VERSION "HNPBNNNYNNNNNNNNNNNNNNNNNNNNNNNNYNYYYYYYYY>4>%%%/4>'%**4YYY///"

NS_ :

BS_:

BU_: TPM TCM SCCM RF_HUB PTS ORC IC HaLF ETM ESM ESC EPS ECM Diagnost DTCM DASM CBC AFLS ADCM

BO_ 999 BU_NET_CFG_PT: 8 RF_HUB
 SG_ BU_NET_CFG_STAT_PT : 0|2@1+ (1,0) [0|0] ""  CBC
 SG_ BU_NetCfg_ACC : 2|1@1+ (1,0) [0|0] ""  CBC
 SG_ BU_NetCfg_ADCM : 3|1@1+ (1,0) [0|0] ""  CBC
 SG_ BU_NetCfg_AHLM : 4|1@1+ (1,0) [0|0] ""  CBC
 SG_ BU_NetCfg_VSIM_C : 5|1@1+ (1,0) [0|0] ""  CBC
 SG_ BU_NetCfg_ASCM : 6|1@1+ (1,0) [0|0] ""  CBC
 SG_ BU_NetCfg_CBC_PT : 7|1@1+ (1,0) [0|0] ""  CBC
 SG_ BU_NetCfg_DTCM : 8|1@1+ (1,0) [0|0] ""  CBC
 SG_ BU_NetCfg_ECM : 9|1@1+ (1,0) [0|0] ""  CBC
 SG_ BU_NetCfg_EPS : 10|1@1+ (1,0) [0|0] ""  CBC
 SG_ BU_NetCfg_ESM : 11|1@1+ (1,0) [0|0] ""  CBC
 SG_ BU_NetCfg_ESC : 12|1@1+ (1,0) [0|0] ""  CBC
 SG_ BU_NetCfg_EPB : 13|1@1+ (1,0) [0|0] ""  CBC
 SG_ BU_NetCfg_RF_HUB : 14|1@1+ (1,0) [0|0] ""  CBC
 SG_ BU_NetCfg_IC : 15|1@1+ (1,0) [0|0] ""  CBC
 SG_ BU_NetCfg_DASM : 16|1@1+ (1,0) [0|0] ""  CBC
 SG_ BU_NetCfg_FDCM : 17|1@1+ (1,0) [0|0] ""  CBC
 SG_ BU_NetCfg_EPPM : 18|1@1+ (1,0) [0|0] ""  CBC
 SG_ BU_NetCfg_ORC : 19|1@1+ (1,0) [0|0] ""  CBC
 SG_ BU_NetCfg_PTS : 20|1@1+ (1,0) [0|0] ""  CBC
 SG_ BU_NetCfg_RBT_DR : 21|1@1+ (1,0) [0|0] ""  CBC
 SG_ BU_NetCfg_RBT_PASS : 22|1@1+ (1,0) [0|0] ""  CBC
 SG_ BU_NetCfg_SCCM : 23|1@1+ (1,0) [0|0] ""  CBC
 SG_ BU_NetCfg_ELSD : 24|1@1+ (1,0) [0|0] ""  CBC
 SG_ BU_NetCfg_TCM : 25|1@1+ (1,0) [0|0] ""  CBC
 SG_ BU_NetCfg_TPM : 26|1@1+ (1,0) [0|0] ""  CBC
 SG_ BU_NetCfg_PASS_PT : 27|1@1+ (1,0) [0|0] ""  CBC
 SG_ BU_NetCfg_AFLS : 28|1@1+ (1,0) [0|0] ""  CBC
 SG_ BU_NetCfg_ITBM : 29|1@1+ (1,0) [0|0] ""  CBC
 SG_ BU_NetCfg_OCM : 30|1@1+ (1,0) [0|0] ""  CBC
 SG_ BU_NetCfg_HaLF : 31|1@1+ (1,0) [0|0] ""  CBC
 SG_ BU_NetCfg_ANC : 39|1@1+ (1,0) [0|0] ""  CBC

BO_ 1000 VehCfg1: 8 CBC
 SG_ VC_VehCfg1_Stat : 0|2@1+ (1,0) [0|0] ""  HaLF,ORC,ADCM,DTCM,ESM,TCM,ECM,DASM,ESC,SCCM,EPS,AFLS,TPM,PTS,IC,RF_HUB
 SG_ VC_MODEL_YEAR : 2|6@1+ (1,2000) [2000|2062] "model-year"  HaLF,ORC,ADCM,DTCM,ESM,TCM,ECM,DASM,ESC,SCCM,EPS,AFLS,TPM,PTS,IC,RF_HUB
 SG_ VC_VEH_LINE : 8|8@1+ (1,0) [0|0] ""  HaLF,ORC,ADCM,DTCM,ESM,TCM,ECM,DASM,ESC,SCCM,EPS,AFLS,TPM,PTS,IC,RF_HUB
 SG_ VC_COUNTRY : 16|5@1+ (1,0) [0|0] ""  HaLF,ORC,ADCM,DTCM,ESM,TCM,ECM,DASM,ESC,SCCM,EPS,AFLS,TPM,PTS,IC,RF_HUB
 SG_ VC_LHD_RHD : 21|2@1+ (1,0) [0|0] ""  HaLF,ORC,DTCM,ESM,DASM,ESC,AFLS,IC,RF_HUB
 SG_ VC_RemStPrsnt : 23|1@1+ (1,0) [0|0] ""  TCM,TPM,IC,RF_HUB
 SG_ VC_XWD : 24|2@1+ (1,0) [0|0] ""  HaLF,ORC,DTCM,ESM,TCM,ECM,DASM,ESC,EPS,IC,RF_HUB
 SG_ VC_EmodePrsnt : 26|1@1+ (1,0) [0|0] ""  TCM,RF_HUB
 SG_ VC_AUTO_HB : 27|1@1+ (1,0) [0|0] ""  IC,RF_HUB
 SG_ VC_BODY_STYLE : 28|4@1+ (1,0) [0|0] ""  HaLF,ORC,ADCM,DTCM,ESM,TCM,ECM,DASM,ESC,SCCM,EPS,AFLS,TPM,PTS,IC,RF_HUB
 SG_ VC_MAX_VEH_SPD : 32|8@1+ (2,0) [0|506] "kph"  ECM,DASM,RF_HUB
 SG_ VC_ShftrTyp : 40|4@1+ (1,0) [0|0] ""  ESM,TCM,ECM,IC,RF_HUB
 SG_ VC_PTS_DispTyp : 44|3@1+ (1,0) [0|0] ""  PTS,RF_HUB
 SG_ VC_PP_Prsnt : 47|1@1+ (1,0) [0|0] ""  IC,RF_HUB
 SG_ VC_SpecialPKG : 48|8@1+ (1,0) [1|254] ""  ORC,IC,RF_HUB
 SG_ VC_HdRstPrsnt : 56|1@1+ (1,0) [0|0] ""  RF_HUB
 SG_ VC_SCR_Prsnt : 57|1@1+ (1,0) [0|0] ""  ECM,IC,RF_HUB
 SG_ VC_PTS_Config : 58|2@1+ (1,0) [0|0] ""  PTS,IC,RF_HUB
 SG_ VC_RVCM_Prsnt : 60|1@1+ (1,0) [0|0] ""  RF_HUB
 SG_ VC_CHMCM_Prsnt : 61|1@1+ (1,0) [0|0] ""  RF_HUB
 SG_ VC_HDC_Prsnt : 62|1@1+ (1,0) [0|0] ""  ESC,IC,RF_HUB
 SG_ VC_SSC_Prsnt : 63|1@1+ (1,0) [0|0] ""  ESC,IC,RF_HUB

BO_ 1001 VehCfg2: 8 CBC
 SG_ VC_VehCfg2_Stat : 0|2@1+ (1,0) [0|0] ""  ORC,ADCM,TCM,ECM,DASM,ESC,SCCM,EPS,TPM,IC,RF_HUB
 SG_ VC_PwrIvtrTyp : 2|2@1+ (1,0) [0|0] ""  RF_HUB
 SG_ VC_ThatchamPrsnt : 4|1@1+ (1,0) [0|0] ""  IC,RF_HUB
 SG_ VC_RunFlatTirePrsnt : 5|1@1+ (1,0) [0|0] ""  TPM,IC,RF_HUB
 SG_ VC_MaseratiMd : 6|2@1+ (1,0) [0|0] ""  TCM,RF_HUB
 SG_ VC_PADS_Prsnt : 8|1@1+ (1,0) [0|0] ""  ORC,RF_HUB
 SG_ VC_RainSnsPrsnt : 9|1@1+ (1,0) [0|0] ""  IC,RF_HUB
 SG_ VC_SKIM_PRSNT : 10|1@1+ (1,0) [0|0] ""  RF_HUB
 SG_ VC_AC_Prsnt : 11|1@1+ (1,0) [0|0] ""  RF_HUB
 SG_ VC_CRUISE_PRSNT : 12|1@1+ (1,0) [0|0] ""  TCM,DASM,SCCM,IC,RF_HUB
 SG_ VC_FG_PRSNT : 13|1@1+ (1,0) [0|0] ""  IC,RF_HUB
 SG_ VC_FULL_SPARE : 14|1@1+ (1,0) [0|0] ""  TPM,RF_HUB
 SG_ VC_OffRoad : 15|1@1+ (1,0) [0|0] ""  IC,RF_HUB
 SG_ VC_SpecialPKG_IC : 16|8@1+ (1,0) [0|0] ""  IC,RF_HUB
 SG_ VC_ECO_Indicator : 24|1@1+ (1,0) [0|0] ""  IC,RF_HUB
 SG_ VC_DRVMD_Prsnt : 25|1@1+ (1,0) [0|0] ""  ADCM,ECM,ESC,EPS,RF_HUB
 SG_ VC_MemoryDRVMD_Prsnt : 26|1@1+ (1,0) [0|0] ""  ADCM,ECM,ESC,EPS,RF_HUB
 SG_ VC_ESCDrvMd_Prsnt : 27|1@1+ (1,0) [0|0] ""  ESC,IC,RF_HUB
 SG_ VC_EngPowerDrvMd_Prsnt : 28|1@1+ (1,0) [0|0] ""  ECM,IC,RF_HUB
 SG_ VC_SecPrkPrsnt : 29|1@1+ (1,0) [0|0] ""  IC,RF_HUB
 SG_ VC_ShftInd_Prsnt : 30|2@1+ (1,0) [0|0] ""  ECM,IC,RF_HUB
 SG_ VC_MaxLdPressRrTr : 32|8@1+ (1,0) [0|126] "psi"  TPM,IC,RF_HUB
 SG_ VC_MaxLdPressFtTr : 40|8@1+ (1,0) [0|126] "psi"  TPM,IC,RF_HUB
 SG_ VC_LgtLdPressRrTr : 48|8@1+ (1,0) [0|126] "psi"  TPM,IC,RF_HUB
 SG_ VC_LgtLdPressFtTr : 56|8@1+ (1,0) [0|126] "psi"  TPM,IC,RF_HUB

BO_ 1002 VehCfg3: 8 CBC
 SG_ VC_VehCfg3_Stat : 0|2@1+ (1,0) [0|0] ""  HaLF,ORC,DTCM,TCM,DASM,ESC,SCCM,EPS,TPM,PTS,IC,RF_HUB
 SG_ VC_POLICE : 2|1@1+ (1,0) [0|0] ""  ORC,IC,RF_HUB
 SG_ VC_PWR_LFT_GT : 3|1@1+ (1,0) [0|0] ""  RF_HUB
 SG_ VC_PWR_RT_SLDR : 4|1@1+ (1,0) [0|0] ""  RF_HUB
 SG_ VC_PWR_LT_SLDR : 5|1@1+ (1,0) [0|0] ""  RF_HUB
 SG_ VC_RKE_PRSNT : 6|1@1+ (1,0) [0|0] ""  IC,RF_HUB
 SG_ VC_SunShade_Present : 7|1@1+ (1,0) [0|0] ""  RF_HUB
 SG_ VC_TcaseTyp : 8|4@1+ (1,0) [0|0] ""  DTCM,ESC,RF_HUB
 SG_ VC_WHL_BASE : 12|2@1+ (1,0) [0|0] ""  ORC,RF_HUB
 SG_ VC_FOBIKsafeENBL : 14|1@1+ (1,0) [0|0] ""  RF_HUB
 SG_ VC_ELV_Prsnt : 15|1@1+ (1,0) [0|0] ""  RF_HUB
 SG_ VC_FUEL_CAP : 16|8@1+ (1,36) [36|290] "liters"  IC,RF_HUB
 SG_ VC_WIN_EXPR_FEAT : 24|2@1+ (1,0) [0|0] ""  RF_HUB
 SG_ VC_ADJ_PDL_PRSNT : 26|1@1+ (1,0) [0|0] ""  RF_HUB
 SG_ VC_AUTO_HL : 27|1@1+ (1,0) [0|0] ""  IC,RF_HUB
 SG_ VC_DrAlrPrsnt : 28|1@1+ (1,0) [0|0] ""  IC,RF_HUB
 SG_ VC_DualFuelSens : 29|1@1+ (1,0) [0|0] ""  IC,RF_HUB
 SG_ VC_SRT_PRSNT : 30|1@1+ (1,0) [0|0] ""  ORC,TCM,TPM,PTS,IC,RF_HUB
 SG_ VC_DSBL_CLK_DISP : 31|1@1+ (1,0) [0|0] ""  IC,RF_HUB
 SG_ VC_ChassisType : 32|7@1+ (1,0) [0|126] ""  ORC,DTCM,ESC,EPS,PTS,RF_HUB
 SG_ VC_TEMP_DISP : 39|1@1+ (1,0) [0|0] ""  IC,RF_HUB
 SG_ VC_HVAC_Config : 40|4@1+ (1,0) [0|0] ""  RF_HUB
 SG_ VC_VEH_BRAND : 44|4@1+ (1,0) [0|0] ""  TPM,PTS,IC,RF_HUB
 SG_ VC_CMP_DISP : 48|1@1+ (1,0) [0|0] ""  IC,RF_HUB
 SG_ VC_IntEC_MIRR : 49|1@1+ (1,0) [0|0] ""  RF_HUB
 SG_ VC_ESCL_PRSNT : 50|1@1+ (1,0) [0|0] ""  RF_HUB
 SG_ VC_HID_HL : 51|1@1+ (1,0) [0|0] ""  RF_HUB
 SG_ VC_SecLkPrsnt : 52|1@1+ (1,0) [0|0] ""  RF_HUB
 SG_ VC_Liftgate_Trunk : 53|2@1+ (1,0) [0|0] ""  IC,RF_HUB
 SG_ VC_CMS : 55|1@1+ (1,0) [0|0] ""  DASM,RF_HUB
 SG_ VC_FCW : 56|1@1+ (1,0) [0|0] ""  HaLF,DASM,RF_HUB
 SG_ VC_Base_TPM : 57|1@1+ (1,0) [0|0] ""  TPM,IC,RF_HUB
 SG_ VC_Prem_TPM : 58|1@1+ (1,0) [0|0] ""  TPM,IC,RF_HUB
 SG_ VC_PDDL_PRSNT : 59|1@1+ (1,0) [0|0] ""  TCM,SCCM,IC,RF_HUB
 SG_ VC_SPORT_PRSNT : 60|1@1+ (1,0) [0|0] ""  TCM,IC,RF_HUB
 SG_ VC_AutoParkPrsnt : 61|1@1+ (1,0) [0|0] ""  IC,RF_HUB
 SG_ VC_PE_Prsnt : 62|1@1+ (1,0) [0|0] ""  IC,RF_HUB
 SG_ VC_KG_Prsnt : 63|1@1+ (1,0) [0|0] ""  TCM,IC,RF_HUB

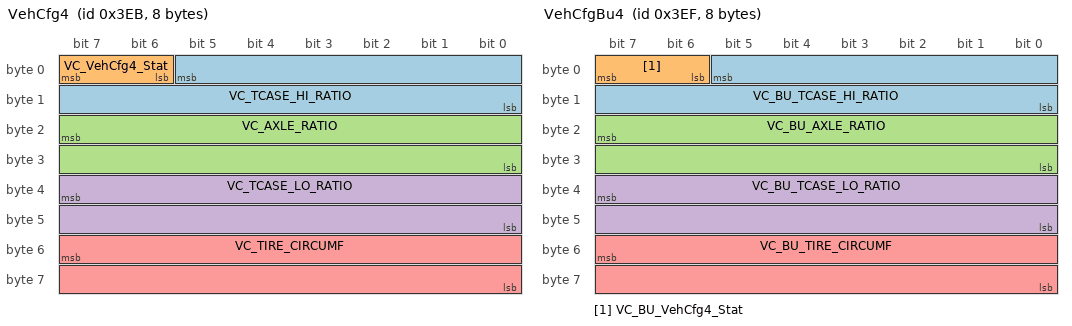
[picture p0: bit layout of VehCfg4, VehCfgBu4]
BO_ 1003 VehCfg4: 8 CBC
 SG_ VC_TCASE_HI_RATIO : 5|14@0+ (0.001,0) [0|16.382] ""  TCM,ECM,ESC,RF_HUB
 SG_ VC_VehCfg4_Stat : 6|2@1+ (1,0) [0|0] ""  ORC,DTCM,TCM,ECM,DASM,ESC,EPS,RF_HUB
 SG_ VC_AXLE_RATIO : 23|16@0+ (0.001,0) [0|65.534] ""  DTCM,TCM,ECM,DASM,ESC,RF_HUB
 SG_ VC_TCASE_LO_RATIO : 39|16@0+ (0.001,0) [0|65.534] ""  TCM,ECM,ESC,RF_HUB
 SG_ VC_TIRE_CIRCUMF : 55|16@0+ (1,0) [0|65534] "mm"  ORC,DTCM,ECM,DASM,ESC,EPS,RF_HUB

BO_ 1004 VehCfgBu1: 8 RF_HUB
 SG_ VC_BU_VehCfg1_Stat : 0|2@1+ (1,0) [0|0] ""  CBC
 SG_ VC_BU_MODEL_YEAR : 2|6@1+ (1,2000) [2000|2062] "model-year"  CBC
 SG_ VC_BU_VEH_LINE : 8|8@1+ (1,0) [0|0] ""  CBC
 SG_ VC_BU_COUNTRY : 16|5@1+ (1,0) [0|0] ""  CBC
 SG_ VC_BU_LHD_RHD : 21|2@1+ (1,0) [0|0] ""  CBC
 SG_ VC_BU_RemStPrsnt : 23|1@1+ (1,0) [0|0] ""  CBC
 SG_ VC_BU_XWD : 24|2@1+ (1,0) [0|0] ""  CBC
 SG_ VC_BU_EmodePrsnt : 26|1@1+ (1,0) [0|0] ""  CBC
 SG_ VC_BU_AUTO_HB : 27|1@1+ (1,0) [0|0] ""  CBC
 SG_ VC_BU_BODY_STYLE : 28|4@1+ (1,0) [0|0] ""  CBC
 SG_ VC_BU_MAX_VEH_SPD : 32|8@1+ (2,0) [0|506] "kph"  CBC
 SG_ VC_BU_ShftrTyp : 40|4@1+ (1,0) [0|0] ""  CBC
 SG_ VC_BU_PTS_DispTyp : 44|3@1+ (1,0) [0|0] ""  CBC
 SG_ VC_BU_PP_Prsnt : 47|1@1+ (1,0) [0|0] ""  CBC
 SG_ VC_BU_SpecialPKG : 48|8@1+ (1,0) [1|254] ""  CBC
 SG_ VC_BU_HdRstPrsnt : 56|1@1+ (1,0) [0|0] ""  CBC
 SG_ VC_BU_SCR_Prsnt : 57|1@1+ (1,0) [0|0] ""  CBC
 SG_ VC_BU_PTS_Config : 58|2@1+ (1,0) [0|0] ""  CBC
 SG_ VC_BU_RVCM_Prsnt : 60|1@1+ (1,0) [0|0] ""  CBC
 SG_ VC_BU_CHMCM_Prsnt : 61|1@1+ (1,0) [0|0] ""  CBC
 SG_ VC_BU_HDC_Prsnt : 62|1@1+ (1,0) [0|0] ""  CBC
 SG_ VC_BU_SSC_Prsnt : 63|1@1+ (1,0) [0|0] ""  CBC

BO_ 1005 VehCfgBu2: 8 RF_HUB
 SG_ VC_BU_VehCfg2_Stat : 0|2@1+ (1,0) [0|0] ""  CBC
 SG_ VC_BU_PwrIvtrTyp : 2|2@1+ (1,0) [0|0] ""  CBC
 SG_ VC_BU_ThatchamPrsnt : 4|1@1+ (1,0) [0|0] ""  CBC
 SG_ VC_BU_RunFlatTirePrsnt : 5|1@1+ (1,0) [0|0] ""  CBC
 SG_ VC_BU_MaseratiMd : 6|2@1+ (1,0) [0|0] ""  CBC
 SG_ VC_BU_PADS_Prsnt : 8|1@1+ (1,0) [0|0] ""  CBC
 SG_ VC_BU_RainSnsPrsnt : 9|1@1+ (1,0) [0|0] ""  CBC
 SG_ VC_BU_SKIM_PRSNT : 10|1@1+ (1,0) [0|0] ""  CBC
 SG_ VC_BU_AC_Prsnt : 11|1@1+ (1,0) [0|0] ""  CBC
 SG_ VC_BU_CRUISE_PRSNT : 12|1@1+ (1,0) [0|0] ""  CBC
 SG_ VC_BU_FG_PRSNT : 13|1@1+ (1,0) [0|0] ""  CBC
 SG_ VC_BU_FULL_SPARE : 14|1@1+ (1,0) [0|0] ""  CBC
 SG_ VC_BU_OffRoad : 15|1@1+ (1,0) [0|0] ""  CBC
 SG_ VC_BU_SpecialPKG_IC : 16|8@1+ (1,0) [0|0] ""  CBC
 SG_ VC_BU_ECO_Indicator : 24|1@1+ (1,0) [0|0] ""  CBC
 SG_ VC_BU_DRVMD_Prsnt : 25|1@1+ (1,0) [0|0] ""  CBC
 SG_ VC_BU_MemoryDRVMD_Prsnt : 26|1@1+ (1,0) [0|0] ""  CBC
 SG_ VC_BU_ESCDrvMd_Prsnt : 27|1@1+ (1,0) [0|0] ""  CBC
 SG_ VC_BU_EngPowerDrvMd_Prsnt : 28|1@1+ (1,0) [0|0] ""  CBC
 SG_ VC_BU_SecPrkPrsnt : 29|1@1+ (1,0) [0|0] ""  CBC
 SG_ VC_BU_ShftInd_Prsnt : 30|2@1+ (1,0) [0|0] ""  CBC
 SG_ VC_BU_MaxLdPressRrTr : 32|8@1+ (1,0) [0|126] "psi"  CBC
 SG_ VC_BU_MaxLdPressFtTr : 40|8@1+ (1,0) [0|126] "psi"  CBC
 SG_ VC_BU_LgtLdPressRrTr : 48|8@1+ (1,0) [0|126] "psi"  CBC
 SG_ VC_BU_LgtLdPressFtTr : 56|8@1+ (1,0) [0|126] "psi"  CBC

BO_ 1006 VehCfgBu3: 8 RF_HUB
 SG_ VC_BU_VehCfg3_Stat : 0|2@1+ (1,0) [0|0] ""  CBC
 SG_ VC_BU_POLICE : 2|1@1+ (1,0) [0|0] ""  CBC
 SG_ VC_BU_PWR_LFT_GT : 3|1@1+ (1,0) [0|0] ""  CBC
 SG_ VC_BU_PWR_RT_SLDR : 4|1@1+ (1,0) [0|0] ""  CBC
 SG_ VC_BU_PWR_LT_SLDR : 5|1@1+ (1,0) [0|0] ""  CBC
 SG_ VC_BU_RKE_PRSNT : 6|1@1+ (1,0) [0|0] ""  CBC
 SG_ VC_BU_SunShade_Present : 7|1@1+ (1,0) [0|0] ""  CBC
 SG_ VC_BU_TcaseTyp : 8|4@1+ (1,0) [0|0] ""  CBC
 SG_ VC_BU_WHL_BASE : 12|2@1+ (1,0) [0|0] ""  CBC
 SG_ VC_BU_FOBIKsafeENBL : 14|1@1+ (1,0) [0|0] ""  CBC
 SG_ VC_BU_ELV_PRSNT : 15|1@1+ (1,0) [0|0] ""  CBC
 SG_ VC_BU_FUEL_CAP : 16|8@1+ (1,36) [36|290] "liters"  CBC
 SG_ VC_BU_WIN_EXPR_FEAT : 24|2@1+ (1,0) [0|0] ""  CBC
 SG_ VC_BU_ADJ_PDL_PRSNT : 26|1@1+ (1,0) [0|0] ""  CBC
 SG_ VC_BU_AUTO_HL : 27|1@1+ (1,0) [0|0] ""  CBC
 SG_ VC_BU_DrAlrPrsnt : 28|1@1+ (1,0) [0|0] ""  CBC
 SG_ VC_BU_DualFuelSens : 29|1@1+ (1,0) [0|0] ""  CBC
 SG_ VC_BU_SRT_PRSNT : 30|1@1+ (1,0) [0|0] ""  CBC
 SG_ VC_BU_DSBL_CLK_DISP : 31|1@1+ (1,0) [0|0] ""  CBC
 SG_ VC_BU_ChassisType : 32|7@1+ (1,0) [0|126] ""  CBC
 SG_ VC_BU_TEMP_DISP : 39|1@1+ (1,0) [0|0] ""  CBC
 SG_ VC_BU_HVAC_Config : 40|4@1+ (1,0) [0|0] ""  CBC
 SG_ VC_BU_VEH_BRAND : 44|4@1+ (1,0) [0|0] ""  CBC
 SG_ VC_BU_CMP_DISP : 48|1@1+ (1,0) [0|0] ""  CBC
 SG_ VC_BU_IntEC_MIRR : 49|1@1+ (1,0) [0|0] ""  CBC
 SG_ VC_BU_ESCL_Prsnt : 50|1@1+ (1,0) [0|0] ""  CBC
 SG_ VC_BU_HID_HL : 51|1@1+ (1,0) [0|0] ""  CBC
 SG_ VC_BU_SecLkPrsnt : 52|1@1+ (1,0) [0|0] ""  CBC
 SG_ VC_BU_Liftgate_Trunk : 53|2@1+ (1,0) [0|0] ""  CBC
 SG_ VC_BU_CMS : 55|1@1+ (1,0) [0|0] ""  CBC
 SG_ VC_BU_FCW : 56|1@1+ (1,0) [0|0] ""  CBC
 SG_ VC_BU_Base_TPM : 57|1@1+ (1,0) [0|0] ""  CBC
 SG_ VC_BU_Prem_TPM : 58|1@1+ (1,0) [0|0] ""  CBC
 SG_ VC_BU_PDDL_PRSNT : 59|1@1+ (1,0) [0|0] ""  CBC
 SG_ VC_BU_SPORT_PRSNT : 60|1@1+ (1,0) [0|0] ""  CBC
 SG_ VC_BU_AutoParkPrsnt : 61|1@1+ (1,0) [0|0] ""  CBC
 SG_ VC_BU_PE_Prsnt : 62|1@1+ (1,0) [0|0] ""  CBC
 SG_ VC_BU_KG_Prsnt : 63|1@1+ (1,0) [0|0] ""  CBC

BO_ 1007 VehCfgBu4: 8 RF_HUB
 SG_ VC_BU_TCASE_HI_RATIO : 5|14@0+ (0.001,0) [0|16.382] ""  CBC
 SG_ VC_BU_VehCfg4_Stat : 6|2@1+ (1,0) [0|0] ""  CBC
 SG_ VC_BU_AXLE_RATIO : 23|16@0+ (0.001,0) [0|65.534] ""  CBC
 SG_ VC_BU_TCASE_LO_RATIO : 39|16@0+ (0.001,0) [0|65.534] ""  CBC
 SG_ VC_BU_TIRE_CIRCUMF : 55|16@0+ (1,0) [0|65534] "mm"  CBC

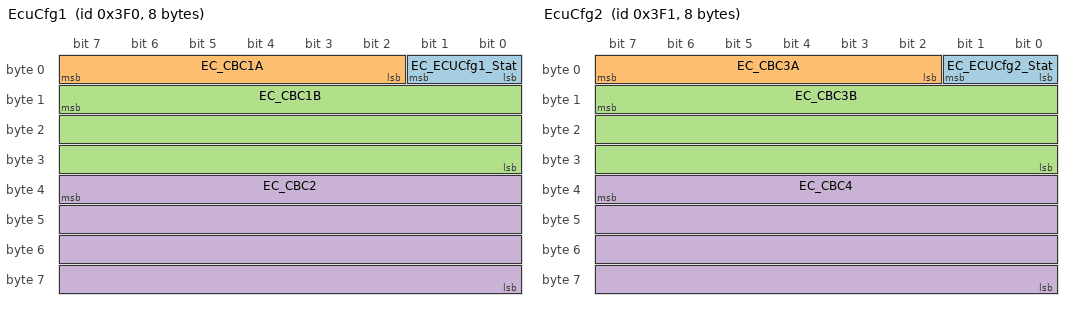
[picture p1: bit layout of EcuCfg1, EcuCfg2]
BO_ 1008 EcuCfg1: 8 CBC
 SG_ EC_ECUCfg1_Stat : 0|2@1+ (1,0) [0|0] ""  RF_HUB
 SG_ EC_CBC1A : 2|6@1+ (1,0) [0|0] ""  RF_HUB
 SG_ EC_CBC1B : 15|24@0+ (1,0) [0|0] ""  RF_HUB
 SG_ EC_CBC2 : 39|32@0+ (1,0) [0|0] ""  RF_HUB

BO_ 1009 EcuCfg2: 8 CBC
 SG_ EC_ECUCfg2_Stat : 0|2@1+ (1,0) [0|0] ""  RF_HUB
 SG_ EC_CBC3A : 2|6@1+ (1,0) [0|0] ""  RF_HUB
 SG_ EC_CBC3B : 15|24@0+ (1,0) [0|0] ""  RF_HUB
 SG_ EC_CBC4 : 39|32@0+ (1,0) [0|0] ""  RF_HUB

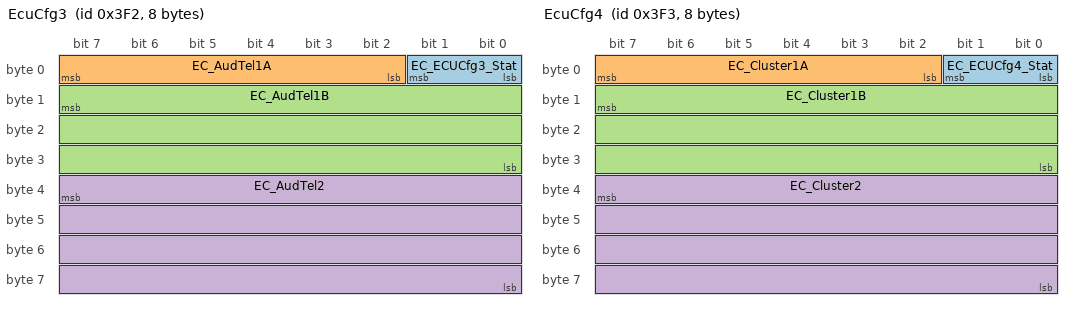
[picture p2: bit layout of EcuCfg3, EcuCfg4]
BO_ 1010 EcuCfg3: 8 CBC
 SG_ EC_ECUCfg3_Stat : 0|2@1+ (1,0) [0|0] ""  RF_HUB
 SG_ EC_AudTel1A : 2|6@1+ (1,0) [0|0] ""  RF_HUB
 SG_ EC_AudTel1B : 15|24@0+ (1,0) [0|0] ""  RF_HUB
 SG_ EC_AudTel2 : 39|32@0+ (1,0) [0|0] ""  RF_HUB

BO_ 1011 EcuCfg4: 8 CBC
 SG_ EC_ECUCfg4_Stat : 0|2@1+ (1,0) [0|0] ""  IC,RF_HUB
 SG_ EC_Cluster1A : 2|6@1+ (1,0) [0|0] ""  IC,RF_HUB
 SG_ EC_Cluster1B : 15|24@0+ (1,0) [0|0] ""  IC,RF_HUB
 SG_ EC_Cluster2 : 39|32@0+ (1,0) [0|0] ""  IC,RF_HUB

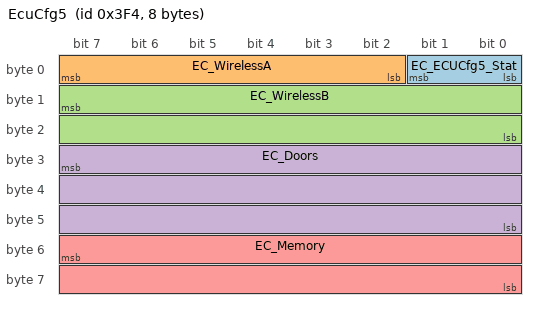
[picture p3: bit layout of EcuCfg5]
BO_ 1012 EcuCfg5: 8 CBC
 SG_ EC_ECUCfg5_Stat : 0|2@1+ (1,0) [0|0] ""  RF_HUB
 SG_ EC_WirelessA : 2|6@1+ (1,0) [0|0] ""  RF_HUB
 SG_ EC_WirelessB : 15|16@0+ (1,0) [0|0] ""  RF_HUB
 SG_ EC_Doors : 31|24@0+ (1,0) [0|0] ""  RF_HUB
 SG_ EC_Memory : 55|16@0+ (1,0) [0|0] ""  RF_HUB

CM_ SG_ 999 BU_NET_CFG_STAT_PT "Backup for network configuration status";
CM_ SG_ 999 BU_NetCfg_ACC "Backup for Active Cruise Control (1=present)";
CM_ SG_ 999 BU_NetCfg_ADCM "Backup for Active Damping Control Module (1=present)";
CM_ SG_ 999 BU_NetCfg_AHLM "Backup for Automatic Headlamp Leveling Module (1=present)";
CM_ SG_ 999 BU_NetCfg_VSIM_C "Backup for Vehicle System Interface Module (1=present)";
CM_ SG_ 999 BU_NetCfg_ASCM "Backup for Air Suspension Control Module (1=present)";
CM_ SG_ 999 BU_NetCfg_CBC_PT "Backup for Common Body Controller PT Bus (1=present)";
CM_ SG_ 999 BU_NetCfg_DTCM "Backup for Drivetrain Control Module (1=present)";
CM_ SG_ 999 BU_NetCfg_ECM "Backup for Engine Control Module (1=present)";
CM_ SG_ 999 BU_NetCfg_EPS "Backup for Electric Power Steering (1=present)";
CM_ SG_ 999 BU_NetCfg_ESM "Backup for Electronic Shift Module (1=present)";
CM_ SG_ 999 BU_NetCfg_ESC "Backup for Electronic Stability Module / Anti-Lock Brake (1=present)";
CM_ SG_ 999 BU_NetCfg_EPB "Backup for Electric Park Brake Module (1=present)";
CM_ SG_ 999 BU_NetCfg_RF_HUB "Backup for RF HUB Node (1=present)";
CM_ SG_ 999 BU_NetCfg_IC "Backup for Instrument Cluster (1=present)";
CM_ SG_ 999 BU_NetCfg_DASM "Backup for Driver Assistance System Module (1=present)";
CM_ SG_ 999 BU_NetCfg_FDCM "Backup for Final Drive Control Module (1=present)";
CM_ SG_ 999 BU_NetCfg_EPPM "Backup for  Elect. Pedestrian protection module (1=present)";
CM_ SG_ 999 BU_NetCfg_ORC "Backup for Occupant Restraint Controller (1=present)";
CM_ SG_ 999 BU_NetCfg_PTS "Backup for Parktronics System (1=present)";
CM_ SG_ 999 BU_NetCfg_RBT_DR "Backup for Belt Pre-Tensioner Driver (1=present)";
CM_ SG_ 999 BU_NetCfg_RBT_PASS "Backup for Belt Pre-Tensioner Passenger (1=present)";
CM_ SG_ 999 BU_NetCfg_SCCM "Backup for Steering Column Control Module (1=present)";
CM_ SG_ 999 BU_NetCfg_ELSD "Backup for Electric Limited Slip Differential (1=present)";
CM_ SG_ 999 BU_NetCfg_TCM "Backup for Automatic Transmission Controller (1=present)";
CM_ SG_ 999 BU_NetCfg_TPM "Backup for Tire Pressure Monitor (1=present)";
CM_ SG_ 999 BU_NetCfg_PASS_PT "Backup for Personal Assistant Safety System Module PT Bus (1=present)";
CM_ SG_ 999 BU_NetCfg_AFLS "Backup for Advanced Front Lighting System (1=present)";
CM_ SG_ 999 BU_NetCfg_ITBM "Backup for Integrated Trailer Brake Module (1=present)";
CM_ SG_ 999 BU_NetCfg_OCM "Backup for Occupant Classification Module (1=present)";
CM_ SG_ 999 BU_NetCfg_HaLF "Backup for Haptic Lane Feedback module (1=present)";
CM_ SG_ 999 BU_NetCfg_ANC "Backup for Active Noise Cancellation (1=present)";
CM_ SG_ 1000 VC_VehCfg1_Stat "Configuration messages status 1";
CM_ SG_ 1000 VC_MODEL_YEAR "Model year";
CM_ SG_ 1000 VC_VEH_LINE "Vehicle line";
CM_ SG_ 1000 VC_COUNTRY "Country Code";
CM_ SG_ 1000 VC_LHD_RHD "Left/right hand drive";
CM_ SG_ 1000 VC_RemStPrsnt "Remote start present; present = [1]";
CM_ SG_ 1000 VC_XWD "Drive configuration";
CM_ SG_ 1000 VC_EmodePrsnt "E-Mode feature present; True = [1]";
CM_ SG_ 1000 VC_AUTO_HB "Auto Highbeam feature present; present = [1]";
CM_ SG_ 1000 VC_BODY_STYLE "Body style";
CM_ SG_ 1000 VC_MAX_VEH_SPD "Maximum vehicle speed";
CM_ SG_ 1000 VC_ShftrTyp "Shifter type";
CM_ SG_ 1000 VC_PTS_DispTyp "PTS display type and location";
CM_ SG_ 1000 VC_PP_Prsnt "Performance Pages Present (1=present)";
CM_ SG_ 1000 VC_SpecialPKG "Special sales code package";
CM_ SG_ 1000 VC_HdRstPrsnt "Headrest present; present = [1]";
CM_ SG_ 1000 VC_SCR_Prsnt "Urea/SCR system present; present = [1]";
CM_ SG_ 1000 VC_PTS_Config "Parktronics system configuration";
CM_ SG_ 1000 VC_RVCM_Prsnt "Rear view camera (1=present)";
CM_ SG_ 1000 VC_CHMCM_Prsnt "CHMSL camera (1=present)";
CM_ SG_ 1000 VC_HDC_Prsnt "Hill descent feature is present; present = [1]";
CM_ SG_ 1000 VC_SSC_Prsnt "Select speed control feature is present; present = [1]";
CM_ SG_ 1001 VC_VehCfg2_Stat "Configuration messages status 2";
CM_ SG_ 1001 VC_PwrIvtrTyp "Power inverter type";
CM_ SG_ 1001 VC_ThatchamPrsnt "Thatcham present; present = [1]";
CM_ SG_ 1001 VC_RunFlatTirePrsnt "Run flat tires present; present = [1]";
CM_ SG_ 1001 VC_MaseratiMd "Maserati vehicle mode";
CM_ SG_ 1001 VC_PADS_Prsnt "Pass. airbag disable switch present; present = [1]";
CM_ SG_ 1001 VC_RainSnsPrsnt "Rain sensor present; present = [1]";
CM_ SG_ 1001 VC_SKIM_PRSNT "SKIM system present; present = [1]";
CM_ SG_ 1001 VC_AC_Prsnt "Vehicle is equipped with air conditioning; present = [1]";
CM_ SG_ 1001 VC_CRUISE_PRSNT "Cruise feature is present; present = [1]";
CM_ SG_ 1001 VC_FG_PRSNT "Flipper glass present; present = [1]";
CM_ SG_ 1001 VC_FULL_SPARE "Full size spare; present = [1]";
CM_ SG_ 1001 VC_OffRoad "Off road capable; present = [1]";
CM_ SG_ 1001 VC_SpecialPKG_IC "Special sales code package";
CM_ SG_ 1001 VC_ECO_Indicator "ECO Indicator present on vehicle; True = [1]";
CM_ SG_ 1001 VC_DRVMD_Prsnt "Drive mode feature configuration (1 = Present)";
CM_ SG_ 1001 VC_MemoryDRVMD_Prsnt "Memory drive mode sub-feature configuration (1 = Present)";
CM_ SG_ 1001 VC_ESCDrvMd_Prsnt "ESC drive mode sub-feature configuration (1 = Present)";
CM_ SG_ 1001 VC_EngPowerDrvMd_Prsnt "ECM drive mode sub-feature configuration (1 = Present)";
CM_ SG_ 1001 VC_SecPrkPrsnt "Secure park feature present; present = [1]";
CM_ SG_ 1001 VC_ShftInd_Prsnt "Configuration for performance & gear shift indication";
CM_ SG_ 1001 VC_MaxLdPressRrTr "Max Load Inflation Pressure Rear Tire";
CM_ SG_ 1001 VC_MaxLdPressFtTr "Max Load Inflation Pressure Front Tire";
CM_ SG_ 1001 VC_LgtLdPressRrTr "Light Load Inflation Pressure Rear Tire";
CM_ SG_ 1001 VC_LgtLdPressFtTr "Light Load Inflation Pressure Front Tire";
CM_ SG_ 1002 VC_VehCfg3_Stat "Configuration messages status 3";
CM_ SG_ 1002 VC_POLICE "Police lighting feature; present = [1]";
CM_ SG_ 1002 VC_PWR_LFT_GT "Power lift gate present; present = [1]";
CM_ SG_ 1002 VC_PWR_RT_SLDR "Power right sliding door present; present = [1]";
CM_ SG_ 1002 VC_PWR_LT_SLDR "Power left sliding door present; present = [1]";
CM_ SG_ 1002 VC_RKE_PRSNT "RKE system present; present = [1]";
CM_ SG_ 1002 VC_SunShade_Present "Vehicle equipped w/SunShade (1=present)";
CM_ SG_ 1002 VC_TcaseTyp "Tcase type";
CM_ SG_ 1002 VC_WHL_BASE "Wheel base";
CM_ SG_ 1002 VC_FOBIKsafeENBL "Feature FOBIK safe is enabled; present = [1]";
CM_ SG_ 1002 VC_ELV_Prsnt "ELV system present; enabled=[1], disabled=[0]";
CM_ SG_ 1002 VC_FUEL_CAP "Fuel capacity";
CM_ SG_ 1002 VC_WIN_EXPR_FEAT "Window express feature configuration";
CM_ SG_ 1002 VC_ADJ_PDL_PRSNT "Adjustable pedal system present (non-memory); present = [1]";
CM_ SG_ 1002 VC_AUTO_HL "Auto headlamp feature present; present = [1]";
CM_ SG_ 1002 VC_DrAlrPrsnt "Door alert feature present; present = [1]";
CM_ SG_ 1002 VC_DualFuelSens "Vehicle equipped with two fuel sending units; present = [1]";
CM_ SG_ 1002 VC_SRT_PRSNT "Vehicle is an SRT; present = [1]";
CM_ SG_ 1002 VC_DSBL_CLK_DISP "Disable display of radio clock; 1 = clock display disabled";
CM_ SG_ 1002 VC_ChassisType "Chassis type (including suspension, brakes, and tires)";
CM_ SG_ 1002 VC_TEMP_DISP "Display outside temperature present; present = [1]";
CM_ SG_ 1002 VC_HVAC_Config "HVAC Configuration";
CM_ SG_ 1002 VC_VEH_BRAND "Vehicle brand type";
CM_ SG_ 1002 VC_CMP_DISP "Display compass heading present; present = [1]";
CM_ SG_ 1002 VC_IntEC_MIRR "Vehicle is equipped with an interior EC mirror; present = [1]";
CM_ SG_ 1002 VC_ESCL_PRSNT "ESCL system present; enabled=[1], disabled=[0]";
CM_ SG_ 1002 VC_HID_HL "High intensity discharge head lamps; present = [1]";
CM_ SG_ 1002 VC_SecLkPrsnt "Secondary Lock Present; [1] = True";
CM_ SG_ 1002 VC_Liftgate_Trunk "Liftgate or trunk";
CM_ SG_ 1002 VC_CMS "Collision Mitigation System present; present = [1]";
CM_ SG_ 1002 VC_FCW "Forward Collision Warning present; present = [1]";
CM_ SG_ 1002 VC_Base_TPM "Base TPM system present; present = [1]";
CM_ SG_ 1002 VC_Prem_TPM "Premium TPM system present; present = [1]";
CM_ SG_ 1002 VC_PDDL_PRSNT "Paddle shift feature is present; present = [1]";
CM_ SG_ 1002 VC_SPORT_PRSNT "Sport mode is present; present = [1]";
CM_ SG_ 1002 VC_AutoParkPrsnt "Automatic transmission parking feature is present; present = [1]";
CM_ SG_ 1002 VC_PE_Prsnt "Feature passive entry is present; present = [1]";
CM_ SG_ 1002 VC_KG_Prsnt "Feature keyless go is present; present = [1]";
CM_ SG_ 1003 VC_TCASE_HI_RATIO "Transfer case high ratio";
CM_ SG_ 1003 VC_VehCfg4_Stat "Configuration messages status 4";
CM_ SG_ 1003 VC_AXLE_RATIO "Axle ratio";
CM_ SG_ 1003 VC_TCASE_LO_RATIO "Transfer case low range reduction ratio";
CM_ SG_ 1003 VC_TIRE_CIRCUMF "Dynamic tire circumference (all or rear)";
CM_ SG_ 1004 VC_BU_VehCfg1_Stat "Backup for Configuration messages status 1";
CM_ SG_ 1004 VC_BU_MODEL_YEAR "Backup for Model year";
CM_ SG_ 1004 VC_BU_VEH_LINE "Backup for Vehicle line";
CM_ SG_ 1004 VC_BU_COUNTRY "Backup for Country Code";
CM_ SG_ 1004 VC_BU_LHD_RHD "Backup for Left/right hand drive";
CM_ SG_ 1004 VC_BU_RemStPrsnt "Backup for Remote start present; present = [1]";
CM_ SG_ 1004 VC_BU_XWD "Backup for Drive configuration";
CM_ SG_ 1004 VC_BU_EmodePrsnt "Backup for E-Mode feature present; True = [1]";
CM_ SG_ 1004 VC_BU_AUTO_HB "Backup for Auto Highbeam feature present; present = [1]";
CM_ SG_ 1004 VC_BU_BODY_STYLE "Backup for Body style";
CM_ SG_ 1004 VC_BU_MAX_VEH_SPD "Backup for Maximum vehicle speed";
CM_ SG_ 1004 VC_BU_ShftrTyp "Shifter type";
CM_ SG_ 1004 VC_BU_PTS_DispTyp "PTS display type and location";
CM_ SG_ 1004 VC_BU_PP_Prsnt "Backup for Performance Pages Present (1=present)";
CM_ SG_ 1004 VC_BU_SpecialPKG "Special sales code package";
CM_ SG_ 1004 VC_BU_HdRstPrsnt "Backup for headrest present; present = [1]";
CM_ SG_ 1004 VC_BU_SCR_Prsnt "Backup for Urea/SCR system present; present = [1]";
CM_ SG_ 1004 VC_BU_PTS_Config "Backup for Parktronics system configuration";
CM_ SG_ 1004 VC_BU_RVCM_Prsnt "Backup for rear view camera (1=present)";
CM_ SG_ 1004 VC_BU_CHMCM_Prsnt "Backup for CHMSL camera (1=present)";
CM_ SG_ 1004 VC_BU_HDC_Prsnt "Backup for Hill descent feature is present; present = [1]";
CM_ SG_ 1004 VC_BU_SSC_Prsnt "Backup for Select speed control feature is present; present = [1]";
CM_ SG_ 1005 VC_BU_VehCfg2_Stat "Backup for Configuration messages status 2";
CM_ SG_ 1005 VC_BU_PwrIvtrTyp "Backup for power inverter type";
CM_ SG_ 1005 VC_BU_ThatchamPrsnt "Backup for thatcham present; present = [1]";
CM_ SG_ 1005 VC_BU_RunFlatTirePrsnt "Backup for run flat tires present; present = [1]";
CM_ SG_ 1005 VC_BU_MaseratiMd "Backup for Maserati vehicle mode";
CM_ SG_ 1005 VC_BU_PADS_Prsnt "Backup for Pass. airbag disable switch present; present = [1]";
CM_ SG_ 1005 VC_BU_RainSnsPrsnt "Backup for Rain sensor present; present = [1]";
CM_ SG_ 1005 VC_BU_SKIM_PRSNT "Backup for SKIM system present; present = [1]";
CM_ SG_ 1005 VC_BU_AC_Prsnt "Backup for Vehicle is equipped with air conditioning; present = [1]";
CM_ SG_ 1005 VC_BU_CRUISE_PRSNT "Backup for Cruise feature is present; present = [1]";
CM_ SG_ 1005 VC_BU_FG_PRSNT "Backup for Flipper glass present; present = [1]";
CM_ SG_ 1005 VC_BU_FULL_SPARE "Backup for Full size spare; present = [1]";
CM_ SG_ 1005 VC_BU_OffRoad "Backup for Off road capable; present = [1]";
CM_ SG_ 1005 VC_BU_SpecialPKG_IC "Special sales code package";
CM_ SG_ 1005 VC_BU_ECO_Indicator "Backup for ECO Indicator present on vehicle; True = [1]";
CM_ SG_ 1005 VC_BU_DRVMD_Prsnt "Backup for drive mode feature configuration (1 = Present)";
CM_ SG_ 1005 VC_BU_MemoryDRVMD_Prsnt "Backup for memory drive mode sub-feature configuration (1 = Present)";
CM_ SG_ 1005 VC_BU_ESCDrvMd_Prsnt "Backup for ESC drive mode sub-feature configuration (1 = Present)";
CM_ SG_ 1005 VC_BU_EngPowerDrvMd_Prsnt "Backup for ECM drive mode sub-feature configuration (1 = Present)";
CM_ SG_ 1005 VC_BU_SecPrkPrsnt "Backup for secure park feature present; present = [1]";
CM_ SG_ 1005 VC_BU_ShftInd_Prsnt "Backup for configuration for performance & gear shift indication";
CM_ SG_ 1005 VC_BU_MaxLdPressRrTr "Backup for Max Load Inflation Pressure Rear Tire";
CM_ SG_ 1005 VC_BU_MaxLdPressFtTr "Backup for Max Load Inflation Pressure Front Tire";
CM_ SG_ 1005 VC_BU_LgtLdPressRrTr "Backup for Light Load Inflation Pressure Rear Tire";
CM_ SG_ 1005 VC_BU_LgtLdPressFtTr "Backup for Light Load Inflation Pressure Front Tire";
CM_ SG_ 1006 VC_BU_VehCfg3_Stat "Backup for Configuration messages status 3";
CM_ SG_ 1006 VC_BU_POLICE "Backup for Police lighting feature; present = [1]";
CM_ SG_ 1006 VC_BU_PWR_LFT_GT "Backup for Power lift gate present; present = [1]";
CM_ SG_ 1006 VC_BU_PWR_RT_SLDR "Backup for Power right sliding door present; present = [1]";
CM_ SG_ 1006 VC_BU_PWR_LT_SLDR "Backup for Power left sliding door present; present = [1]";
CM_ SG_ 1006 VC_BU_RKE_PRSNT "Backup for RKE system present; present = [1]";
CM_ SG_ 1006 VC_BU_SunShade_Present "Backup for Vehicle equipped w/SunShade (1=present)";
CM_ SG_ 1006 VC_BU_TcaseTyp "Backup for Tcase type";
CM_ SG_ 1006 VC_BU_WHL_BASE "Backup for Wheel base";
CM_ SG_ 1006 VC_BU_FOBIKsafeENBL "Backup for FOBIK safe feature; present = [1]";
CM_ SG_ 1006 VC_BU_ELV_PRSNT "Backup for ELV system present; enabled=[1], disabled=[0]";
CM_ SG_ 1006 VC_BU_FUEL_CAP "Backup for Fuel capacity";
CM_ SG_ 1006 VC_BU_WIN_EXPR_FEAT "Backup for Window express feature configuration";
CM_ SG_ 1006 VC_BU_ADJ_PDL_PRSNT "Backup for Adjustable pedal system present (non-memory); present = [1]";
CM_ SG_ 1006 VC_BU_AUTO_HL "Backup for Auto headlamp feature present; present = [1]";
CM_ SG_ 1006 VC_BU_DrAlrPrsnt "Backup for Door alert feature present; present = [1]";
CM_ SG_ 1006 VC_BU_DualFuelSens "Backup for Vehicle equipped with two fuel sending units; present = [1]";
CM_ SG_ 1006 VC_BU_SRT_PRSNT "Backup for Vehicle is an SRT; present = [1]";
CM_ SG_ 1006 VC_BU_DSBL_CLK_DISP "Backup of Disable display of radio clock; 1 = clock display disabled";
CM_ SG_ 1006 VC_BU_ChassisType "Backup for chassis type (including suspension, brakes, and tires)";
CM_ SG_ 1006 VC_BU_TEMP_DISP "Backup for display outside temperature present; present = [1]";
CM_ SG_ 1006 VC_BU_HVAC_Config "Backup for HVAC Configuration";
CM_ SG_ 1006 VC_BU_VEH_BRAND "Backup for Vehicle brand type";
CM_ SG_ 1006 VC_BU_CMP_DISP "Backup for display compass heading present; present = [1]";
CM_ SG_ 1006 VC_BU_IntEC_MIRR "Backup for vehicle is equipped with an interior EC mirror; present = [1]";
CM_ SG_ 1006 VC_BU_ESCL_Prsnt "Backup for ESCL system present; enabled=[1], disabled=[0]";
CM_ SG_ 1006 VC_BU_HID_HL "Backup for High intensity discharge head lamps; present = [1]";
CM_ SG_ 1006 VC_BU_SecLkPrsnt "Backup for Secondary Lock Present; [1] = True";
CM_ SG_ 1006 VC_BU_Liftgate_Trunk "Backup for Liftgate or trunk";
CM_ SG_ 1006 VC_BU_CMS "Backup for Collision Mitigation System present; present = [1]";
CM_ SG_ 1006 VC_BU_FCW "Backup for Forward Collision Warning present; present = [1]";
CM_ SG_ 1006 VC_BU_Base_TPM "Backup for Base TPM system present; present = [1]";
CM_ SG_ 1006 VC_BU_Prem_TPM "Backup for Premium TPM system present; present = [1]";
CM_ SG_ 1006 VC_BU_PDDL_PRSNT "backup for Paddle shift feature is present; present = [1]";
CM_ SG_ 1006 VC_BU_SPORT_PRSNT "Backup for Sport mode is present; present = [1]";
CM_ SG_ 1006 VC_BU_AutoParkPrsnt "Backup for automatic transmission parking feature is present; present = [1]";
CM_ SG_ 1006 VC_BU_PE_Prsnt "Backup for passive entry is present; present = [1]";
CM_ SG_ 1006 VC_BU_KG_Prsnt "Backup for keyless go is present; present = [1]";
CM_ SG_ 1007 VC_BU_TCASE_HI_RATIO "Backup for Transfer case high ratio";
CM_ SG_ 1007 VC_BU_VehCfg4_Stat "Backup for Configuration messages status 4";
CM_ SG_ 1007 VC_BU_AXLE_RATIO "Backup for Axle ratio";
CM_ SG_ 1007 VC_BU_TCASE_LO_RATIO "Backup for Transfer case low range reduction ratio";
CM_ SG_ 1007 VC_BU_TIRE_CIRCUMF "Backup for Dynamic tire circumference (all or rear)";
CM_ SG_ 1008 EC_ECUCfg1_Stat "ECU Configuration messages status 1";
CM_ SG_ 1008 EC_CBC1A "CBC ecu configuration 1A";
CM_ SG_ 1008 EC_CBC1B "CBC ecu configuration 1B";
CM_ SG_ 1008 EC_CBC2 "CBC ecu configuration 2";
CM_ SG_ 1009 EC_ECUCfg2_Stat "ECU Configuration messages status 2";
CM_ SG_ 1009 EC_CBC3A "CBC ecu configuration 3A";
CM_ SG_ 1009 EC_CBC3B "CBC ecu configuration 3B";
CM_ SG_ 1009 EC_CBC4 "CBC ecu configuration 4";
CM_ SG_ 1010 EC_ECUCfg3_Stat "ECU Configuration messages status 3";
CM_ SG_ 1010 EC_AudTel1A "Audio and telematics ecu configuration 1A";
CM_ SG_ 1010 EC_AudTel1B "Audio and telematics ecu configuration 1B";
CM_ SG_ 1010 EC_AudTel2 "Audio and telematics ecu configuration 2";
CM_ SG_ 1011 EC_ECUCfg4_Stat "ECU Configuration messages status 4";
CM_ SG_ 1011 EC_Cluster1A "Instrument cluster ecu configuration 1A";
CM_ SG_ 1011 EC_Cluster1B "Instrument cluster ecu configuration 1B";
CM_ SG_ 1011 EC_Cluster2 "Instrument cluster ecu configuration 2";
CM_ SG_ 1012 EC_ECUCfg5_Stat "ECU Configuration messages status 5";
CM_ SG_ 1012 EC_WirelessA "Wireless ecu configurationA";
CM_ SG_ 1012 EC_WirelessB "Wireless ecu configurationB";
CM_ SG_ 1012 EC_Doors "Doors ecu configuration";
CM_ SG_ 1012 EC_Memory "Memory ecu configuration";
BA_DEF_ SG_  "GenSigTimeout_ADCM" INT 0 65535;
BA_DEF_ SG_  "GenSigTimeout_AFLS" INT 0 65535;
BA_DEF_ SG_  "GenSigTimeout_CBC" INT 0 65535;
BA_DEF_ SG_  "GenSigTimeout_DTCM" INT 0 65535;
BA_DEF_ SG_  "GenSigTimeout_ECM" INT 0 65535;
BA_DEF_ SG_  "GenSigTimeout_EPS" INT 0 65535;
BA_DEF_ SG_  "GenSigTimeout_ESC" INT 0 65535;
BA_DEF_ SG_  "GenSigTimeout_ESM" INT 0 65535;
BA_DEF_ SG_  "GenSigTimeout_ETM" INT 0 65535;
BA_DEF_ SG_  "GenSigTimeout_HaLF" INT 0 65535;
BA_DEF_ SG_  "GenSigTimeout_IC" INT 0 65535;
BA_DEF_ SG_  "GenSigTimeout_ORC" INT 0 65535;
BA_DEF_ SG_  "GenSigTimeout_PTS" INT 0 65535;
BA_DEF_ SG_  "GenSigTimeout_RF_HUB" INT 0 65535;
BA_DEF_ SG_  "GenSigTimeout_SCCM" INT 0 65535;
BA_DEF_ SG_  "GenSigTimeout_TPM" INT 0 65535;
BA_DEF_ BO_  "GenMsgStartValue" STRING ;
BA_DEF_ SG_  "GenSigSNA" STRING ;
BA_DEF_ SG_  "FlexKomIsMotorola" ENUM  "nein","ja";
BA_DEF_ SG_  "FlexKomSigLaenge" INT 0 64;
BA_DEF_ SG_  "FlexKomSigStartPos" INT 0 63;
BA_DEF_ SG_  "FlexKomComment" STRING ;
BA_DEF_ SG_  "FlexKomSigName" STRING ;
BA_DEF_ SG_  "FlexKomSID" INT 0 2147483647;
BA_DEF_ SG_  "GenSigStartValue" HEX 0 4294967295;
BA_DEF_ SG_  "FlexKomSigStartValue" STRING ;
BA_DEF_ SG_  "GenSigCycleTimeActive" INT 0 65535;
BA_DEF_ SG_  "GenSigCycleTime" INT 0 65535;
BA_DEF_ SG_  "GenSigSendType" ENUM  "cyclicX","spontanX","cyclicIfActiveX","spontanWithDelay","cyclicAndSpontanX","cyclicAndSpontanWithDelay","spontanWithRepitition","cyclicIfActiveAndSpontanWD","cyclicIfActiveFast","cyclicWithRepeatOnDemand","none";
BA_DEF_ BO_  "GenMsgNrOfRepetitions" INT 0 65535;
BA_DEF_ BO_  "GenMsgDelayTime" INT 0 65535;
BA_DEF_ BO_  "GenMsgStartDelayTime" INT 0 65535;
BA_DEF_ BO_  "GenMsgCycleTimeActive" INT 0 65535;
BA_DEF_ BO_  "GenMsgCycleTime" INT 0 65535;
BA_DEF_ BO_  "GenMsgSendType" ENUM  "cyclicX","spontanX","cyclicIfActiveX","spontanWithDelay","cyclicAndSpontanX","cyclicAndSpontanWithDelay","spontanWithRepitition","cyclicIfActiveAndSpontanWD","cyclicIfActiveFast","cyclicWithRepeatOnDemand","none";
BA_DEF_ BO_  "DiagResponse" ENUM  "nein","ja";
BA_DEF_ BO_  "DiagRequest" ENUM  "nein","ja";
BA_DEF_ BO_  "DiagState" ENUM  "nein","ja";
BA_DEF_ BO_  "App-Botschaft" ENUM  "nein","ja";
BA_DEF_ BO_  "NWM-Botschaft" ENUM  "nein","ja";
BA_DEF_DEF_  "GenSigTimeout_ADCM" 0;
BA_DEF_DEF_  "GenSigTimeout_AFLS" 0;
BA_DEF_DEF_  "GenSigTimeout_CBC" 0;
BA_DEF_DEF_  "GenSigTimeout_DTCM" 0;
BA_DEF_DEF_  "GenSigTimeout_ECM" 0;
BA_DEF_DEF_  "GenSigTimeout_EPS" 0;
BA_DEF_DEF_  "GenSigTimeout_ESC" 0;
BA_DEF_DEF_  "GenSigTimeout_ESM" 0;
BA_DEF_DEF_  "GenSigTimeout_ETM" 0;
BA_DEF_DEF_  "GenSigTimeout_HaLF" 0;
BA_DEF_DEF_  "GenSigTimeout_IC" 0;
BA_DEF_DEF_  "GenSigTimeout_ORC" 0;
BA_DEF_DEF_  "GenSigTimeout_PTS" 0;
BA_DEF_DEF_  "GenSigTimeout_RF_HUB" 0;
BA_DEF_DEF_  "GenSigTimeout_SCCM" 0;
BA_DEF_DEF_  "GenSigTimeout_TPM" 0;
BA_DEF_DEF_  "GenMsgStartValue" "";
BA_DEF_DEF_  "GenSigSNA" "";
BA_DEF_DEF_  "FlexKomIsMotorola" "nein";
BA_DEF_DEF_  "FlexKomSigLaenge" 0;
BA_DEF_DEF_  "FlexKomSigStartPos" 0;
BA_DEF_DEF_  "FlexKomComment" "";
BA_DEF_DEF_  "FlexKomSigName" "";
BA_DEF_DEF_  "FlexKomSID" 0;
BA_DEF_DEF_  "GenSigStartValue" 0;
BA_DEF_DEF_  "FlexKomSigStartValue" "";
BA_DEF_DEF_  "GenSigCycleTimeActive" 0;
BA_DEF_DEF_  "GenSigCycleTime" 0;
BA_DEF_DEF_  "GenSigSendType" "cyclicX";
BA_DEF_DEF_  "GenMsgNrOfRepetitions" 0;
BA_DEF_DEF_  "GenMsgDelayTime" 0;
BA_DEF_DEF_  "GenMsgStartDelayTime" 0;
BA_DEF_DEF_  "GenMsgCycleTimeActive" 0;
BA_DEF_DEF_  "GenMsgCycleTime" 0;
BA_DEF_DEF_  "GenMsgSendType" "cyclicX";
BA_DEF_DEF_  "DiagResponse" "nein";
BA_DEF_DEF_  "DiagRequest" "nein";
BA_DEF_DEF_  "DiagState" "nein";
BA_DEF_DEF_  "App-Botschaft" "nein";
BA_DEF_DEF_  "NWM-Botschaft" "nein";
BA_ "GenMsgSendType" BO_ 999 1;
BA_ "GenMsgDelayTime" BO_ 999 20;
BA_ "GenMsgNrOfRepetitions" BO_ 999 2;
BA_ "GenMsgStartValue" BO_ 999 "0300000000000000h";
BA_ "GenMsgSendType" BO_ 1000 5;
BA_ "GenMsgCycleTime" BO_ 1000 500;
BA_ "GenMsgDelayTime" BO_ 1000 20;
BA_ "GenMsgNrOfRepetitions" BO_ 1000 2;
BA_ "GenMsgStartValue" BO_ 1000 "FFFF7FF0FF0FFF00h";
BA_ "GenMsgStartDelayTime" BO_ 1000 50;
BA_ "GenMsgSendType" BO_ 1001 5;
BA_ "GenMsgCycleTime" BO_ 1001 2000;
BA_ "GenMsgDelayTime" BO_ 1001 20;
BA_ "GenMsgNrOfRepetitions" BO_ 1001 2;
BA_ "GenMsgStartValue" BO_ 1001 "0300FF00FFFFFFFFh";
BA_ "GenMsgStartDelayTime" BO_ 1001 40;
BA_ "GenMsgSendType" BO_ 1002 5;
BA_ "GenMsgCycleTime" BO_ 1002 2000;
BA_ "GenMsgDelayTime" BO_ 1002 20;
BA_ "GenMsgNrOfRepetitions" BO_ 1002 2;
BA_ "GenMsgStartValue" BO_ 1002 "0370FF037FFF0000h";
BA_ "GenMsgStartDelayTime" BO_ 1002 50;
BA_ "GenMsgSendType" BO_ 1003 5;
BA_ "GenMsgCycleTime" BO_ 1003 1000;
BA_ "GenMsgDelayTime" BO_ 1003 20;
BA_ "GenMsgNrOfRepetitions" BO_ 1003 2;
BA_ "GenMsgStartValue" BO_ 1003 "FFFFFFFFFFFFFFFFh";
BA_ "GenMsgStartDelayTime" BO_ 1003 120;
BA_ "GenMsgSendType" BO_ 1004 1;
BA_ "GenMsgDelayTime" BO_ 1004 20;
BA_ "GenMsgNrOfRepetitions" BO_ 1004 2;
BA_ "GenMsgStartValue" BO_ 1004 "FFFF7FF0FF0FFF00h";
BA_ "GenMsgSendType" BO_ 1005 1;
BA_ "GenMsgDelayTime" BO_ 1005 20;
BA_ "GenMsgNrOfRepetitions" BO_ 1005 2;
BA_ "GenMsgStartValue" BO_ 1005 "0300FF00FFFFFFFFh";
BA_ "GenMsgSendType" BO_ 1006 1;
BA_ "GenMsgDelayTime" BO_ 1006 20;
BA_ "GenMsgNrOfRepetitions" BO_ 1006 2;
BA_ "GenMsgStartValue" BO_ 1006 "0370FF037FFF0000h";
BA_ "GenMsgSendType" BO_ 1007 1;
BA_ "GenMsgDelayTime" BO_ 1007 20;
BA_ "GenMsgNrOfRepetitions" BO_ 1007 2;
BA_ "GenMsgStartValue" BO_ 1007 "FFFFFFFFFFFFFFFFh";
BA_ "GenMsgCycleTime" BO_ 1008 2000;
BA_ "GenMsgDelayTime" BO_ 1008 20;
BA_ "GenMsgNrOfRepetitions" BO_ 1008 2;
BA_ "GenMsgStartValue" BO_ 1008 "0300000000000000h";
BA_ "GenMsgStartDelayTime" BO_ 1008 140;
BA_ "GenMsgCycleTime" BO_ 1009 2000;
BA_ "GenMsgDelayTime" BO_ 1009 20;
BA_ "GenMsgNrOfRepetitions" BO_ 1009 2;
BA_ "GenMsgStartValue" BO_ 1009 "0300000000000000h";
BA_ "GenMsgStartDelayTime" BO_ 1009 150;
BA_ "GenMsgSendType" BO_ 1010 5;
BA_ "GenMsgCycleTime" BO_ 1010 2000;
BA_ "GenMsgDelayTime" BO_ 1010 20;
BA_ "GenMsgNrOfRepetitions" BO_ 1010 2;
BA_ "GenMsgStartValue" BO_ 1010 "0300000000000000h";
BA_ "GenMsgStartDelayTime" BO_ 1010 30;
BA_ "GenMsgSendType" BO_ 1011 5;
BA_ "GenMsgCycleTime" BO_ 1011 2000;
BA_ "GenMsgDelayTime" BO_ 1011 20;
BA_ "GenMsgNrOfRepetitions" BO_ 1011 2;
BA_ "GenMsgStartValue" BO_ 1011 "0300000000000000h";
BA_ "GenMsgStartDelayTime" BO_ 1011 40;
BA_ "GenMsgSendType" BO_ 1012 5;
BA_ "GenMsgCycleTime" BO_ 1012 2000;
BA_ "GenMsgDelayTime" BO_ 1012 20;
BA_ "GenMsgNrOfRepetitions" BO_ 1012 2;
BA_ "GenMsgStartValue" BO_ 1012 "0300000000000000h";
BA_ "GenMsgStartDelayTime" BO_ 1012 50;
BA_ "GenSigSendType" SG_ 999 BU_NET_CFG_STAT_PT 1;
BA_ "FlexKomSigStartValue" SG_ 999 BU_NET_CFG_STAT_PT "0300000000000000h";
BA_ "GenSigStartValue" SG_ 999 BU_NET_CFG_STAT_PT 3;
BA_ "FlexKomSID" SG_ 999 BU_NET_CFG_STAT_PT 872;
BA_ "FlexKomSigStartPos" SG_ 999 BU_NET_CFG_STAT_PT 7;
BA_ "FlexKomSigLaenge" SG_ 999 BU_NET_CFG_STAT_PT 64;
BA_ "FlexKomSigName" SG_ 999 BU_NET_CFG_STAT_PT "BU_NET_CFG_DATA_PT";
BA_ "FlexKomComment" SG_ 999 BU_NET_CFG_STAT_PT "Backup for network ECU config data for Powertrain";
BA_ "FlexKomIsMotorola" SG_ 999 BU_NET_CFG_STAT_PT 1;
BA_ "GenSigSNA" SG_ 999 BU_NET_CFG_STAT_PT "3h";
BA_ "GenSigSendType" SG_ 999 BU_NetCfg_ACC 1;
BA_ "FlexKomSigStartValue" SG_ 999 BU_NetCfg_ACC "0300000000000000h";
BA_ "FlexKomSID" SG_ 999 BU_NetCfg_ACC 872;
BA_ "FlexKomSigStartPos" SG_ 999 BU_NetCfg_ACC 7;
BA_ "FlexKomSigLaenge" SG_ 999 BU_NetCfg_ACC 64;
BA_ "FlexKomSigName" SG_ 999 BU_NetCfg_ACC "BU_NET_CFG_DATA_PT";
BA_ "FlexKomComment" SG_ 999 BU_NetCfg_ACC "Backup for network ECU config data for Powertrain";
BA_ "FlexKomIsMotorola" SG_ 999 BU_NetCfg_ACC 1;
BA_ "GenSigSNA" SG_ 999 BU_NetCfg_ACC "0h";
BA_ "GenSigSendType" SG_ 999 BU_NetCfg_ADCM 1;
BA_ "FlexKomSigStartValue" SG_ 999 BU_NetCfg_ADCM "0300000000000000h";
BA_ "FlexKomSID" SG_ 999 BU_NetCfg_ADCM 872;
BA_ "FlexKomSigStartPos" SG_ 999 BU_NetCfg_ADCM 7;
BA_ "FlexKomSigLaenge" SG_ 999 BU_NetCfg_ADCM 64;
BA_ "FlexKomSigName" SG_ 999 BU_NetCfg_ADCM "BU_NET_CFG_DATA_PT";
BA_ "FlexKomComment" SG_ 999 BU_NetCfg_ADCM "Backup for network ECU config data for Powertrain";
BA_ "FlexKomIsMotorola" SG_ 999 BU_NetCfg_ADCM 1;
BA_ "GenSigSNA" SG_ 999 BU_NetCfg_ADCM "0h";
BA_ "GenSigSendType" SG_ 999 BU_NetCfg_AHLM 1;
BA_ "FlexKomSigStartValue" SG_ 999 BU_NetCfg_AHLM "0300000000000000h";
BA_ "FlexKomSID" SG_ 999 BU_NetCfg_AHLM 872;
BA_ "FlexKomSigStartPos" SG_ 999 BU_NetCfg_AHLM 7;
BA_ "FlexKomSigLaenge" SG_ 999 BU_NetCfg_AHLM 64;
BA_ "FlexKomSigName" SG_ 999 BU_NetCfg_AHLM "BU_NET_CFG_DATA_PT";
BA_ "FlexKomComment" SG_ 999 BU_NetCfg_AHLM "Backup for network ECU config data for Powertrain";
BA_ "FlexKomIsMotorola" SG_ 999 BU_NetCfg_AHLM 1;
BA_ "GenSigSNA" SG_ 999 BU_NetCfg_AHLM "0h";
BA_ "GenSigSendType" SG_ 999 BU_NetCfg_VSIM_C 1;
BA_ "FlexKomSigStartValue" SG_ 999 BU_NetCfg_VSIM_C "0300000000000000h";
BA_ "FlexKomSID" SG_ 999 BU_NetCfg_VSIM_C 872;
BA_ "FlexKomSigStartPos" SG_ 999 BU_NetCfg_VSIM_C 7;
BA_ "FlexKomSigLaenge" SG_ 999 BU_NetCfg_VSIM_C 64;
BA_ "FlexKomSigName" SG_ 999 BU_NetCfg_VSIM_C "BU_NET_CFG_DATA_PT";
BA_ "FlexKomComment" SG_ 999 BU_NetCfg_VSIM_C "Backup for network ECU config data for Powertrain";
BA_ "FlexKomIsMotorola" SG_ 999 BU_NetCfg_VSIM_C 1;
BA_ "GenSigSNA" SG_ 999 BU_NetCfg_VSIM_C "0h";
BA_ "GenSigSendType" SG_ 999 BU_NetCfg_ASCM 1;
BA_ "FlexKomSigStartValue" SG_ 999 BU_NetCfg_ASCM "0300000000000000h";
BA_ "FlexKomSID" SG_ 999 BU_NetCfg_ASCM 872;
BA_ "FlexKomSigStartPos" SG_ 999 BU_NetCfg_ASCM 7;
BA_ "FlexKomSigLaenge" SG_ 999 BU_NetCfg_ASCM 64;
BA_ "FlexKomSigName" SG_ 999 BU_NetCfg_ASCM "BU_NET_CFG_DATA_PT";
BA_ "FlexKomComment" SG_ 999 BU_NetCfg_ASCM "Backup for network ECU config data for Powertrain";
BA_ "FlexKomIsMotorola" SG_ 999 BU_NetCfg_ASCM 1;
BA_ "GenSigSNA" SG_ 999 BU_NetCfg_ASCM "0h";
BA_ "GenSigSendType" SG_ 999 BU_NetCfg_CBC_PT 1;
BA_ "FlexKomSigStartValue" SG_ 999 BU_NetCfg_CBC_PT "0300000000000000h";
BA_ "FlexKomSID" SG_ 999 BU_NetCfg_CBC_PT 872;
BA_ "FlexKomSigStartPos" SG_ 999 BU_NetCfg_CBC_PT 7;
BA_ "FlexKomSigLaenge" SG_ 999 BU_NetCfg_CBC_PT 64;
BA_ "FlexKomSigName" SG_ 999 BU_NetCfg_CBC_PT "BU_NET_CFG_DATA_PT";
BA_ "FlexKomComment" SG_ 999 BU_NetCfg_CBC_PT "Backup for network ECU config data for Powertrain";
BA_ "FlexKomIsMotorola" SG_ 999 BU_NetCfg_CBC_PT 1;
BA_ "GenSigSNA" SG_ 999 BU_NetCfg_CBC_PT "0h";
BA_ "GenSigSendType" SG_ 999 BU_NetCfg_DTCM 1;
BA_ "FlexKomSigStartValue" SG_ 999 BU_NetCfg_DTCM "0300000000000000h";
BA_ "FlexKomSID" SG_ 999 BU_NetCfg_DTCM 872;
BA_ "FlexKomSigStartPos" SG_ 999 BU_NetCfg_DTCM 7;
BA_ "FlexKomSigLaenge" SG_ 999 BU_NetCfg_DTCM 64;
BA_ "FlexKomSigName" SG_ 999 BU_NetCfg_DTCM "BU_NET_CFG_DATA_PT";
BA_ "FlexKomComment" SG_ 999 BU_NetCfg_DTCM "Backup for network ECU config data for Powertrain";
BA_ "FlexKomIsMotorola" SG_ 999 BU_NetCfg_DTCM 1;
BA_ "GenSigSNA" SG_ 999 BU_NetCfg_DTCM "0h";
BA_ "GenSigSendType" SG_ 999 BU_NetCfg_ECM 1;
BA_ "FlexKomSigStartValue" SG_ 999 BU_NetCfg_ECM "0300000000000000h";
BA_ "FlexKomSID" SG_ 999 BU_NetCfg_ECM 872;
BA_ "FlexKomSigStartPos" SG_ 999 BU_NetCfg_ECM 7;
BA_ "FlexKomSigLaenge" SG_ 999 BU_NetCfg_ECM 64;
BA_ "FlexKomSigName" SG_ 999 BU_NetCfg_ECM "BU_NET_CFG_DATA_PT";
BA_ "FlexKomComment" SG_ 999 BU_NetCfg_ECM "Backup for network ECU config data for Powertrain";
BA_ "FlexKomIsMotorola" SG_ 999 BU_NetCfg_ECM 1;
BA_ "GenSigSNA" SG_ 999 BU_NetCfg_ECM "0h";
BA_ "GenSigSendType" SG_ 999 BU_NetCfg_EPS 1;
BA_ "FlexKomSigStartValue" SG_ 999 BU_NetCfg_EPS "0300000000000000h";
BA_ "FlexKomSID" SG_ 999 BU_NetCfg_EPS 872;
BA_ "FlexKomSigStartPos" SG_ 999 BU_NetCfg_EPS 7;
BA_ "FlexKomSigLaenge" SG_ 999 BU_NetCfg_EPS 64;
BA_ "FlexKomSigName" SG_ 999 BU_NetCfg_EPS "BU_NET_CFG_DATA_PT";
BA_ "FlexKomComment" SG_ 999 BU_NetCfg_EPS "Backup for network ECU config data for Powertrain";
BA_ "FlexKomIsMotorola" SG_ 999 BU_NetCfg_EPS 1;
BA_ "GenSigSNA" SG_ 999 BU_NetCfg_EPS "0h";
BA_ "GenSigSendType" SG_ 999 BU_NetCfg_ESM 1;
BA_ "FlexKomSigStartValue" SG_ 999 BU_NetCfg_ESM "0300000000000000h";
BA_ "FlexKomSID" SG_ 999 BU_NetCfg_ESM 872;
BA_ "FlexKomSigStartPos" SG_ 999 BU_NetCfg_ESM 7;
BA_ "FlexKomSigLaenge" SG_ 999 BU_NetCfg_ESM 64;
BA_ "FlexKomSigName" SG_ 999 BU_NetCfg_ESM "BU_NET_CFG_DATA_PT";
BA_ "FlexKomComment" SG_ 999 BU_NetCfg_ESM "Backup for network ECU config data for Powertrain";
BA_ "FlexKomIsMotorola" SG_ 999 BU_NetCfg_ESM 1;
BA_ "GenSigSNA" SG_ 999 BU_NetCfg_ESM "0h";
BA_ "GenSigSendType" SG_ 999 BU_NetCfg_ESC 1;
BA_ "FlexKomSigStartValue" SG_ 999 BU_NetCfg_ESC "0300000000000000h";
BA_ "FlexKomSID" SG_ 999 BU_NetCfg_ESC 872;
BA_ "FlexKomSigStartPos" SG_ 999 BU_NetCfg_ESC 7;
BA_ "FlexKomSigLaenge" SG_ 999 BU_NetCfg_ESC 64;
BA_ "FlexKomSigName" SG_ 999 BU_NetCfg_ESC "BU_NET_CFG_DATA_PT";
BA_ "FlexKomComment" SG_ 999 BU_NetCfg_ESC "Backup for network ECU config data for Powertrain";
BA_ "FlexKomIsMotorola" SG_ 999 BU_NetCfg_ESC 1;
BA_ "GenSigSNA" SG_ 999 BU_NetCfg_ESC "0h";
BA_ "GenSigSendType" SG_ 999 BU_NetCfg_EPB 1;
BA_ "FlexKomSigStartValue" SG_ 999 BU_NetCfg_EPB "0300000000000000h";
BA_ "FlexKomSID" SG_ 999 BU_NetCfg_EPB 872;
BA_ "FlexKomSigStartPos" SG_ 999 BU_NetCfg_EPB 7;
BA_ "FlexKomSigLaenge" SG_ 999 BU_NetCfg_EPB 64;
BA_ "FlexKomSigName" SG_ 999 BU_NetCfg_EPB "BU_NET_CFG_DATA_PT";
BA_ "FlexKomComment" SG_ 999 BU_NetCfg_EPB "Backup for network ECU config data for Powertrain";
BA_ "FlexKomIsMotorola" SG_ 999 BU_NetCfg_EPB 1;
BA_ "GenSigSNA" SG_ 999 BU_NetCfg_EPB "0h";
BA_ "GenSigSendType" SG_ 999 BU_NetCfg_RF_HUB 1;
BA_ "FlexKomSigStartValue" SG_ 999 BU_NetCfg_RF_HUB "0300000000000000h";
BA_ "FlexKomSID" SG_ 999 BU_NetCfg_RF_HUB 872;
BA_ "FlexKomSigStartPos" SG_ 999 BU_NetCfg_RF_HUB 7;
BA_ "FlexKomSigLaenge" SG_ 999 BU_NetCfg_RF_HUB 64;
BA_ "FlexKomSigName" SG_ 999 BU_NetCfg_RF_HUB "BU_NET_CFG_DATA_PT";
BA_ "FlexKomComment" SG_ 999 BU_NetCfg_RF_HUB "Backup for network ECU config data for Powertrain";
BA_ "FlexKomIsMotorola" SG_ 999 BU_NetCfg_RF_HUB 1;
BA_ "GenSigSNA" SG_ 999 BU_NetCfg_RF_HUB "0h";
BA_ "GenSigSendType" SG_ 999 BU_NetCfg_IC 1;
BA_ "FlexKomSigStartValue" SG_ 999 BU_NetCfg_IC "0300000000000000h";
BA_ "FlexKomSID" SG_ 999 BU_NetCfg_IC 872;
BA_ "FlexKomSigStartPos" SG_ 999 BU_NetCfg_IC 7;
BA_ "FlexKomSigLaenge" SG_ 999 BU_NetCfg_IC 64;
BA_ "FlexKomSigName" SG_ 999 BU_NetCfg_IC "BU_NET_CFG_DATA_PT";
BA_ "FlexKomComment" SG_ 999 BU_NetCfg_IC "Backup for network ECU config data for Powertrain";
BA_ "FlexKomIsMotorola" SG_ 999 BU_NetCfg_IC 1;
BA_ "GenSigSNA" SG_ 999 BU_NetCfg_IC "0h";
BA_ "GenSigSendType" SG_ 999 BU_NetCfg_DASM 1;
BA_ "FlexKomSigStartValue" SG_ 999 BU_NetCfg_DASM "0300000000000000h";
BA_ "FlexKomSID" SG_ 999 BU_NetCfg_DASM 872;
BA_ "FlexKomSigStartPos" SG_ 999 BU_NetCfg_DASM 7;
BA_ "FlexKomSigLaenge" SG_ 999 BU_NetCfg_DASM 64;
BA_ "FlexKomSigName" SG_ 999 BU_NetCfg_DASM "BU_NET_CFG_DATA_PT";
BA_ "FlexKomComment" SG_ 999 BU_NetCfg_DASM "Backup for network ECU config data for Powertrain";
BA_ "FlexKomIsMotorola" SG_ 999 BU_NetCfg_DASM 1;
BA_ "GenSigSNA" SG_ 999 BU_NetCfg_DASM "0h";
BA_ "GenSigSendType" SG_ 999 BU_NetCfg_FDCM 1;
BA_ "FlexKomSigStartValue" SG_ 999 BU_NetCfg_FDCM "0300000000000000h";
BA_ "FlexKomSID" SG_ 999 BU_NetCfg_FDCM 872;
BA_ "FlexKomSigStartPos" SG_ 999 BU_NetCfg_FDCM 7;
BA_ "FlexKomSigLaenge" SG_ 999 BU_NetCfg_FDCM 64;
BA_ "FlexKomSigName" SG_ 999 BU_NetCfg_FDCM "BU_NET_CFG_DATA_PT";
BA_ "FlexKomComment" SG_ 999 BU_NetCfg_FDCM "Backup for network ECU config data for Powertrain";
BA_ "FlexKomIsMotorola" SG_ 999 BU_NetCfg_FDCM 1;
BA_ "GenSigSNA" SG_ 999 BU_NetCfg_FDCM "0h";
BA_ "GenSigSendType" SG_ 999 BU_NetCfg_EPPM 1;
BA_ "FlexKomSigStartValue" SG_ 999 BU_NetCfg_EPPM "0300000000000000h";
BA_ "FlexKomSID" SG_ 999 BU_NetCfg_EPPM 872;
BA_ "FlexKomSigStartPos" SG_ 999 BU_NetCfg_EPPM 7;
BA_ "FlexKomSigLaenge" SG_ 999 BU_NetCfg_EPPM 64;
BA_ "FlexKomSigName" SG_ 999 BU_NetCfg_EPPM "BU_NET_CFG_DATA_PT";
BA_ "FlexKomComment" SG_ 999 BU_NetCfg_EPPM "Backup for network ECU config data for Powertrain";
BA_ "FlexKomIsMotorola" SG_ 999 BU_NetCfg_EPPM 1;
BA_ "GenSigSNA" SG_ 999 BU_NetCfg_EPPM "0h";
BA_ "GenSigSendType" SG_ 999 BU_NetCfg_ORC 1;
BA_ "FlexKomSigStartValue" SG_ 999 BU_NetCfg_ORC "0300000000000000h";
BA_ "FlexKomSID" SG_ 999 BU_NetCfg_ORC 872;
BA_ "FlexKomSigStartPos" SG_ 999 BU_NetCfg_ORC 7;
BA_ "FlexKomSigLaenge" SG_ 999 BU_NetCfg_ORC 64;
BA_ "FlexKomSigName" SG_ 999 BU_NetCfg_ORC "BU_NET_CFG_DATA_PT";
BA_ "FlexKomComment" SG_ 999 BU_NetCfg_ORC "Backup for network ECU config data for Powertrain";
BA_ "FlexKomIsMotorola" SG_ 999 BU_NetCfg_ORC 1;
BA_ "GenSigSNA" SG_ 999 BU_NetCfg_ORC "0h";
BA_ "GenSigSendType" SG_ 999 BU_NetCfg_PTS 1;
BA_ "FlexKomSigStartValue" SG_ 999 BU_NetCfg_PTS "0300000000000000h";
BA_ "FlexKomSID" SG_ 999 BU_NetCfg_PTS 872;
BA_ "FlexKomSigStartPos" SG_ 999 BU_NetCfg_PTS 7;
BA_ "FlexKomSigLaenge" SG_ 999 BU_NetCfg_PTS 64;
BA_ "FlexKomSigName" SG_ 999 BU_NetCfg_PTS "BU_NET_CFG_DATA_PT";
BA_ "FlexKomComment" SG_ 999 BU_NetCfg_PTS "Backup for network ECU config data for Powertrain";
BA_ "FlexKomIsMotorola" SG_ 999 BU_NetCfg_PTS 1;
BA_ "GenSigSNA" SG_ 999 BU_NetCfg_PTS "0h";
BA_ "GenSigSendType" SG_ 999 BU_NetCfg_RBT_DR 1;
BA_ "FlexKomSigStartValue" SG_ 999 BU_NetCfg_RBT_DR "0300000000000000h";
BA_ "FlexKomSID" SG_ 999 BU_NetCfg_RBT_DR 872;
BA_ "FlexKomSigStartPos" SG_ 999 BU_NetCfg_RBT_DR 7;
BA_ "FlexKomSigLaenge" SG_ 999 BU_NetCfg_RBT_DR 64;
BA_ "FlexKomSigName" SG_ 999 BU_NetCfg_RBT_DR "BU_NET_CFG_DATA_PT";
BA_ "FlexKomComment" SG_ 999 BU_NetCfg_RBT_DR "Backup for network ECU config data for Powertrain";
BA_ "FlexKomIsMotorola" SG_ 999 BU_NetCfg_RBT_DR 1;
BA_ "GenSigSNA" SG_ 999 BU_NetCfg_RBT_DR "0h";
BA_ "GenSigSendType" SG_ 999 BU_NetCfg_RBT_PASS 1;
BA_ "FlexKomSigStartValue" SG_ 999 BU_NetCfg_RBT_PASS "0300000000000000h";
BA_ "FlexKomSID" SG_ 999 BU_NetCfg_RBT_PASS 872;
BA_ "FlexKomSigStartPos" SG_ 999 BU_NetCfg_RBT_PASS 7;
BA_ "FlexKomSigLaenge" SG_ 999 BU_NetCfg_RBT_PASS 64;
BA_ "FlexKomSigName" SG_ 999 BU_NetCfg_RBT_PASS "BU_NET_CFG_DATA_PT";
BA_ "FlexKomComment" SG_ 999 BU_NetCfg_RBT_PASS "Backup for network ECU config data for Powertrain";
BA_ "FlexKomIsMotorola" SG_ 999 BU_NetCfg_RBT_PASS 1;
BA_ "GenSigSNA" SG_ 999 BU_NetCfg_RBT_PASS "0h";
BA_ "GenSigSendType" SG_ 999 BU_NetCfg_SCCM 1;
BA_ "FlexKomSigStartValue" SG_ 999 BU_NetCfg_SCCM "0300000000000000h";
BA_ "FlexKomSID" SG_ 999 BU_NetCfg_SCCM 872;
BA_ "FlexKomSigStartPos" SG_ 999 BU_NetCfg_SCCM 7;
BA_ "FlexKomSigLaenge" SG_ 999 BU_NetCfg_SCCM 64;
BA_ "FlexKomSigName" SG_ 999 BU_NetCfg_SCCM "BU_NET_CFG_DATA_PT";
BA_ "FlexKomComment" SG_ 999 BU_NetCfg_SCCM "Backup for network ECU config data for Powertrain";
BA_ "FlexKomIsMotorola" SG_ 999 BU_NetCfg_SCCM 1;
BA_ "GenSigSNA" SG_ 999 BU_NetCfg_SCCM "0h";
BA_ "GenSigSendType" SG_ 999 BU_NetCfg_ELSD 1;
BA_ "FlexKomSigStartValue" SG_ 999 BU_NetCfg_ELSD "0300000000000000h";
BA_ "FlexKomSID" SG_ 999 BU_NetCfg_ELSD 872;
BA_ "FlexKomSigStartPos" SG_ 999 BU_NetCfg_ELSD 7;
BA_ "FlexKomSigLaenge" SG_ 999 BU_NetCfg_ELSD 64;
BA_ "FlexKomSigName" SG_ 999 BU_NetCfg_ELSD "BU_NET_CFG_DATA_PT";
BA_ "FlexKomComment" SG_ 999 BU_NetCfg_ELSD "Backup for network ECU config data for Powertrain";
BA_ "FlexKomIsMotorola" SG_ 999 BU_NetCfg_ELSD 1;
BA_ "GenSigSNA" SG_ 999 BU_NetCfg_ELSD "0h";
BA_ "GenSigSendType" SG_ 999 BU_NetCfg_TCM 1;
BA_ "FlexKomSigStartValue" SG_ 999 BU_NetCfg_TCM "0300000000000000h";
BA_ "FlexKomSID" SG_ 999 BU_NetCfg_TCM 872;
BA_ "FlexKomSigStartPos" SG_ 999 BU_NetCfg_TCM 7;
BA_ "FlexKomSigLaenge" SG_ 999 BU_NetCfg_TCM 64;
BA_ "FlexKomSigName" SG_ 999 BU_NetCfg_TCM "BU_NET_CFG_DATA_PT";
BA_ "FlexKomComment" SG_ 999 BU_NetCfg_TCM "Backup for network ECU config data for Powertrain";
BA_ "FlexKomIsMotorola" SG_ 999 BU_NetCfg_TCM 1;
BA_ "GenSigSNA" SG_ 999 BU_NetCfg_TCM "0h";
BA_ "GenSigSendType" SG_ 999 BU_NetCfg_TPM 1;
BA_ "FlexKomSigStartValue" SG_ 999 BU_NetCfg_TPM "0300000000000000h";
BA_ "FlexKomSID" SG_ 999 BU_NetCfg_TPM 872;
BA_ "FlexKomSigStartPos" SG_ 999 BU_NetCfg_TPM 7;
BA_ "FlexKomSigLaenge" SG_ 999 BU_NetCfg_TPM 64;
BA_ "FlexKomSigName" SG_ 999 BU_NetCfg_TPM "BU_NET_CFG_DATA_PT";
BA_ "FlexKomComment" SG_ 999 BU_NetCfg_TPM "Backup for network ECU config data for Powertrain";
BA_ "FlexKomIsMotorola" SG_ 999 BU_NetCfg_TPM 1;
BA_ "GenSigSNA" SG_ 999 BU_NetCfg_TPM "0h";
BA_ "GenSigSendType" SG_ 999 BU_NetCfg_PASS_PT 1;
BA_ "FlexKomSigStartValue" SG_ 999 BU_NetCfg_PASS_PT "0300000000000000h";
BA_ "FlexKomSID" SG_ 999 BU_NetCfg_PASS_PT 872;
BA_ "FlexKomSigStartPos" SG_ 999 BU_NetCfg_PASS_PT 7;
BA_ "FlexKomSigLaenge" SG_ 999 BU_NetCfg_PASS_PT 64;
BA_ "FlexKomSigName" SG_ 999 BU_NetCfg_PASS_PT "BU_NET_CFG_DATA_PT";
BA_ "FlexKomComment" SG_ 999 BU_NetCfg_PASS_PT "Backup for network ECU config data for Powertrain";
BA_ "FlexKomIsMotorola" SG_ 999 BU_NetCfg_PASS_PT 1;
BA_ "GenSigSNA" SG_ 999 BU_NetCfg_PASS_PT "0h";
BA_ "GenSigSendType" SG_ 999 BU_NetCfg_AFLS 1;
BA_ "FlexKomSigStartValue" SG_ 999 BU_NetCfg_AFLS "0300000000000000h";
BA_ "FlexKomSID" SG_ 999 BU_NetCfg_AFLS 872;
BA_ "FlexKomSigStartPos" SG_ 999 BU_NetCfg_AFLS 7;
BA_ "FlexKomSigLaenge" SG_ 999 BU_NetCfg_AFLS 64;
BA_ "FlexKomSigName" SG_ 999 BU_NetCfg_AFLS "BU_NET_CFG_DATA_PT";
BA_ "FlexKomComment" SG_ 999 BU_NetCfg_AFLS "Backup for network ECU config data for Powertrain";
BA_ "FlexKomIsMotorola" SG_ 999 BU_NetCfg_AFLS 1;
BA_ "GenSigSNA" SG_ 999 BU_NetCfg_AFLS "0h";
BA_ "GenSigSendType" SG_ 999 BU_NetCfg_ITBM 1;
BA_ "FlexKomSigStartValue" SG_ 999 BU_NetCfg_ITBM "0300000000000000h";
BA_ "FlexKomSID" SG_ 999 BU_NetCfg_ITBM 872;
BA_ "FlexKomSigStartPos" SG_ 999 BU_NetCfg_ITBM 7;
BA_ "FlexKomSigLaenge" SG_ 999 BU_NetCfg_ITBM 64;
BA_ "FlexKomSigName" SG_ 999 BU_NetCfg_ITBM "BU_NET_CFG_DATA_PT";
BA_ "FlexKomComment" SG_ 999 BU_NetCfg_ITBM "Backup for network ECU config data for Powertrain";
BA_ "FlexKomIsMotorola" SG_ 999 BU_NetCfg_ITBM 1;
BA_ "GenSigSNA" SG_ 999 BU_NetCfg_ITBM "0h";
BA_ "GenSigSendType" SG_ 999 BU_NetCfg_OCM 1;
BA_ "FlexKomSigStartValue" SG_ 999 BU_NetCfg_OCM "0300000000000000h";
BA_ "FlexKomSID" SG_ 999 BU_NetCfg_OCM 872;
BA_ "FlexKomSigStartPos" SG_ 999 BU_NetCfg_OCM 7;
BA_ "FlexKomSigLaenge" SG_ 999 BU_NetCfg_OCM 64;
BA_ "FlexKomSigName" SG_ 999 BU_NetCfg_OCM "BU_NET_CFG_DATA_PT";
BA_ "FlexKomComment" SG_ 999 BU_NetCfg_OCM "Backup for network ECU config data for Powertrain";
BA_ "FlexKomIsMotorola" SG_ 999 BU_NetCfg_OCM 1;
BA_ "GenSigSNA" SG_ 999 BU_NetCfg_OCM "0h";
BA_ "GenSigSendType" SG_ 999 BU_NetCfg_HaLF 1;
BA_ "FlexKomSigStartValue" SG_ 999 BU_NetCfg_HaLF "0300000000000000h";
BA_ "FlexKomSID" SG_ 999 BU_NetCfg_HaLF 872;
BA_ "FlexKomSigStartPos" SG_ 999 BU_NetCfg_HaLF 7;
BA_ "FlexKomSigLaenge" SG_ 999 BU_NetCfg_HaLF 64;
BA_ "FlexKomSigName" SG_ 999 BU_NetCfg_HaLF "BU_NET_CFG_DATA_PT";
BA_ "FlexKomComment" SG_ 999 BU_NetCfg_HaLF "Backup for network ECU config data for Powertrain";
BA_ "FlexKomIsMotorola" SG_ 999 BU_NetCfg_HaLF 1;
BA_ "GenSigSNA" SG_ 999 BU_NetCfg_HaLF "0h";
BA_ "GenSigSendType" SG_ 999 BU_NetCfg_ANC 1;
BA_ "FlexKomSigStartValue" SG_ 999 BU_NetCfg_ANC "0300000000000000h";
BA_ "FlexKomSID" SG_ 999 BU_NetCfg_ANC 872;
BA_ "FlexKomSigStartPos" SG_ 999 BU_NetCfg_ANC 7;
BA_ "FlexKomSigLaenge" SG_ 999 BU_NetCfg_ANC 64;
BA_ "FlexKomSigName" SG_ 999 BU_NetCfg_ANC "BU_NET_CFG_DATA_PT";
BA_ "FlexKomComment" SG_ 999 BU_NetCfg_ANC "Backup for network ECU config data for Powertrain";
BA_ "FlexKomIsMotorola" SG_ 999 BU_NetCfg_ANC 1;
BA_ "GenSigSNA" SG_ 999 BU_NetCfg_ANC "0h";
BA_ "GenSigSendType" SG_ 1000 VC_VehCfg1_Stat 5;
BA_ "GenSigCycleTime" SG_ 1000 VC_VehCfg1_Stat 500;
BA_ "FlexKomSigStartValue" SG_ 1000 VC_VehCfg1_Stat "FFFF7FF0FF0FFF00h";
BA_ "GenSigStartValue" SG_ 1000 VC_VehCfg1_Stat 3;
BA_ "GenSigTimeout_IC" SG_ 1000 VC_VehCfg1_Stat 5250;
BA_ "GenSigTimeout_TPM" SG_ 1000 VC_VehCfg1_Stat 5250;
BA_ "GenSigTimeout_EPS" SG_ 1000 VC_VehCfg1_Stat 5250;
BA_ "GenSigTimeout_SCCM" SG_ 1000 VC_VehCfg1_Stat 5250;
BA_ "GenSigTimeout_ESM" SG_ 1000 VC_VehCfg1_Stat 5250;
BA_ "GenSigTimeout_ADCM" SG_ 1000 VC_VehCfg1_Stat 5250;
BA_ "GenSigTimeout_ORC" SG_ 1000 VC_VehCfg1_Stat 1750;
BA_ "FlexKomSID" SG_ 1000 VC_VehCfg1_Stat 886;
BA_ "FlexKomSigStartPos" SG_ 1000 VC_VehCfg1_Stat 7;
BA_ "FlexKomSigLaenge" SG_ 1000 VC_VehCfg1_Stat 64;
BA_ "FlexKomSigName" SG_ 1000 VC_VehCfg1_Stat "VehCfg1_Pkt";
BA_ "FlexKomComment" SG_ 1000 VC_VehCfg1_Stat "Vehicle Configuration 1 Packet";
BA_ "FlexKomIsMotorola" SG_ 1000 VC_VehCfg1_Stat 1;
BA_ "GenSigSNA" SG_ 1000 VC_VehCfg1_Stat "3h";
BA_ "GenSigSendType" SG_ 1000 VC_MODEL_YEAR 5;
BA_ "GenSigCycleTime" SG_ 1000 VC_MODEL_YEAR 500;
BA_ "FlexKomSigStartValue" SG_ 1000 VC_MODEL_YEAR "FFFF7FF0FF0FFF00h";
BA_ "GenSigStartValue" SG_ 1000 VC_MODEL_YEAR 63;
BA_ "GenSigTimeout_IC" SG_ 1000 VC_MODEL_YEAR 5250;
BA_ "GenSigTimeout_TPM" SG_ 1000 VC_MODEL_YEAR 5250;
BA_ "GenSigTimeout_EPS" SG_ 1000 VC_MODEL_YEAR 5250;
BA_ "GenSigTimeout_SCCM" SG_ 1000 VC_MODEL_YEAR 5250;
BA_ "GenSigTimeout_ESM" SG_ 1000 VC_MODEL_YEAR 5250;
BA_ "GenSigTimeout_ORC" SG_ 1000 VC_MODEL_YEAR 1750;
BA_ "FlexKomSID" SG_ 1000 VC_MODEL_YEAR 886;
BA_ "FlexKomSigStartPos" SG_ 1000 VC_MODEL_YEAR 7;
BA_ "FlexKomSigLaenge" SG_ 1000 VC_MODEL_YEAR 64;
BA_ "FlexKomSigName" SG_ 1000 VC_MODEL_YEAR "VehCfg1_Pkt";
BA_ "FlexKomComment" SG_ 1000 VC_MODEL_YEAR "Vehicle Configuration 1 Packet";
BA_ "FlexKomIsMotorola" SG_ 1000 VC_MODEL_YEAR 1;
BA_ "GenSigSNA" SG_ 1000 VC_MODEL_YEAR "3Fh";
BA_ "GenSigSendType" SG_ 1000 VC_VEH_LINE 5;
BA_ "GenSigCycleTime" SG_ 1000 VC_VEH_LINE 500;
BA_ "FlexKomSigStartValue" SG_ 1000 VC_VEH_LINE "FFFF7FF0FF0FFF00h";
BA_ "GenSigStartValue" SG_ 1000 VC_VEH_LINE 255;
BA_ "GenSigTimeout_IC" SG_ 1000 VC_VEH_LINE 5250;
BA_ "GenSigTimeout_TPM" SG_ 1000 VC_VEH_LINE 5250;
BA_ "GenSigTimeout_EPS" SG_ 1000 VC_VEH_LINE 5250;
BA_ "GenSigTimeout_SCCM" SG_ 1000 VC_VEH_LINE 5250;
BA_ "GenSigTimeout_ESM" SG_ 1000 VC_VEH_LINE 5250;
BA_ "GenSigTimeout_ADCM" SG_ 1000 VC_VEH_LINE 5250;
BA_ "GenSigTimeout_ORC" SG_ 1000 VC_VEH_LINE 1750;
BA_ "FlexKomSID" SG_ 1000 VC_VEH_LINE 886;
BA_ "FlexKomSigStartPos" SG_ 1000 VC_VEH_LINE 7;
BA_ "FlexKomSigLaenge" SG_ 1000 VC_VEH_LINE 64;
BA_ "FlexKomSigName" SG_ 1000 VC_VEH_LINE "VehCfg1_Pkt";
BA_ "FlexKomComment" SG_ 1000 VC_VEH_LINE "Vehicle Configuration 1 Packet";
BA_ "FlexKomIsMotorola" SG_ 1000 VC_VEH_LINE 1;
BA_ "GenSigSNA" SG_ 1000 VC_VEH_LINE "FFh";
BA_ "GenSigSendType" SG_ 1000 VC_COUNTRY 5;
BA_ "GenSigCycleTime" SG_ 1000 VC_COUNTRY 500;
BA_ "FlexKomSigStartValue" SG_ 1000 VC_COUNTRY "FFFF7FF0FF0FFF00h";
BA_ "GenSigStartValue" SG_ 1000 VC_COUNTRY 31;
BA_ "GenSigTimeout_IC" SG_ 1000 VC_COUNTRY 5250;
BA_ "GenSigTimeout_TPM" SG_ 1000 VC_COUNTRY 5250;
BA_ "GenSigTimeout_EPS" SG_ 1000 VC_COUNTRY 5250;
BA_ "GenSigTimeout_SCCM" SG_ 1000 VC_COUNTRY 5250;
BA_ "GenSigTimeout_ESM" SG_ 1000 VC_COUNTRY 5250;
BA_ "GenSigTimeout_ORC" SG_ 1000 VC_COUNTRY 1750;
BA_ "FlexKomSID" SG_ 1000 VC_COUNTRY 886;
BA_ "FlexKomSigStartPos" SG_ 1000 VC_COUNTRY 7;
BA_ "FlexKomSigLaenge" SG_ 1000 VC_COUNTRY 64;
BA_ "FlexKomSigName" SG_ 1000 VC_COUNTRY "VehCfg1_Pkt";
BA_ "FlexKomComment" SG_ 1000 VC_COUNTRY "Vehicle Configuration 1 Packet";
BA_ "FlexKomIsMotorola" SG_ 1000 VC_COUNTRY 1;
BA_ "GenSigSNA" SG_ 1000 VC_COUNTRY "1Fh";
BA_ "GenSigSendType" SG_ 1000 VC_LHD_RHD 5;
BA_ "GenSigCycleTime" SG_ 1000 VC_LHD_RHD 500;
BA_ "FlexKomSigStartValue" SG_ 1000 VC_LHD_RHD "FFFF7FF0FF0FFF00h";
BA_ "GenSigStartValue" SG_ 1000 VC_LHD_RHD 3;
BA_ "GenSigTimeout_IC" SG_ 1000 VC_LHD_RHD 5250;
BA_ "GenSigTimeout_ESM" SG_ 1000 VC_LHD_RHD 5250;
BA_ "GenSigTimeout_ORC" SG_ 1000 VC_LHD_RHD 1750;
BA_ "FlexKomSID" SG_ 1000 VC_LHD_RHD 886;
BA_ "FlexKomSigStartPos" SG_ 1000 VC_LHD_RHD 7;
BA_ "FlexKomSigLaenge" SG_ 1000 VC_LHD_RHD 64;
BA_ "FlexKomSigName" SG_ 1000 VC_LHD_RHD "VehCfg1_Pkt";
BA_ "FlexKomComment" SG_ 1000 VC_LHD_RHD "Vehicle Configuration 1 Packet";
BA_ "FlexKomIsMotorola" SG_ 1000 VC_LHD_RHD 1;
BA_ "GenSigSNA" SG_ 1000 VC_LHD_RHD "3h";
BA_ "GenSigSendType" SG_ 1000 VC_RemStPrsnt 5;
BA_ "GenSigCycleTime" SG_ 1000 VC_RemStPrsnt 500;
BA_ "FlexKomSigStartValue" SG_ 1000 VC_RemStPrsnt "FFFF7FF0FF0FFF00h";
BA_ "GenSigTimeout_IC" SG_ 1000 VC_RemStPrsnt 5250;
BA_ "GenSigTimeout_TPM" SG_ 1000 VC_RemStPrsnt 5250;
BA_ "FlexKomSID" SG_ 1000 VC_RemStPrsnt 886;
BA_ "FlexKomSigStartPos" SG_ 1000 VC_RemStPrsnt 7;
BA_ "FlexKomSigLaenge" SG_ 1000 VC_RemStPrsnt 64;
BA_ "FlexKomSigName" SG_ 1000 VC_RemStPrsnt "VehCfg1_Pkt";
BA_ "FlexKomComment" SG_ 1000 VC_RemStPrsnt "Vehicle Configuration 1 Packet";
BA_ "FlexKomIsMotorola" SG_ 1000 VC_RemStPrsnt 1;
BA_ "GenSigSNA" SG_ 1000 VC_RemStPrsnt "0h";
BA_ "GenSigSendType" SG_ 1000 VC_XWD 5;
BA_ "GenSigCycleTime" SG_ 1000 VC_XWD 500;
BA_ "FlexKomSigStartValue" SG_ 1000 VC_XWD "FFFF7FF0FF0FFF00h";
BA_ "GenSigTimeout_IC" SG_ 1000 VC_XWD 5250;
BA_ "GenSigTimeout_ESM" SG_ 1000 VC_XWD 5250;
BA_ "GenSigTimeout_ORC" SG_ 1000 VC_XWD 1750;
BA_ "FlexKomSID" SG_ 1000 VC_XWD 886;
BA_ "FlexKomSigStartPos" SG_ 1000 VC_XWD 7;
BA_ "FlexKomSigLaenge" SG_ 1000 VC_XWD 64;
BA_ "FlexKomSigName" SG_ 1000 VC_XWD "VehCfg1_Pkt";
BA_ "FlexKomComment" SG_ 1000 VC_XWD "Vehicle Configuration 1 Packet";
BA_ "FlexKomIsMotorola" SG_ 1000 VC_XWD 1;
BA_ "GenSigSNA" SG_ 1000 VC_XWD "0h";
BA_ "GenSigSendType" SG_ 1000 VC_EmodePrsnt 5;
BA_ "GenSigCycleTime" SG_ 1000 VC_EmodePrsnt 500;
BA_ "FlexKomSigStartValue" SG_ 1000 VC_EmodePrsnt "FFFF7FF0FF0FFF00h";
BA_ "FlexKomSID" SG_ 1000 VC_EmodePrsnt 886;
BA_ "FlexKomSigStartPos" SG_ 1000 VC_EmodePrsnt 7;
BA_ "FlexKomSigLaenge" SG_ 1000 VC_EmodePrsnt 64;
BA_ "FlexKomSigName" SG_ 1000 VC_EmodePrsnt "VehCfg1_Pkt";
BA_ "FlexKomComment" SG_ 1000 VC_EmodePrsnt "Vehicle Configuration 1 Packet";
BA_ "FlexKomIsMotorola" SG_ 1000 VC_EmodePrsnt 1;
BA_ "GenSigSNA" SG_ 1000 VC_EmodePrsnt "0h";
BA_ "GenSigSendType" SG_ 1000 VC_AUTO_HB 5;
BA_ "GenSigCycleTime" SG_ 1000 VC_AUTO_HB 500;
BA_ "FlexKomSigStartValue" SG_ 1000 VC_AUTO_HB "FFFF7FF0FF0FFF00h";
BA_ "GenSigTimeout_IC" SG_ 1000 VC_AUTO_HB 5250;
BA_ "FlexKomSID" SG_ 1000 VC_AUTO_HB 886;
BA_ "FlexKomSigStartPos" SG_ 1000 VC_AUTO_HB 7;
BA_ "FlexKomSigLaenge" SG_ 1000 VC_AUTO_HB 64;
BA_ "FlexKomSigName" SG_ 1000 VC_AUTO_HB "VehCfg1_Pkt";
BA_ "FlexKomComment" SG_ 1000 VC_AUTO_HB "Vehicle Configuration 1 Packet";
BA_ "FlexKomIsMotorola" SG_ 1000 VC_AUTO_HB 1;
BA_ "GenSigSNA" SG_ 1000 VC_AUTO_HB "0h";
BA_ "GenSigSendType" SG_ 1000 VC_BODY_STYLE 5;
BA_ "GenSigCycleTime" SG_ 1000 VC_BODY_STYLE 500;
BA_ "FlexKomSigStartValue" SG_ 1000 VC_BODY_STYLE "FFFF7FF0FF0FFF00h";
BA_ "GenSigStartValue" SG_ 1000 VC_BODY_STYLE 15;
BA_ "GenSigTimeout_IC" SG_ 1000 VC_BODY_STYLE 5250;
BA_ "GenSigTimeout_TPM" SG_ 1000 VC_BODY_STYLE 5250;
BA_ "GenSigTimeout_EPS" SG_ 1000 VC_BODY_STYLE 5250;
BA_ "GenSigTimeout_SCCM" SG_ 1000 VC_BODY_STYLE 5250;
BA_ "GenSigTimeout_ESM" SG_ 1000 VC_BODY_STYLE 5250;
BA_ "GenSigTimeout_ORC" SG_ 1000 VC_BODY_STYLE 1750;
BA_ "FlexKomSID" SG_ 1000 VC_BODY_STYLE 886;
BA_ "FlexKomSigStartPos" SG_ 1000 VC_BODY_STYLE 7;
BA_ "FlexKomSigLaenge" SG_ 1000 VC_BODY_STYLE 64;
BA_ "FlexKomSigName" SG_ 1000 VC_BODY_STYLE "VehCfg1_Pkt";
BA_ "FlexKomComment" SG_ 1000 VC_BODY_STYLE "Vehicle Configuration 1 Packet";
BA_ "FlexKomIsMotorola" SG_ 1000 VC_BODY_STYLE 1;
BA_ "GenSigSNA" SG_ 1000 VC_BODY_STYLE "Fh";
BA_ "GenSigSendType" SG_ 1000 VC_MAX_VEH_SPD 5;
BA_ "GenSigCycleTime" SG_ 1000 VC_MAX_VEH_SPD 500;
BA_ "FlexKomSigStartValue" SG_ 1000 VC_MAX_VEH_SPD "FFFF7FF0FF0FFF00h";
BA_ "GenSigStartValue" SG_ 1000 VC_MAX_VEH_SPD 255;
BA_ "FlexKomSID" SG_ 1000 VC_MAX_VEH_SPD 886;
BA_ "FlexKomSigStartPos" SG_ 1000 VC_MAX_VEH_SPD 7;
BA_ "FlexKomSigLaenge" SG_ 1000 VC_MAX_VEH_SPD 64;
BA_ "FlexKomSigName" SG_ 1000 VC_MAX_VEH_SPD "VehCfg1_Pkt";
BA_ "FlexKomComment" SG_ 1000 VC_MAX_VEH_SPD "Vehicle Configuration 1 Packet";
BA_ "FlexKomIsMotorola" SG_ 1000 VC_MAX_VEH_SPD 1;
BA_ "GenSigSNA" SG_ 1000 VC_MAX_VEH_SPD "FFh";
BA_ "GenSigSendType" SG_ 1000 VC_ShftrTyp 5;
BA_ "GenSigCycleTime" SG_ 1000 VC_ShftrTyp 500;
BA_ "FlexKomSigStartValue" SG_ 1000 VC_ShftrTyp "FFFF7FF0FF0FFF00h";
BA_ "GenSigStartValue" SG_ 1000 VC_ShftrTyp 15;
BA_ "GenSigTimeout_IC" SG_ 1000 VC_ShftrTyp 5250;
BA_ "GenSigTimeout_ESM" SG_ 1000 VC_ShftrTyp 5250;
BA_ "FlexKomSID" SG_ 1000 VC_ShftrTyp 886;
BA_ "FlexKomSigStartPos" SG_ 1000 VC_ShftrTyp 7;
BA_ "FlexKomSigLaenge" SG_ 1000 VC_ShftrTyp 64;
BA_ "FlexKomSigName" SG_ 1000 VC_ShftrTyp "VehCfg1_Pkt";
BA_ "FlexKomComment" SG_ 1000 VC_ShftrTyp "Vehicle Configuration 1 Packet";
BA_ "FlexKomIsMotorola" SG_ 1000 VC_ShftrTyp 1;
BA_ "GenSigSNA" SG_ 1000 VC_ShftrTyp "Fh";
BA_ "GenSigSendType" SG_ 1000 VC_PTS_DispTyp 5;
BA_ "GenSigCycleTime" SG_ 1000 VC_PTS_DispTyp 500;
BA_ "FlexKomSigStartValue" SG_ 1000 VC_PTS_DispTyp "FFFF7FF0FF0FFF00h";
BA_ "GenSigTimeout_PTS" SG_ 1000 VC_PTS_DispTyp 2750;
BA_ "FlexKomSID" SG_ 1000 VC_PTS_DispTyp 886;
BA_ "FlexKomSigStartPos" SG_ 1000 VC_PTS_DispTyp 7;
BA_ "FlexKomSigLaenge" SG_ 1000 VC_PTS_DispTyp 64;
BA_ "FlexKomSigName" SG_ 1000 VC_PTS_DispTyp "VehCfg1_Pkt";
BA_ "FlexKomComment" SG_ 1000 VC_PTS_DispTyp "Vehicle Configuration 1 Packet";
BA_ "FlexKomIsMotorola" SG_ 1000 VC_PTS_DispTyp 1;
BA_ "GenSigSNA" SG_ 1000 VC_PTS_DispTyp "7h";
BA_ "GenSigSendType" SG_ 1000 VC_PP_Prsnt 5;
BA_ "GenSigCycleTime" SG_ 1000 VC_PP_Prsnt 500;
BA_ "FlexKomSigStartValue" SG_ 1000 VC_PP_Prsnt "FFFF7FF0FF0FFF00h";
BA_ "GenSigTimeout_IC" SG_ 1000 VC_PP_Prsnt 5250;
BA_ "FlexKomSID" SG_ 1000 VC_PP_Prsnt 886;
BA_ "FlexKomSigStartPos" SG_ 1000 VC_PP_Prsnt 7;
BA_ "FlexKomSigLaenge" SG_ 1000 VC_PP_Prsnt 64;
BA_ "FlexKomSigName" SG_ 1000 VC_PP_Prsnt "VehCfg1_Pkt";
BA_ "FlexKomComment" SG_ 1000 VC_PP_Prsnt "Vehicle Configuration 1 Packet";
BA_ "FlexKomIsMotorola" SG_ 1000 VC_PP_Prsnt 1;
BA_ "GenSigSNA" SG_ 1000 VC_PP_Prsnt "0h";
BA_ "GenSigSendType" SG_ 1000 VC_SpecialPKG 5;
BA_ "GenSigCycleTime" SG_ 1000 VC_SpecialPKG 500;
BA_ "FlexKomSigStartValue" SG_ 1000 VC_SpecialPKG "FFFF7FF0FF0FFF00h";
BA_ "GenSigStartValue" SG_ 1000 VC_SpecialPKG 255;
BA_ "GenSigTimeout_IC" SG_ 1000 VC_SpecialPKG 5250;
BA_ "GenSigTimeout_ORC" SG_ 1000 VC_SpecialPKG 1750;
BA_ "FlexKomSID" SG_ 1000 VC_SpecialPKG 886;
BA_ "FlexKomSigStartPos" SG_ 1000 VC_SpecialPKG 7;
BA_ "FlexKomSigLaenge" SG_ 1000 VC_SpecialPKG 64;
BA_ "FlexKomSigName" SG_ 1000 VC_SpecialPKG "VehCfg1_Pkt";
BA_ "FlexKomComment" SG_ 1000 VC_SpecialPKG "Vehicle Configuration 1 Packet";
BA_ "FlexKomIsMotorola" SG_ 1000 VC_SpecialPKG 1;
BA_ "GenSigSNA" SG_ 1000 VC_SpecialPKG "FFh";
BA_ "GenSigSendType" SG_ 1000 VC_HdRstPrsnt 5;
BA_ "GenSigCycleTime" SG_ 1000 VC_HdRstPrsnt 500;
BA_ "FlexKomSigStartValue" SG_ 1000 VC_HdRstPrsnt "FFFF7FF0FF0FFF00h";
BA_ "FlexKomSID" SG_ 1000 VC_HdRstPrsnt 886;
BA_ "FlexKomSigStartPos" SG_ 1000 VC_HdRstPrsnt 7;
BA_ "FlexKomSigLaenge" SG_ 1000 VC_HdRstPrsnt 64;
BA_ "FlexKomSigName" SG_ 1000 VC_HdRstPrsnt "VehCfg1_Pkt";
BA_ "FlexKomComment" SG_ 1000 VC_HdRstPrsnt "Vehicle Configuration 1 Packet";
BA_ "FlexKomIsMotorola" SG_ 1000 VC_HdRstPrsnt 1;
BA_ "GenSigSNA" SG_ 1000 VC_HdRstPrsnt "0h";
BA_ "GenSigSendType" SG_ 1000 VC_SCR_Prsnt 5;
BA_ "GenSigCycleTime" SG_ 1000 VC_SCR_Prsnt 500;
BA_ "FlexKomSigStartValue" SG_ 1000 VC_SCR_Prsnt "FFFF7FF0FF0FFF00h";
BA_ "GenSigTimeout_IC" SG_ 1000 VC_SCR_Prsnt 5250;
BA_ "FlexKomSID" SG_ 1000 VC_SCR_Prsnt 886;
BA_ "FlexKomSigStartPos" SG_ 1000 VC_SCR_Prsnt 7;
BA_ "FlexKomSigLaenge" SG_ 1000 VC_SCR_Prsnt 64;
BA_ "FlexKomSigName" SG_ 1000 VC_SCR_Prsnt "VehCfg1_Pkt";
BA_ "FlexKomComment" SG_ 1000 VC_SCR_Prsnt "Vehicle Configuration 1 Packet";
BA_ "FlexKomIsMotorola" SG_ 1000 VC_SCR_Prsnt 1;
BA_ "GenSigSNA" SG_ 1000 VC_SCR_Prsnt "0h";
BA_ "GenSigSendType" SG_ 1000 VC_PTS_Config 5;
BA_ "GenSigCycleTime" SG_ 1000 VC_PTS_Config 500;
BA_ "FlexKomSigStartValue" SG_ 1000 VC_PTS_Config "FFFF7FF0FF0FFF00h";
BA_ "GenSigTimeout_IC" SG_ 1000 VC_PTS_Config 5250;
BA_ "GenSigTimeout_PTS" SG_ 1000 VC_PTS_Config 2750;
BA_ "FlexKomSID" SG_ 1000 VC_PTS_Config 886;
BA_ "FlexKomSigStartPos" SG_ 1000 VC_PTS_Config 7;
BA_ "FlexKomSigLaenge" SG_ 1000 VC_PTS_Config 64;
BA_ "FlexKomSigName" SG_ 1000 VC_PTS_Config "VehCfg1_Pkt";
BA_ "FlexKomComment" SG_ 1000 VC_PTS_Config "Vehicle Configuration 1 Packet";
BA_ "FlexKomIsMotorola" SG_ 1000 VC_PTS_Config 1;
BA_ "GenSigSNA" SG_ 1000 VC_PTS_Config "0h";
BA_ "GenSigSendType" SG_ 1000 VC_RVCM_Prsnt 5;
BA_ "GenSigCycleTime" SG_ 1000 VC_RVCM_Prsnt 500;
BA_ "FlexKomSigStartValue" SG_ 1000 VC_RVCM_Prsnt "FFFF7FF0FF0FFF00h";
BA_ "FlexKomSID" SG_ 1000 VC_RVCM_Prsnt 886;
BA_ "FlexKomSigStartPos" SG_ 1000 VC_RVCM_Prsnt 7;
BA_ "FlexKomSigLaenge" SG_ 1000 VC_RVCM_Prsnt 64;
BA_ "FlexKomSigName" SG_ 1000 VC_RVCM_Prsnt "VehCfg1_Pkt";
BA_ "FlexKomComment" SG_ 1000 VC_RVCM_Prsnt "Vehicle Configuration 1 Packet";
BA_ "FlexKomIsMotorola" SG_ 1000 VC_RVCM_Prsnt 1;
BA_ "GenSigSNA" SG_ 1000 VC_RVCM_Prsnt "0h";
BA_ "GenSigSendType" SG_ 1000 VC_CHMCM_Prsnt 5;
BA_ "GenSigCycleTime" SG_ 1000 VC_CHMCM_Prsnt 500;
BA_ "FlexKomSigStartValue" SG_ 1000 VC_CHMCM_Prsnt "FFFF7FF0FF0FFF00h";
BA_ "FlexKomSID" SG_ 1000 VC_CHMCM_Prsnt 886;
BA_ "FlexKomSigStartPos" SG_ 1000 VC_CHMCM_Prsnt 7;
BA_ "FlexKomSigLaenge" SG_ 1000 VC_CHMCM_Prsnt 64;
BA_ "FlexKomSigName" SG_ 1000 VC_CHMCM_Prsnt "VehCfg1_Pkt";
BA_ "FlexKomComment" SG_ 1000 VC_CHMCM_Prsnt "Vehicle Configuration 1 Packet";
BA_ "FlexKomIsMotorola" SG_ 1000 VC_CHMCM_Prsnt 1;
BA_ "GenSigSNA" SG_ 1000 VC_CHMCM_Prsnt "0h";
BA_ "GenSigSendType" SG_ 1000 VC_HDC_Prsnt 5;
BA_ "GenSigCycleTime" SG_ 1000 VC_HDC_Prsnt 500;
BA_ "FlexKomSigStartValue" SG_ 1000 VC_HDC_Prsnt "FFFF7FF0FF0FFF00h";
BA_ "GenSigTimeout_IC" SG_ 1000 VC_HDC_Prsnt 5250;
BA_ "FlexKomSID" SG_ 1000 VC_HDC_Prsnt 886;
BA_ "FlexKomSigStartPos" SG_ 1000 VC_HDC_Prsnt 7;
BA_ "FlexKomSigLaenge" SG_ 1000 VC_HDC_Prsnt 64;
BA_ "FlexKomSigName" SG_ 1000 VC_HDC_Prsnt "VehCfg1_Pkt";
BA_ "FlexKomComment" SG_ 1000 VC_HDC_Prsnt "Vehicle Configuration 1 Packet";
BA_ "FlexKomIsMotorola" SG_ 1000 VC_HDC_Prsnt 1;
BA_ "GenSigSNA" SG_ 1000 VC_HDC_Prsnt "0h";
BA_ "GenSigSendType" SG_ 1000 VC_SSC_Prsnt 5;
BA_ "GenSigCycleTime" SG_ 1000 VC_SSC_Prsnt 500;
BA_ "FlexKomSigStartValue" SG_ 1000 VC_SSC_Prsnt "FFFF7FF0FF0FFF00h";
BA_ "GenSigTimeout_IC" SG_ 1000 VC_SSC_Prsnt 5250;
BA_ "FlexKomSID" SG_ 1000 VC_SSC_Prsnt 886;
BA_ "FlexKomSigStartPos" SG_ 1000 VC_SSC_Prsnt 7;
BA_ "FlexKomSigLaenge" SG_ 1000 VC_SSC_Prsnt 64;
BA_ "FlexKomSigName" SG_ 1000 VC_SSC_Prsnt "VehCfg1_Pkt";
BA_ "FlexKomComment" SG_ 1000 VC_SSC_Prsnt "Vehicle Configuration 1 Packet";
BA_ "FlexKomIsMotorola" SG_ 1000 VC_SSC_Prsnt 1;
BA_ "GenSigSNA" SG_ 1000 VC_SSC_Prsnt "0h";
BA_ "GenSigSendType" SG_ 1001 VC_VehCfg2_Stat 5;
BA_ "GenSigCycleTime" SG_ 1001 VC_VehCfg2_Stat 2000;
BA_ "FlexKomSigStartValue" SG_ 1001 VC_VehCfg2_Stat "0300FF00FFFFFFFFh";
BA_ "GenSigStartValue" SG_ 1001 VC_VehCfg2_Stat 3;
BA_ "GenSigTimeout_IC" SG_ 1001 VC_VehCfg2_Stat 21000;
BA_ "GenSigTimeout_EPS" SG_ 1001 VC_VehCfg2_Stat 21000;
BA_ "GenSigTimeout_ECM" SG_ 1001 VC_VehCfg2_Stat 21000;
BA_ "GenSigTimeout_ADCM" SG_ 1001 VC_VehCfg2_Stat 21000;
BA_ "GenSigTimeout_ORC" SG_ 1001 VC_VehCfg2_Stat 7000;
BA_ "FlexKomSID" SG_ 1001 VC_VehCfg2_Stat 887;
BA_ "FlexKomSigStartPos" SG_ 1001 VC_VehCfg2_Stat 7;
BA_ "FlexKomSigLaenge" SG_ 1001 VC_VehCfg2_Stat 64;
BA_ "FlexKomSigName" SG_ 1001 VC_VehCfg2_Stat "VehCfg2_Pkt";
BA_ "FlexKomComment" SG_ 1001 VC_VehCfg2_Stat "Vehicle Configuration 2 Packet";
BA_ "FlexKomIsMotorola" SG_ 1001 VC_VehCfg2_Stat 1;
BA_ "GenSigSNA" SG_ 1001 VC_VehCfg2_Stat "3h";
BA_ "GenSigSendType" SG_ 1001 VC_PwrIvtrTyp 5;
BA_ "GenSigCycleTime" SG_ 1001 VC_PwrIvtrTyp 2000;
BA_ "FlexKomSigStartValue" SG_ 1001 VC_PwrIvtrTyp "0300FF00FFFFFFFFh";
BA_ "FlexKomSID" SG_ 1001 VC_PwrIvtrTyp 887;
BA_ "FlexKomSigStartPos" SG_ 1001 VC_PwrIvtrTyp 7;
BA_ "FlexKomSigLaenge" SG_ 1001 VC_PwrIvtrTyp 64;
BA_ "FlexKomSigName" SG_ 1001 VC_PwrIvtrTyp "VehCfg2_Pkt";
BA_ "FlexKomComment" SG_ 1001 VC_PwrIvtrTyp "Vehicle Configuration 2 Packet";
BA_ "FlexKomIsMotorola" SG_ 1001 VC_PwrIvtrTyp 1;
BA_ "GenSigSNA" SG_ 1001 VC_PwrIvtrTyp "0h";
BA_ "GenSigSendType" SG_ 1001 VC_ThatchamPrsnt 5;
BA_ "GenSigCycleTime" SG_ 1001 VC_ThatchamPrsnt 2000;
BA_ "FlexKomSigStartValue" SG_ 1001 VC_ThatchamPrsnt "0300FF00FFFFFFFFh";
BA_ "GenSigTimeout_IC" SG_ 1001 VC_ThatchamPrsnt 21000;
BA_ "FlexKomSID" SG_ 1001 VC_ThatchamPrsnt 887;
BA_ "FlexKomSigStartPos" SG_ 1001 VC_ThatchamPrsnt 7;
BA_ "FlexKomSigLaenge" SG_ 1001 VC_ThatchamPrsnt 64;
BA_ "FlexKomSigName" SG_ 1001 VC_ThatchamPrsnt "VehCfg2_Pkt";
BA_ "FlexKomComment" SG_ 1001 VC_ThatchamPrsnt "Vehicle Configuration 2 Packet";
BA_ "FlexKomIsMotorola" SG_ 1001 VC_ThatchamPrsnt 1;
BA_ "GenSigSNA" SG_ 1001 VC_ThatchamPrsnt "0h";
BA_ "GenSigSendType" SG_ 1001 VC_RunFlatTirePrsnt 5;
BA_ "GenSigCycleTime" SG_ 1001 VC_RunFlatTirePrsnt 2000;
BA_ "FlexKomSigStartValue" SG_ 1001 VC_RunFlatTirePrsnt "0300FF00FFFFFFFFh";
BA_ "GenSigTimeout_IC" SG_ 1001 VC_RunFlatTirePrsnt 21000;
BA_ "GenSigTimeout_TPM" SG_ 1001 VC_RunFlatTirePrsnt 21000;
BA_ "FlexKomSID" SG_ 1001 VC_RunFlatTirePrsnt 887;
BA_ "FlexKomSigStartPos" SG_ 1001 VC_RunFlatTirePrsnt 7;
BA_ "FlexKomSigLaenge" SG_ 1001 VC_RunFlatTirePrsnt 64;
BA_ "FlexKomSigName" SG_ 1001 VC_RunFlatTirePrsnt "VehCfg2_Pkt";
BA_ "FlexKomComment" SG_ 1001 VC_RunFlatTirePrsnt "Vehicle Configuration 2 Packet";
BA_ "FlexKomIsMotorola" SG_ 1001 VC_RunFlatTirePrsnt 1;
BA_ "GenSigSNA" SG_ 1001 VC_RunFlatTirePrsnt "0h";
BA_ "GenSigSendType" SG_ 1001 VC_MaseratiMd 5;
BA_ "GenSigCycleTime" SG_ 1001 VC_MaseratiMd 2000;
BA_ "FlexKomSigStartValue" SG_ 1001 VC_MaseratiMd "0300FF00FFFFFFFFh";
BA_ "FlexKomSID" SG_ 1001 VC_MaseratiMd 887;
BA_ "FlexKomSigStartPos" SG_ 1001 VC_MaseratiMd 7;
BA_ "FlexKomSigLaenge" SG_ 1001 VC_MaseratiMd 64;
BA_ "FlexKomSigName" SG_ 1001 VC_MaseratiMd "VehCfg2_Pkt";
BA_ "FlexKomComment" SG_ 1001 VC_MaseratiMd "Vehicle Configuration 2 Packet";
BA_ "FlexKomIsMotorola" SG_ 1001 VC_MaseratiMd 1;
BA_ "GenSigSNA" SG_ 1001 VC_MaseratiMd "3h";
BA_ "GenSigSendType" SG_ 1001 VC_PADS_Prsnt 5;
BA_ "GenSigCycleTime" SG_ 1001 VC_PADS_Prsnt 2000;
BA_ "FlexKomSigStartValue" SG_ 1001 VC_PADS_Prsnt "0300FF00FFFFFFFFh";
BA_ "GenSigTimeout_ORC" SG_ 1001 VC_PADS_Prsnt 7000;
BA_ "FlexKomSID" SG_ 1001 VC_PADS_Prsnt 887;
BA_ "FlexKomSigStartPos" SG_ 1001 VC_PADS_Prsnt 7;
BA_ "FlexKomSigLaenge" SG_ 1001 VC_PADS_Prsnt 64;
BA_ "FlexKomSigName" SG_ 1001 VC_PADS_Prsnt "VehCfg2_Pkt";
BA_ "FlexKomComment" SG_ 1001 VC_PADS_Prsnt "Vehicle Configuration 2 Packet";
BA_ "FlexKomIsMotorola" SG_ 1001 VC_PADS_Prsnt 1;
BA_ "GenSigSNA" SG_ 1001 VC_PADS_Prsnt "0h";
BA_ "GenSigSendType" SG_ 1001 VC_RainSnsPrsnt 5;
BA_ "GenSigCycleTime" SG_ 1001 VC_RainSnsPrsnt 2000;
BA_ "FlexKomSigStartValue" SG_ 1001 VC_RainSnsPrsnt "0300FF00FFFFFFFFh";
BA_ "GenSigTimeout_IC" SG_ 1001 VC_RainSnsPrsnt 21000;
BA_ "FlexKomSID" SG_ 1001 VC_RainSnsPrsnt 887;
BA_ "FlexKomSigStartPos" SG_ 1001 VC_RainSnsPrsnt 7;
BA_ "FlexKomSigLaenge" SG_ 1001 VC_RainSnsPrsnt 64;
BA_ "FlexKomSigName" SG_ 1001 VC_RainSnsPrsnt "VehCfg2_Pkt";
BA_ "FlexKomComment" SG_ 1001 VC_RainSnsPrsnt "Vehicle Configuration 2 Packet";
BA_ "FlexKomIsMotorola" SG_ 1001 VC_RainSnsPrsnt 1;
BA_ "GenSigSNA" SG_ 1001 VC_RainSnsPrsnt "0h";
BA_ "GenSigSendType" SG_ 1001 VC_SKIM_PRSNT 5;
BA_ "GenSigCycleTime" SG_ 1001 VC_SKIM_PRSNT 2000;
BA_ "FlexKomSigStartValue" SG_ 1001 VC_SKIM_PRSNT "0300FF00FFFFFFFFh";
BA_ "FlexKomSID" SG_ 1001 VC_SKIM_PRSNT 887;
BA_ "FlexKomSigStartPos" SG_ 1001 VC_SKIM_PRSNT 7;
BA_ "FlexKomSigLaenge" SG_ 1001 VC_SKIM_PRSNT 64;
BA_ "FlexKomSigName" SG_ 1001 VC_SKIM_PRSNT "VehCfg2_Pkt";
BA_ "FlexKomComment" SG_ 1001 VC_SKIM_PRSNT "Vehicle Configuration 2 Packet";
BA_ "FlexKomIsMotorola" SG_ 1001 VC_SKIM_PRSNT 1;
BA_ "GenSigSNA" SG_ 1001 VC_SKIM_PRSNT "0h";
BA_ "GenSigSendType" SG_ 1001 VC_AC_Prsnt 5;
BA_ "GenSigCycleTime" SG_ 1001 VC_AC_Prsnt 2000;
BA_ "FlexKomSigStartValue" SG_ 1001 VC_AC_Prsnt "0300FF00FFFFFFFFh";
BA_ "FlexKomSID" SG_ 1001 VC_AC_Prsnt 887;
BA_ "FlexKomSigStartPos" SG_ 1001 VC_AC_Prsnt 7;
BA_ "FlexKomSigLaenge" SG_ 1001 VC_AC_Prsnt 64;
BA_ "FlexKomSigName" SG_ 1001 VC_AC_Prsnt "VehCfg2_Pkt";
BA_ "FlexKomComment" SG_ 1001 VC_AC_Prsnt "Vehicle Configuration 2 Packet";
BA_ "FlexKomIsMotorola" SG_ 1001 VC_AC_Prsnt 1;
BA_ "GenSigSNA" SG_ 1001 VC_AC_Prsnt "0h";
BA_ "GenSigSendType" SG_ 1001 VC_CRUISE_PRSNT 5;
BA_ "GenSigCycleTime" SG_ 1001 VC_CRUISE_PRSNT 2000;
BA_ "FlexKomSigStartValue" SG_ 1001 VC_CRUISE_PRSNT "0300FF00FFFFFFFFh";
BA_ "GenSigTimeout_IC" SG_ 1001 VC_CRUISE_PRSNT 21000;
BA_ "FlexKomSID" SG_ 1001 VC_CRUISE_PRSNT 887;
BA_ "FlexKomSigStartPos" SG_ 1001 VC_CRUISE_PRSNT 7;
BA_ "FlexKomSigLaenge" SG_ 1001 VC_CRUISE_PRSNT 64;
BA_ "FlexKomSigName" SG_ 1001 VC_CRUISE_PRSNT "VehCfg2_Pkt";
BA_ "FlexKomComment" SG_ 1001 VC_CRUISE_PRSNT "Vehicle Configuration 2 Packet";
BA_ "FlexKomIsMotorola" SG_ 1001 VC_CRUISE_PRSNT 1;
BA_ "GenSigSNA" SG_ 1001 VC_CRUISE_PRSNT "0h";
BA_ "GenSigSendType" SG_ 1001 VC_FG_PRSNT 5;
BA_ "GenSigCycleTime" SG_ 1001 VC_FG_PRSNT 2000;
BA_ "FlexKomSigStartValue" SG_ 1001 VC_FG_PRSNT "0300FF00FFFFFFFFh";
BA_ "GenSigTimeout_IC" SG_ 1001 VC_FG_PRSNT 21000;
BA_ "FlexKomSID" SG_ 1001 VC_FG_PRSNT 887;
BA_ "FlexKomSigStartPos" SG_ 1001 VC_FG_PRSNT 7;
BA_ "FlexKomSigLaenge" SG_ 1001 VC_FG_PRSNT 64;
BA_ "FlexKomSigName" SG_ 1001 VC_FG_PRSNT "VehCfg2_Pkt";
BA_ "FlexKomComment" SG_ 1001 VC_FG_PRSNT "Vehicle Configuration 2 Packet";
BA_ "FlexKomIsMotorola" SG_ 1001 VC_FG_PRSNT 1;
BA_ "GenSigSNA" SG_ 1001 VC_FG_PRSNT "0h";
BA_ "GenSigSendType" SG_ 1001 VC_FULL_SPARE 5;
BA_ "GenSigCycleTime" SG_ 1001 VC_FULL_SPARE 2000;
BA_ "FlexKomSigStartValue" SG_ 1001 VC_FULL_SPARE "0300FF00FFFFFFFFh";
BA_ "GenSigTimeout_TPM" SG_ 1001 VC_FULL_SPARE 21000;
BA_ "FlexKomSID" SG_ 1001 VC_FULL_SPARE 887;
BA_ "FlexKomSigStartPos" SG_ 1001 VC_FULL_SPARE 7;
BA_ "FlexKomSigLaenge" SG_ 1001 VC_FULL_SPARE 64;
BA_ "FlexKomSigName" SG_ 1001 VC_FULL_SPARE "VehCfg2_Pkt";
BA_ "FlexKomComment" SG_ 1001 VC_FULL_SPARE "Vehicle Configuration 2 Packet";
BA_ "FlexKomIsMotorola" SG_ 1001 VC_FULL_SPARE 1;
BA_ "GenSigSNA" SG_ 1001 VC_FULL_SPARE "0h";
BA_ "GenSigSendType" SG_ 1001 VC_OffRoad 5;
BA_ "GenSigCycleTime" SG_ 1001 VC_OffRoad 2000;
BA_ "FlexKomSigStartValue" SG_ 1001 VC_OffRoad "0300FF00FFFFFFFFh";
BA_ "GenSigTimeout_IC" SG_ 1001 VC_OffRoad 21000;
BA_ "FlexKomSID" SG_ 1001 VC_OffRoad 887;
BA_ "FlexKomSigStartPos" SG_ 1001 VC_OffRoad 7;
BA_ "FlexKomSigLaenge" SG_ 1001 VC_OffRoad 64;
BA_ "FlexKomSigName" SG_ 1001 VC_OffRoad "VehCfg2_Pkt";
BA_ "FlexKomComment" SG_ 1001 VC_OffRoad "Vehicle Configuration 2 Packet";
BA_ "FlexKomIsMotorola" SG_ 1001 VC_OffRoad 1;
BA_ "GenSigSNA" SG_ 1001 VC_OffRoad "0h";
BA_ "GenSigSendType" SG_ 1001 VC_SpecialPKG_IC 5;
BA_ "GenSigCycleTime" SG_ 1001 VC_SpecialPKG_IC 2000;
BA_ "FlexKomSigStartValue" SG_ 1001 VC_SpecialPKG_IC "0300FF00FFFFFFFFh";
BA_ "GenSigStartValue" SG_ 1001 VC_SpecialPKG_IC 255;
BA_ "GenSigTimeout_IC" SG_ 1001 VC_SpecialPKG_IC 21000;
BA_ "FlexKomSID" SG_ 1001 VC_SpecialPKG_IC 887;
BA_ "FlexKomSigStartPos" SG_ 1001 VC_SpecialPKG_IC 7;
BA_ "FlexKomSigLaenge" SG_ 1001 VC_SpecialPKG_IC 64;
BA_ "FlexKomSigName" SG_ 1001 VC_SpecialPKG_IC "VehCfg2_Pkt";
BA_ "FlexKomComment" SG_ 1001 VC_SpecialPKG_IC "Vehicle Configuration 2 Packet";
BA_ "FlexKomIsMotorola" SG_ 1001 VC_SpecialPKG_IC 1;
BA_ "GenSigSNA" SG_ 1001 VC_SpecialPKG_IC "FFh";
BA_ "GenSigSendType" SG_ 1001 VC_ECO_Indicator 5;
BA_ "GenSigCycleTime" SG_ 1001 VC_ECO_Indicator 2000;
BA_ "FlexKomSigStartValue" SG_ 1001 VC_ECO_Indicator "0300FF00FFFFFFFFh";
BA_ "GenSigTimeout_IC" SG_ 1001 VC_ECO_Indicator 21000;
BA_ "FlexKomSID" SG_ 1001 VC_ECO_Indicator 887;
BA_ "FlexKomSigStartPos" SG_ 1001 VC_ECO_Indicator 7;
BA_ "FlexKomSigLaenge" SG_ 1001 VC_ECO_Indicator 64;
BA_ "FlexKomSigName" SG_ 1001 VC_ECO_Indicator "VehCfg2_Pkt";
BA_ "FlexKomComment" SG_ 1001 VC_ECO_Indicator "Vehicle Configuration 2 Packet";
BA_ "FlexKomIsMotorola" SG_ 1001 VC_ECO_Indicator 1;
BA_ "GenSigSNA" SG_ 1001 VC_ECO_Indicator "0h";
BA_ "GenSigSendType" SG_ 1001 VC_DRVMD_Prsnt 5;
BA_ "GenSigCycleTime" SG_ 1001 VC_DRVMD_Prsnt 2000;
BA_ "FlexKomSigStartValue" SG_ 1001 VC_DRVMD_Prsnt "0300FF00FFFFFFFFh";
BA_ "GenSigTimeout_EPS" SG_ 1001 VC_DRVMD_Prsnt 21000;
BA_ "GenSigTimeout_ECM" SG_ 1001 VC_DRVMD_Prsnt 21000;
BA_ "GenSigTimeout_ADCM" SG_ 1001 VC_DRVMD_Prsnt 21000;
BA_ "FlexKomSID" SG_ 1001 VC_DRVMD_Prsnt 887;
BA_ "FlexKomSigStartPos" SG_ 1001 VC_DRVMD_Prsnt 7;
BA_ "FlexKomSigLaenge" SG_ 1001 VC_DRVMD_Prsnt 64;
BA_ "FlexKomSigName" SG_ 1001 VC_DRVMD_Prsnt "VehCfg2_Pkt";
BA_ "FlexKomComment" SG_ 1001 VC_DRVMD_Prsnt "Vehicle Configuration 2 Packet";
BA_ "FlexKomIsMotorola" SG_ 1001 VC_DRVMD_Prsnt 1;
BA_ "GenSigSNA" SG_ 1001 VC_DRVMD_Prsnt "0h";
BA_ "GenSigSendType" SG_ 1001 VC_MemoryDRVMD_Prsnt 5;
BA_ "GenSigCycleTime" SG_ 1001 VC_MemoryDRVMD_Prsnt 2000;
BA_ "FlexKomSigStartValue" SG_ 1001 VC_MemoryDRVMD_Prsnt "0300FF00FFFFFFFFh";
BA_ "GenSigTimeout_EPS" SG_ 1001 VC_MemoryDRVMD_Prsnt 21000;
BA_ "GenSigTimeout_ECM" SG_ 1001 VC_MemoryDRVMD_Prsnt 21000;
BA_ "GenSigTimeout_ADCM" SG_ 1001 VC_MemoryDRVMD_Prsnt 21000;
BA_ "FlexKomSID" SG_ 1001 VC_MemoryDRVMD_Prsnt 887;
BA_ "FlexKomSigStartPos" SG_ 1001 VC_MemoryDRVMD_Prsnt 7;
BA_ "FlexKomSigLaenge" SG_ 1001 VC_MemoryDRVMD_Prsnt 64;
BA_ "FlexKomSigName" SG_ 1001 VC_MemoryDRVMD_Prsnt "VehCfg2_Pkt";
BA_ "FlexKomComment" SG_ 1001 VC_MemoryDRVMD_Prsnt "Vehicle Configuration 2 Packet";
BA_ "FlexKomIsMotorola" SG_ 1001 VC_MemoryDRVMD_Prsnt 1;
BA_ "GenSigSNA" SG_ 1001 VC_MemoryDRVMD_Prsnt "0h";
BA_ "GenSigSendType" SG_ 1001 VC_ESCDrvMd_Prsnt 5;
BA_ "GenSigCycleTime" SG_ 1001 VC_ESCDrvMd_Prsnt 2000;
BA_ "FlexKomSigStartValue" SG_ 1001 VC_ESCDrvMd_Prsnt "0300FF00FFFFFFFFh";
BA_ "GenSigTimeout_IC" SG_ 1001 VC_ESCDrvMd_Prsnt 21000;
BA_ "FlexKomSID" SG_ 1001 VC_ESCDrvMd_Prsnt 887;
BA_ "FlexKomSigStartPos" SG_ 1001 VC_ESCDrvMd_Prsnt 7;
BA_ "FlexKomSigLaenge" SG_ 1001 VC_ESCDrvMd_Prsnt 64;
BA_ "FlexKomSigName" SG_ 1001 VC_ESCDrvMd_Prsnt "VehCfg2_Pkt";
BA_ "FlexKomComment" SG_ 1001 VC_ESCDrvMd_Prsnt "Vehicle Configuration 2 Packet";
BA_ "FlexKomIsMotorola" SG_ 1001 VC_ESCDrvMd_Prsnt 1;
BA_ "GenSigSNA" SG_ 1001 VC_ESCDrvMd_Prsnt "0h";
BA_ "GenSigSendType" SG_ 1001 VC_EngPowerDrvMd_Prsnt 5;
BA_ "GenSigCycleTime" SG_ 1001 VC_EngPowerDrvMd_Prsnt 2000;
BA_ "FlexKomSigStartValue" SG_ 1001 VC_EngPowerDrvMd_Prsnt "0300FF00FFFFFFFFh";
BA_ "GenSigTimeout_IC" SG_ 1001 VC_EngPowerDrvMd_Prsnt 21000;
BA_ "FlexKomSID" SG_ 1001 VC_EngPowerDrvMd_Prsnt 887;
BA_ "FlexKomSigStartPos" SG_ 1001 VC_EngPowerDrvMd_Prsnt 7;
BA_ "FlexKomSigLaenge" SG_ 1001 VC_EngPowerDrvMd_Prsnt 64;
BA_ "FlexKomSigName" SG_ 1001 VC_EngPowerDrvMd_Prsnt "VehCfg2_Pkt";
BA_ "FlexKomComment" SG_ 1001 VC_EngPowerDrvMd_Prsnt "Vehicle Configuration 2 Packet";
BA_ "FlexKomIsMotorola" SG_ 1001 VC_EngPowerDrvMd_Prsnt 1;
BA_ "GenSigSNA" SG_ 1001 VC_EngPowerDrvMd_Prsnt "0h";
BA_ "GenSigSendType" SG_ 1001 VC_SecPrkPrsnt 5;
BA_ "GenSigCycleTime" SG_ 1001 VC_SecPrkPrsnt 2000;
BA_ "FlexKomSigStartValue" SG_ 1001 VC_SecPrkPrsnt "0300FF00FFFFFFFFh";
BA_ "GenSigTimeout_IC" SG_ 1001 VC_SecPrkPrsnt 21000;
BA_ "FlexKomSID" SG_ 1001 VC_SecPrkPrsnt 887;
BA_ "FlexKomSigStartPos" SG_ 1001 VC_SecPrkPrsnt 7;
BA_ "FlexKomSigLaenge" SG_ 1001 VC_SecPrkPrsnt 64;
BA_ "FlexKomSigName" SG_ 1001 VC_SecPrkPrsnt "VehCfg2_Pkt";
BA_ "FlexKomComment" SG_ 1001 VC_SecPrkPrsnt "Vehicle Configuration 2 Packet";
BA_ "FlexKomIsMotorola" SG_ 1001 VC_SecPrkPrsnt 1;
BA_ "GenSigSNA" SG_ 1001 VC_SecPrkPrsnt "0h";
BA_ "GenSigSendType" SG_ 1001 VC_ShftInd_Prsnt 5;
BA_ "GenSigCycleTime" SG_ 1001 VC_ShftInd_Prsnt 2000;
BA_ "FlexKomSigStartValue" SG_ 1001 VC_ShftInd_Prsnt "0300FF00FFFFFFFFh";
BA_ "GenSigTimeout_IC" SG_ 1001 VC_ShftInd_Prsnt 21000;
BA_ "FlexKomSID" SG_ 1001 VC_ShftInd_Prsnt 887;
BA_ "FlexKomSigStartPos" SG_ 1001 VC_ShftInd_Prsnt 7;
BA_ "FlexKomSigLaenge" SG_ 1001 VC_ShftInd_Prsnt 64;
BA_ "FlexKomSigName" SG_ 1001 VC_ShftInd_Prsnt "VehCfg2_Pkt";
BA_ "FlexKomComment" SG_ 1001 VC_ShftInd_Prsnt "Vehicle Configuration 2 Packet";
BA_ "FlexKomIsMotorola" SG_ 1001 VC_ShftInd_Prsnt 1;
BA_ "GenSigSNA" SG_ 1001 VC_ShftInd_Prsnt "0h";
BA_ "GenSigSendType" SG_ 1001 VC_MaxLdPressRrTr 5;
BA_ "GenSigCycleTime" SG_ 1001 VC_MaxLdPressRrTr 2000;
BA_ "FlexKomSigStartValue" SG_ 1001 VC_MaxLdPressRrTr "0300FF00FFFFFFFFh";
BA_ "GenSigStartValue" SG_ 1001 VC_MaxLdPressRrTr 255;
BA_ "GenSigTimeout_IC" SG_ 1001 VC_MaxLdPressRrTr 21000;
BA_ "GenSigTimeout_TPM" SG_ 1001 VC_MaxLdPressRrTr 21000;
BA_ "FlexKomSID" SG_ 1001 VC_MaxLdPressRrTr 887;
BA_ "FlexKomSigStartPos" SG_ 1001 VC_MaxLdPressRrTr 7;
BA_ "FlexKomSigLaenge" SG_ 1001 VC_MaxLdPressRrTr 64;
BA_ "FlexKomSigName" SG_ 1001 VC_MaxLdPressRrTr "VehCfg2_Pkt";
BA_ "FlexKomComment" SG_ 1001 VC_MaxLdPressRrTr "Vehicle Configuration 2 Packet";
BA_ "FlexKomIsMotorola" SG_ 1001 VC_MaxLdPressRrTr 1;
BA_ "GenSigSNA" SG_ 1001 VC_MaxLdPressRrTr "FFh";
BA_ "GenSigSendType" SG_ 1001 VC_MaxLdPressFtTr 5;
BA_ "GenSigCycleTime" SG_ 1001 VC_MaxLdPressFtTr 2000;
BA_ "FlexKomSigStartValue" SG_ 1001 VC_MaxLdPressFtTr "0300FF00FFFFFFFFh";
BA_ "GenSigStartValue" SG_ 1001 VC_MaxLdPressFtTr 255;
BA_ "GenSigTimeout_IC" SG_ 1001 VC_MaxLdPressFtTr 21000;
BA_ "GenSigTimeout_TPM" SG_ 1001 VC_MaxLdPressFtTr 21000;
BA_ "FlexKomSID" SG_ 1001 VC_MaxLdPressFtTr 887;
BA_ "FlexKomSigStartPos" SG_ 1001 VC_MaxLdPressFtTr 7;
BA_ "FlexKomSigLaenge" SG_ 1001 VC_MaxLdPressFtTr 64;
BA_ "FlexKomSigName" SG_ 1001 VC_MaxLdPressFtTr "VehCfg2_Pkt";
BA_ "FlexKomComment" SG_ 1001 VC_MaxLdPressFtTr "Vehicle Configuration 2 Packet";
BA_ "FlexKomIsMotorola" SG_ 1001 VC_MaxLdPressFtTr 1;
BA_ "GenSigSNA" SG_ 1001 VC_MaxLdPressFtTr "FFh";
BA_ "GenSigSendType" SG_ 1001 VC_LgtLdPressRrTr 5;
BA_ "GenSigCycleTime" SG_ 1001 VC_LgtLdPressRrTr 2000;
BA_ "FlexKomSigStartValue" SG_ 1001 VC_LgtLdPressRrTr "0300FF00FFFFFFFFh";
BA_ "GenSigStartValue" SG_ 1001 VC_LgtLdPressRrTr 255;
BA_ "GenSigTimeout_IC" SG_ 1001 VC_LgtLdPressRrTr 21000;
BA_ "GenSigTimeout_TPM" SG_ 1001 VC_LgtLdPressRrTr 21000;
BA_ "FlexKomSID" SG_ 1001 VC_LgtLdPressRrTr 887;
BA_ "FlexKomSigStartPos" SG_ 1001 VC_LgtLdPressRrTr 7;
BA_ "FlexKomSigLaenge" SG_ 1001 VC_LgtLdPressRrTr 64;
BA_ "FlexKomSigName" SG_ 1001 VC_LgtLdPressRrTr "VehCfg2_Pkt";
BA_ "FlexKomComment" SG_ 1001 VC_LgtLdPressRrTr "Vehicle Configuration 2 Packet";
BA_ "FlexKomIsMotorola" SG_ 1001 VC_LgtLdPressRrTr 1;
BA_ "GenSigSNA" SG_ 1001 VC_LgtLdPressRrTr "FFh";
BA_ "GenSigSendType" SG_ 1001 VC_LgtLdPressFtTr 5;
BA_ "GenSigCycleTime" SG_ 1001 VC_LgtLdPressFtTr 2000;
BA_ "FlexKomSigStartValue" SG_ 1001 VC_LgtLdPressFtTr "0300FF00FFFFFFFFh";
BA_ "GenSigStartValue" SG_ 1001 VC_LgtLdPressFtTr 255;
BA_ "GenSigTimeout_IC" SG_ 1001 VC_LgtLdPressFtTr 21000;
BA_ "GenSigTimeout_TPM" SG_ 1001 VC_LgtLdPressFtTr 21000;
BA_ "FlexKomSID" SG_ 1001 VC_LgtLdPressFtTr 887;
BA_ "FlexKomSigStartPos" SG_ 1001 VC_LgtLdPressFtTr 7;
BA_ "FlexKomSigLaenge" SG_ 1001 VC_LgtLdPressFtTr 64;
BA_ "FlexKomSigName" SG_ 1001 VC_LgtLdPressFtTr "VehCfg2_Pkt";
BA_ "FlexKomComment" SG_ 1001 VC_LgtLdPressFtTr "Vehicle Configuration 2 Packet";
BA_ "FlexKomIsMotorola" SG_ 1001 VC_LgtLdPressFtTr 1;
BA_ "GenSigSNA" SG_ 1001 VC_LgtLdPressFtTr "FFh";
BA_ "GenSigSendType" SG_ 1002 VC_VehCfg3_Stat 5;
BA_ "GenSigCycleTime" SG_ 1002 VC_VehCfg3_Stat 2000;
BA_ "FlexKomSigStartValue" SG_ 1002 VC_VehCfg3_Stat "0370FF037FFF0000h";
BA_ "GenSigStartValue" SG_ 1002 VC_VehCfg3_Stat 3;
BA_ "GenSigTimeout_IC" SG_ 1002 VC_VehCfg3_Stat 21000;
BA_ "GenSigTimeout_TPM" SG_ 1002 VC_VehCfg3_Stat 21000;
BA_ "GenSigTimeout_EPS" SG_ 1002 VC_VehCfg3_Stat 21000;
BA_ "GenSigTimeout_ORC" SG_ 1002 VC_VehCfg3_Stat 7000;
BA_ "FlexKomSID" SG_ 1002 VC_VehCfg3_Stat 888;
BA_ "FlexKomSigStartPos" SG_ 1002 VC_VehCfg3_Stat 7;
BA_ "FlexKomSigLaenge" SG_ 1002 VC_VehCfg3_Stat 64;
BA_ "FlexKomSigName" SG_ 1002 VC_VehCfg3_Stat "VehCfg3_Pkt";
BA_ "FlexKomComment" SG_ 1002 VC_VehCfg3_Stat "Vehicle Configuration 3 Packet";
BA_ "FlexKomIsMotorola" SG_ 1002 VC_VehCfg3_Stat 1;
BA_ "GenSigSNA" SG_ 1002 VC_VehCfg3_Stat "3h";
BA_ "GenSigSendType" SG_ 1002 VC_POLICE 5;
BA_ "GenSigCycleTime" SG_ 1002 VC_POLICE 2000;
BA_ "FlexKomSigStartValue" SG_ 1002 VC_POLICE "0370FF037FFF0000h";
BA_ "GenSigTimeout_IC" SG_ 1002 VC_POLICE 21000;
BA_ "GenSigTimeout_ORC" SG_ 1002 VC_POLICE 7000;
BA_ "FlexKomSID" SG_ 1002 VC_POLICE 888;
BA_ "FlexKomSigStartPos" SG_ 1002 VC_POLICE 7;
BA_ "FlexKomSigLaenge" SG_ 1002 VC_POLICE 64;
BA_ "FlexKomSigName" SG_ 1002 VC_POLICE "VehCfg3_Pkt";
BA_ "FlexKomComment" SG_ 1002 VC_POLICE "Vehicle Configuration 3 Packet";
BA_ "FlexKomIsMotorola" SG_ 1002 VC_POLICE 1;
BA_ "GenSigSNA" SG_ 1002 VC_POLICE "0h";
BA_ "GenSigSendType" SG_ 1002 VC_PWR_LFT_GT 5;
BA_ "GenSigCycleTime" SG_ 1002 VC_PWR_LFT_GT 2000;
BA_ "FlexKomSigStartValue" SG_ 1002 VC_PWR_LFT_GT "0370FF037FFF0000h";
BA_ "FlexKomSID" SG_ 1002 VC_PWR_LFT_GT 888;
BA_ "FlexKomSigStartPos" SG_ 1002 VC_PWR_LFT_GT 7;
BA_ "FlexKomSigLaenge" SG_ 1002 VC_PWR_LFT_GT 64;
BA_ "FlexKomSigName" SG_ 1002 VC_PWR_LFT_GT "VehCfg3_Pkt";
BA_ "FlexKomComment" SG_ 1002 VC_PWR_LFT_GT "Vehicle Configuration 3 Packet";
BA_ "FlexKomIsMotorola" SG_ 1002 VC_PWR_LFT_GT 1;
BA_ "GenSigSNA" SG_ 1002 VC_PWR_LFT_GT "0h";
BA_ "GenSigSendType" SG_ 1002 VC_PWR_RT_SLDR 5;
BA_ "GenSigCycleTime" SG_ 1002 VC_PWR_RT_SLDR 2000;
BA_ "FlexKomSigStartValue" SG_ 1002 VC_PWR_RT_SLDR "0370FF037FFF0000h";
BA_ "FlexKomSID" SG_ 1002 VC_PWR_RT_SLDR 888;
BA_ "FlexKomSigStartPos" SG_ 1002 VC_PWR_RT_SLDR 7;
BA_ "FlexKomSigLaenge" SG_ 1002 VC_PWR_RT_SLDR 64;
BA_ "FlexKomSigName" SG_ 1002 VC_PWR_RT_SLDR "VehCfg3_Pkt";
BA_ "FlexKomComment" SG_ 1002 VC_PWR_RT_SLDR "Vehicle Configuration 3 Packet";
BA_ "FlexKomIsMotorola" SG_ 1002 VC_PWR_RT_SLDR 1;
BA_ "GenSigSNA" SG_ 1002 VC_PWR_RT_SLDR "0h";
BA_ "GenSigSendType" SG_ 1002 VC_PWR_LT_SLDR 5;
BA_ "GenSigCycleTime" SG_ 1002 VC_PWR_LT_SLDR 2000;
BA_ "FlexKomSigStartValue" SG_ 1002 VC_PWR_LT_SLDR "0370FF037FFF0000h";
BA_ "FlexKomSID" SG_ 1002 VC_PWR_LT_SLDR 888;
BA_ "FlexKomSigStartPos" SG_ 1002 VC_PWR_LT_SLDR 7;
BA_ "FlexKomSigLaenge" SG_ 1002 VC_PWR_LT_SLDR 64;
BA_ "FlexKomSigName" SG_ 1002 VC_PWR_LT_SLDR "VehCfg3_Pkt";
BA_ "FlexKomComment" SG_ 1002 VC_PWR_LT_SLDR "Vehicle Configuration 3 Packet";
BA_ "FlexKomIsMotorola" SG_ 1002 VC_PWR_LT_SLDR 1;
BA_ "GenSigSNA" SG_ 1002 VC_PWR_LT_SLDR "0h";
BA_ "GenSigSendType" SG_ 1002 VC_RKE_PRSNT 5;
BA_ "GenSigCycleTime" SG_ 1002 VC_RKE_PRSNT 2000;
BA_ "FlexKomSigStartValue" SG_ 1002 VC_RKE_PRSNT "0370FF037FFF0000h";
BA_ "GenSigTimeout_IC" SG_ 1002 VC_RKE_PRSNT 21000;
BA_ "FlexKomSID" SG_ 1002 VC_RKE_PRSNT 888;
BA_ "FlexKomSigStartPos" SG_ 1002 VC_RKE_PRSNT 7;
BA_ "FlexKomSigLaenge" SG_ 1002 VC_RKE_PRSNT 64;
BA_ "FlexKomSigName" SG_ 1002 VC_RKE_PRSNT "VehCfg3_Pkt";
BA_ "FlexKomComment" SG_ 1002 VC_RKE_PRSNT "Vehicle Configuration 3 Packet";
BA_ "FlexKomIsMotorola" SG_ 1002 VC_RKE_PRSNT 1;
BA_ "GenSigSNA" SG_ 1002 VC_RKE_PRSNT "0h";
BA_ "GenSigSendType" SG_ 1002 VC_SunShade_Present 5;
BA_ "GenSigCycleTime" SG_ 1002 VC_SunShade_Present 2000;
BA_ "FlexKomSigStartValue" SG_ 1002 VC_SunShade_Present "0370FF037FFF0000h";
BA_ "FlexKomSID" SG_ 1002 VC_SunShade_Present 888;
BA_ "FlexKomSigStartPos" SG_ 1002 VC_SunShade_Present 7;
BA_ "FlexKomSigLaenge" SG_ 1002 VC_SunShade_Present 64;
BA_ "FlexKomSigName" SG_ 1002 VC_SunShade_Present "VehCfg3_Pkt";
BA_ "FlexKomComment" SG_ 1002 VC_SunShade_Present "Vehicle Configuration 3 Packet";
BA_ "FlexKomIsMotorola" SG_ 1002 VC_SunShade_Present 1;
BA_ "GenSigSNA" SG_ 1002 VC_SunShade_Present "0h";
BA_ "GenSigSendType" SG_ 1002 VC_TcaseTyp 5;
BA_ "GenSigCycleTime" SG_ 1002 VC_TcaseTyp 2000;
BA_ "FlexKomSigStartValue" SG_ 1002 VC_TcaseTyp "0370FF037FFF0000h";
BA_ "FlexKomSID" SG_ 1002 VC_TcaseTyp 888;
BA_ "FlexKomSigStartPos" SG_ 1002 VC_TcaseTyp 7;
BA_ "FlexKomSigLaenge" SG_ 1002 VC_TcaseTyp 64;
BA_ "FlexKomSigName" SG_ 1002 VC_TcaseTyp "VehCfg3_Pkt";
BA_ "FlexKomComment" SG_ 1002 VC_TcaseTyp "Vehicle Configuration 3 Packet";
BA_ "FlexKomIsMotorola" SG_ 1002 VC_TcaseTyp 1;
BA_ "GenSigSNA" SG_ 1002 VC_TcaseTyp "0h";
BA_ "GenSigSendType" SG_ 1002 VC_WHL_BASE 5;
BA_ "GenSigCycleTime" SG_ 1002 VC_WHL_BASE 2000;
BA_ "FlexKomSigStartValue" SG_ 1002 VC_WHL_BASE "0370FF037FFF0000h";
BA_ "GenSigStartValue" SG_ 1002 VC_WHL_BASE 3;
BA_ "GenSigTimeout_ORC" SG_ 1002 VC_WHL_BASE 7000;
BA_ "FlexKomSID" SG_ 1002 VC_WHL_BASE 888;
BA_ "FlexKomSigStartPos" SG_ 1002 VC_WHL_BASE 7;
BA_ "FlexKomSigLaenge" SG_ 1002 VC_WHL_BASE 64;
BA_ "FlexKomSigName" SG_ 1002 VC_WHL_BASE "VehCfg3_Pkt";
BA_ "FlexKomComment" SG_ 1002 VC_WHL_BASE "Vehicle Configuration 3 Packet";
BA_ "FlexKomIsMotorola" SG_ 1002 VC_WHL_BASE 1;
BA_ "GenSigSNA" SG_ 1002 VC_WHL_BASE "3h";
BA_ "GenSigSendType" SG_ 1002 VC_FOBIKsafeENBL 5;
BA_ "GenSigCycleTime" SG_ 1002 VC_FOBIKsafeENBL 2000;
BA_ "FlexKomSigStartValue" SG_ 1002 VC_FOBIKsafeENBL "0370FF037FFF0000h";
BA_ "GenSigStartValue" SG_ 1002 VC_FOBIKsafeENBL 1;
BA_ "FlexKomSID" SG_ 1002 VC_FOBIKsafeENBL 888;
BA_ "FlexKomSigStartPos" SG_ 1002 VC_FOBIKsafeENBL 7;
BA_ "FlexKomSigLaenge" SG_ 1002 VC_FOBIKsafeENBL 64;
BA_ "FlexKomSigName" SG_ 1002 VC_FOBIKsafeENBL "VehCfg3_Pkt";
BA_ "FlexKomComment" SG_ 1002 VC_FOBIKsafeENBL "Vehicle Configuration 3 Packet";
BA_ "FlexKomIsMotorola" SG_ 1002 VC_FOBIKsafeENBL 1;
BA_ "GenSigSNA" SG_ 1002 VC_FOBIKsafeENBL "1h";
BA_ "GenSigSendType" SG_ 1002 VC_ELV_Prsnt 5;
BA_ "GenSigCycleTime" SG_ 1002 VC_ELV_Prsnt 2000;
BA_ "FlexKomSigStartValue" SG_ 1002 VC_ELV_Prsnt "0370FF037FFF0000h";
BA_ "FlexKomSID" SG_ 1002 VC_ELV_Prsnt 888;
BA_ "FlexKomSigStartPos" SG_ 1002 VC_ELV_Prsnt 7;
BA_ "FlexKomSigLaenge" SG_ 1002 VC_ELV_Prsnt 64;
BA_ "FlexKomSigName" SG_ 1002 VC_ELV_Prsnt "VehCfg3_Pkt";
BA_ "FlexKomComment" SG_ 1002 VC_ELV_Prsnt "Vehicle Configuration 3 Packet";
BA_ "FlexKomIsMotorola" SG_ 1002 VC_ELV_Prsnt 1;
BA_ "GenSigSNA" SG_ 1002 VC_ELV_Prsnt "0h";
BA_ "GenSigSendType" SG_ 1002 VC_FUEL_CAP 5;
BA_ "GenSigCycleTime" SG_ 1002 VC_FUEL_CAP 2000;
BA_ "FlexKomSigStartValue" SG_ 1002 VC_FUEL_CAP "0370FF037FFF0000h";
BA_ "GenSigStartValue" SG_ 1002 VC_FUEL_CAP 255;
BA_ "GenSigTimeout_IC" SG_ 1002 VC_FUEL_CAP 21000;
BA_ "FlexKomSID" SG_ 1002 VC_FUEL_CAP 888;
BA_ "FlexKomSigStartPos" SG_ 1002 VC_FUEL_CAP 7;
BA_ "FlexKomSigLaenge" SG_ 1002 VC_FUEL_CAP 64;
BA_ "FlexKomSigName" SG_ 1002 VC_FUEL_CAP "VehCfg3_Pkt";
BA_ "FlexKomComment" SG_ 1002 VC_FUEL_CAP "Vehicle Configuration 3 Packet";
BA_ "FlexKomIsMotorola" SG_ 1002 VC_FUEL_CAP 1;
BA_ "GenSigSNA" SG_ 1002 VC_FUEL_CAP "FFh";
BA_ "GenSigSendType" SG_ 1002 VC_WIN_EXPR_FEAT 5;
BA_ "GenSigCycleTime" SG_ 1002 VC_WIN_EXPR_FEAT 2000;
BA_ "FlexKomSigStartValue" SG_ 1002 VC_WIN_EXPR_FEAT "0370FF037FFF0000h";
BA_ "GenSigStartValue" SG_ 1002 VC_WIN_EXPR_FEAT 3;
BA_ "FlexKomSID" SG_ 1002 VC_WIN_EXPR_FEAT 888;
BA_ "FlexKomSigStartPos" SG_ 1002 VC_WIN_EXPR_FEAT 7;
BA_ "FlexKomSigLaenge" SG_ 1002 VC_WIN_EXPR_FEAT 64;
BA_ "FlexKomSigName" SG_ 1002 VC_WIN_EXPR_FEAT "VehCfg3_Pkt";
BA_ "FlexKomComment" SG_ 1002 VC_WIN_EXPR_FEAT "Vehicle Configuration 3 Packet";
BA_ "FlexKomIsMotorola" SG_ 1002 VC_WIN_EXPR_FEAT 1;
BA_ "GenSigSNA" SG_ 1002 VC_WIN_EXPR_FEAT "3h";
BA_ "GenSigSendType" SG_ 1002 VC_ADJ_PDL_PRSNT 5;
BA_ "GenSigCycleTime" SG_ 1002 VC_ADJ_PDL_PRSNT 2000;
BA_ "FlexKomSigStartValue" SG_ 1002 VC_ADJ_PDL_PRSNT "0370FF037FFF0000h";
BA_ "FlexKomSID" SG_ 1002 VC_ADJ_PDL_PRSNT 888;
BA_ "FlexKomSigStartPos" SG_ 1002 VC_ADJ_PDL_PRSNT 7;
BA_ "FlexKomSigLaenge" SG_ 1002 VC_ADJ_PDL_PRSNT 64;
BA_ "FlexKomSigName" SG_ 1002 VC_ADJ_PDL_PRSNT "VehCfg3_Pkt";
BA_ "FlexKomComment" SG_ 1002 VC_ADJ_PDL_PRSNT "Vehicle Configuration 3 Packet";
BA_ "FlexKomIsMotorola" SG_ 1002 VC_ADJ_PDL_PRSNT 1;
BA_ "GenSigSNA" SG_ 1002 VC_ADJ_PDL_PRSNT "0h";
BA_ "GenSigSendType" SG_ 1002 VC_AUTO_HL 5;
BA_ "GenSigCycleTime" SG_ 1002 VC_AUTO_HL 2000;
BA_ "FlexKomSigStartValue" SG_ 1002 VC_AUTO_HL "0370FF037FFF0000h";
BA_ "GenSigTimeout_IC" SG_ 1002 VC_AUTO_HL 21000;
BA_ "FlexKomSID" SG_ 1002 VC_AUTO_HL 888;
BA_ "FlexKomSigStartPos" SG_ 1002 VC_AUTO_HL 7;
BA_ "FlexKomSigLaenge" SG_ 1002 VC_AUTO_HL 64;
BA_ "FlexKomSigName" SG_ 1002 VC_AUTO_HL "VehCfg3_Pkt";
BA_ "FlexKomComment" SG_ 1002 VC_AUTO_HL "Vehicle Configuration 3 Packet";
BA_ "FlexKomIsMotorola" SG_ 1002 VC_AUTO_HL 1;
BA_ "GenSigSNA" SG_ 1002 VC_AUTO_HL "0h";
BA_ "GenSigSendType" SG_ 1002 VC_DrAlrPrsnt 5;
BA_ "GenSigCycleTime" SG_ 1002 VC_DrAlrPrsnt 2000;
BA_ "FlexKomSigStartValue" SG_ 1002 VC_DrAlrPrsnt "0370FF037FFF0000h";
BA_ "GenSigTimeout_IC" SG_ 1002 VC_DrAlrPrsnt 21000;
BA_ "FlexKomSID" SG_ 1002 VC_DrAlrPrsnt 888;
BA_ "FlexKomSigStartPos" SG_ 1002 VC_DrAlrPrsnt 7;
BA_ "FlexKomSigLaenge" SG_ 1002 VC_DrAlrPrsnt 64;
BA_ "FlexKomSigName" SG_ 1002 VC_DrAlrPrsnt "VehCfg3_Pkt";
BA_ "FlexKomComment" SG_ 1002 VC_DrAlrPrsnt "Vehicle Configuration 3 Packet";
BA_ "FlexKomIsMotorola" SG_ 1002 VC_DrAlrPrsnt 1;
BA_ "GenSigSNA" SG_ 1002 VC_DrAlrPrsnt "0h";
BA_ "GenSigSendType" SG_ 1002 VC_DualFuelSens 5;
BA_ "GenSigCycleTime" SG_ 1002 VC_DualFuelSens 2000;
BA_ "FlexKomSigStartValue" SG_ 1002 VC_DualFuelSens "0370FF037FFF0000h";
BA_ "GenSigTimeout_IC" SG_ 1002 VC_DualFuelSens 21000;
BA_ "FlexKomSID" SG_ 1002 VC_DualFuelSens 888;
BA_ "FlexKomSigStartPos" SG_ 1002 VC_DualFuelSens 7;
BA_ "FlexKomSigLaenge" SG_ 1002 VC_DualFuelSens 64;
BA_ "FlexKomSigName" SG_ 1002 VC_DualFuelSens "VehCfg3_Pkt";
BA_ "FlexKomComment" SG_ 1002 VC_DualFuelSens "Vehicle Configuration 3 Packet";
BA_ "FlexKomIsMotorola" SG_ 1002 VC_DualFuelSens 1;
BA_ "GenSigSNA" SG_ 1002 VC_DualFuelSens "0h";
BA_ "GenSigSendType" SG_ 1002 VC_SRT_PRSNT 5;
BA_ "GenSigCycleTime" SG_ 1002 VC_SRT_PRSNT 2000;
BA_ "FlexKomSigStartValue" SG_ 1002 VC_SRT_PRSNT "0370FF037FFF0000h";
BA_ "GenSigTimeout_IC" SG_ 1002 VC_SRT_PRSNT 21000;
BA_ "GenSigTimeout_TPM" SG_ 1002 VC_SRT_PRSNT 21000;
BA_ "GenSigTimeout_ORC" SG_ 1002 VC_SRT_PRSNT 7000;
BA_ "FlexKomSID" SG_ 1002 VC_SRT_PRSNT 888;
BA_ "FlexKomSigStartPos" SG_ 1002 VC_SRT_PRSNT 7;
BA_ "FlexKomSigLaenge" SG_ 1002 VC_SRT_PRSNT 64;
BA_ "FlexKomSigName" SG_ 1002 VC_SRT_PRSNT "VehCfg3_Pkt";
BA_ "FlexKomComment" SG_ 1002 VC_SRT_PRSNT "Vehicle Configuration 3 Packet";
BA_ "FlexKomIsMotorola" SG_ 1002 VC_SRT_PRSNT 1;
BA_ "GenSigSNA" SG_ 1002 VC_SRT_PRSNT "0h";
BA_ "GenSigSendType" SG_ 1002 VC_DSBL_CLK_DISP 5;
BA_ "GenSigCycleTime" SG_ 1002 VC_DSBL_CLK_DISP 2000;
BA_ "FlexKomSigStartValue" SG_ 1002 VC_DSBL_CLK_DISP "0370FF037FFF0000h";
BA_ "GenSigTimeout_IC" SG_ 1002 VC_DSBL_CLK_DISP 21000;
BA_ "FlexKomSID" SG_ 1002 VC_DSBL_CLK_DISP 888;
BA_ "FlexKomSigStartPos" SG_ 1002 VC_DSBL_CLK_DISP 7;
BA_ "FlexKomSigLaenge" SG_ 1002 VC_DSBL_CLK_DISP 64;
BA_ "FlexKomSigName" SG_ 1002 VC_DSBL_CLK_DISP "VehCfg3_Pkt";
BA_ "FlexKomComment" SG_ 1002 VC_DSBL_CLK_DISP "Vehicle Configuration 3 Packet";
BA_ "FlexKomIsMotorola" SG_ 1002 VC_DSBL_CLK_DISP 1;
BA_ "GenSigSNA" SG_ 1002 VC_DSBL_CLK_DISP "0h";
BA_ "GenSigSendType" SG_ 1002 VC_ChassisType 5;
BA_ "GenSigCycleTime" SG_ 1002 VC_ChassisType 2000;
BA_ "FlexKomSigStartValue" SG_ 1002 VC_ChassisType "0370FF037FFF0000h";
BA_ "GenSigStartValue" SG_ 1002 VC_ChassisType 127;
BA_ "GenSigTimeout_PTS" SG_ 1002 VC_ChassisType 21000;
BA_ "GenSigTimeout_EPS" SG_ 1002 VC_ChassisType 21000;
BA_ "GenSigTimeout_ORC" SG_ 1002 VC_ChassisType 7000;
BA_ "FlexKomSID" SG_ 1002 VC_ChassisType 888;
BA_ "FlexKomSigStartPos" SG_ 1002 VC_ChassisType 7;
BA_ "FlexKomSigLaenge" SG_ 1002 VC_ChassisType 64;
BA_ "FlexKomSigName" SG_ 1002 VC_ChassisType "VehCfg3_Pkt";
BA_ "FlexKomComment" SG_ 1002 VC_ChassisType "Vehicle Configuration 3 Packet";
BA_ "FlexKomIsMotorola" SG_ 1002 VC_ChassisType 1;
BA_ "GenSigSNA" SG_ 1002 VC_ChassisType "7Fh";
BA_ "GenSigSendType" SG_ 1002 VC_TEMP_DISP 5;
BA_ "GenSigCycleTime" SG_ 1002 VC_TEMP_DISP 2000;
BA_ "FlexKomSigStartValue" SG_ 1002 VC_TEMP_DISP "0370FF037FFF0000h";
BA_ "GenSigTimeout_IC" SG_ 1002 VC_TEMP_DISP 21000;
BA_ "FlexKomSID" SG_ 1002 VC_TEMP_DISP 888;
BA_ "FlexKomSigStartPos" SG_ 1002 VC_TEMP_DISP 7;
BA_ "FlexKomSigLaenge" SG_ 1002 VC_TEMP_DISP 64;
BA_ "FlexKomSigName" SG_ 1002 VC_TEMP_DISP "VehCfg3_Pkt";
BA_ "FlexKomComment" SG_ 1002 VC_TEMP_DISP "Vehicle Configuration 3 Packet";
BA_ "FlexKomIsMotorola" SG_ 1002 VC_TEMP_DISP 1;
BA_ "GenSigSNA" SG_ 1002 VC_TEMP_DISP "0h";
BA_ "GenSigSendType" SG_ 1002 VC_HVAC_Config 5;
BA_ "GenSigCycleTime" SG_ 1002 VC_HVAC_Config 2000;
BA_ "FlexKomSigStartValue" SG_ 1002 VC_HVAC_Config "0370FF037FFF0000h";
BA_ "GenSigStartValue" SG_ 1002 VC_HVAC_Config 15;
BA_ "FlexKomSID" SG_ 1002 VC_HVAC_Config 888;
BA_ "FlexKomSigStartPos" SG_ 1002 VC_HVAC_Config 7;
BA_ "FlexKomSigLaenge" SG_ 1002 VC_HVAC_Config 64;
BA_ "FlexKomSigName" SG_ 1002 VC_HVAC_Config "VehCfg3_Pkt";
BA_ "FlexKomComment" SG_ 1002 VC_HVAC_Config "Vehicle Configuration 3 Packet";
BA_ "FlexKomIsMotorola" SG_ 1002 VC_HVAC_Config 1;
BA_ "GenSigSNA" SG_ 1002 VC_HVAC_Config "Fh";
BA_ "GenSigSendType" SG_ 1002 VC_VEH_BRAND 5;
BA_ "GenSigCycleTime" SG_ 1002 VC_VEH_BRAND 2000;
BA_ "FlexKomSigStartValue" SG_ 1002 VC_VEH_BRAND "0370FF037FFF0000h";
BA_ "GenSigStartValue" SG_ 1002 VC_VEH_BRAND 15;
BA_ "GenSigTimeout_IC" SG_ 1002 VC_VEH_BRAND 21000;
BA_ "GenSigTimeout_TPM" SG_ 1002 VC_VEH_BRAND 21000;
BA_ "FlexKomSID" SG_ 1002 VC_VEH_BRAND 888;
BA_ "FlexKomSigStartPos" SG_ 1002 VC_VEH_BRAND 7;
BA_ "FlexKomSigLaenge" SG_ 1002 VC_VEH_BRAND 64;
BA_ "FlexKomSigName" SG_ 1002 VC_VEH_BRAND "VehCfg3_Pkt";
BA_ "FlexKomComment" SG_ 1002 VC_VEH_BRAND "Vehicle Configuration 3 Packet";
BA_ "FlexKomIsMotorola" SG_ 1002 VC_VEH_BRAND 1;
BA_ "GenSigSNA" SG_ 1002 VC_VEH_BRAND "Fh";
BA_ "GenSigSendType" SG_ 1002 VC_CMP_DISP 5;
BA_ "GenSigCycleTime" SG_ 1002 VC_CMP_DISP 2000;
BA_ "FlexKomSigStartValue" SG_ 1002 VC_CMP_DISP "0370FF037FFF0000h";
BA_ "GenSigTimeout_IC" SG_ 1002 VC_CMP_DISP 21000;
BA_ "FlexKomSID" SG_ 1002 VC_CMP_DISP 888;
BA_ "FlexKomSigStartPos" SG_ 1002 VC_CMP_DISP 7;
BA_ "FlexKomSigLaenge" SG_ 1002 VC_CMP_DISP 64;
BA_ "FlexKomSigName" SG_ 1002 VC_CMP_DISP "VehCfg3_Pkt";
BA_ "FlexKomComment" SG_ 1002 VC_CMP_DISP "Vehicle Configuration 3 Packet";
BA_ "FlexKomIsMotorola" SG_ 1002 VC_CMP_DISP 1;
BA_ "GenSigSNA" SG_ 1002 VC_CMP_DISP "0h";
BA_ "GenSigSendType" SG_ 1002 VC_IntEC_MIRR 5;
BA_ "GenSigCycleTime" SG_ 1002 VC_IntEC_MIRR 2000;
BA_ "FlexKomSigStartValue" SG_ 1002 VC_IntEC_MIRR "0370FF037FFF0000h";
BA_ "FlexKomSID" SG_ 1002 VC_IntEC_MIRR 888;
BA_ "FlexKomSigStartPos" SG_ 1002 VC_IntEC_MIRR 7;
BA_ "FlexKomSigLaenge" SG_ 1002 VC_IntEC_MIRR 64;
BA_ "FlexKomSigName" SG_ 1002 VC_IntEC_MIRR "VehCfg3_Pkt";
BA_ "FlexKomComment" SG_ 1002 VC_IntEC_MIRR "Vehicle Configuration 3 Packet";
BA_ "FlexKomIsMotorola" SG_ 1002 VC_IntEC_MIRR 1;
BA_ "GenSigSNA" SG_ 1002 VC_IntEC_MIRR "0h";
BA_ "GenSigSendType" SG_ 1002 VC_ESCL_PRSNT 5;
BA_ "GenSigCycleTime" SG_ 1002 VC_ESCL_PRSNT 2000;
BA_ "FlexKomSigStartValue" SG_ 1002 VC_ESCL_PRSNT "0370FF037FFF0000h";
BA_ "FlexKomSID" SG_ 1002 VC_ESCL_PRSNT 888;
BA_ "FlexKomSigStartPos" SG_ 1002 VC_ESCL_PRSNT 7;
BA_ "FlexKomSigLaenge" SG_ 1002 VC_ESCL_PRSNT 64;
BA_ "FlexKomSigName" SG_ 1002 VC_ESCL_PRSNT "VehCfg3_Pkt";
BA_ "FlexKomComment" SG_ 1002 VC_ESCL_PRSNT "Vehicle Configuration 3 Packet";
BA_ "FlexKomIsMotorola" SG_ 1002 VC_ESCL_PRSNT 1;
BA_ "GenSigSNA" SG_ 1002 VC_ESCL_PRSNT "0h";
BA_ "GenSigSendType" SG_ 1002 VC_HID_HL 5;
BA_ "GenSigCycleTime" SG_ 1002 VC_HID_HL 2000;
BA_ "FlexKomSigStartValue" SG_ 1002 VC_HID_HL "0370FF037FFF0000h";
BA_ "FlexKomSID" SG_ 1002 VC_HID_HL 888;
BA_ "FlexKomSigStartPos" SG_ 1002 VC_HID_HL 7;
BA_ "FlexKomSigLaenge" SG_ 1002 VC_HID_HL 64;
BA_ "FlexKomSigName" SG_ 1002 VC_HID_HL "VehCfg3_Pkt";
BA_ "FlexKomComment" SG_ 1002 VC_HID_HL "Vehicle Configuration 3 Packet";
BA_ "FlexKomIsMotorola" SG_ 1002 VC_HID_HL 1;
BA_ "GenSigSNA" SG_ 1002 VC_HID_HL "0h";
BA_ "GenSigSendType" SG_ 1002 VC_SecLkPrsnt 5;
BA_ "GenSigCycleTime" SG_ 1002 VC_SecLkPrsnt 2000;
BA_ "FlexKomSigStartValue" SG_ 1002 VC_SecLkPrsnt "0370FF037FFF0000h";
BA_ "FlexKomSID" SG_ 1002 VC_SecLkPrsnt 888;
BA_ "FlexKomSigStartPos" SG_ 1002 VC_SecLkPrsnt 7;
BA_ "FlexKomSigLaenge" SG_ 1002 VC_SecLkPrsnt 64;
BA_ "FlexKomSigName" SG_ 1002 VC_SecLkPrsnt "VehCfg3_Pkt";
BA_ "FlexKomComment" SG_ 1002 VC_SecLkPrsnt "Vehicle Configuration 3 Packet";
BA_ "FlexKomIsMotorola" SG_ 1002 VC_SecLkPrsnt 1;
BA_ "GenSigSNA" SG_ 1002 VC_SecLkPrsnt "0h";
BA_ "GenSigSendType" SG_ 1002 VC_Liftgate_Trunk 5;
BA_ "GenSigCycleTime" SG_ 1002 VC_Liftgate_Trunk 2000;
BA_ "FlexKomSigStartValue" SG_ 1002 VC_Liftgate_Trunk "0370FF037FFF0000h";
BA_ "GenSigTimeout_IC" SG_ 1002 VC_Liftgate_Trunk 21000;
BA_ "FlexKomSID" SG_ 1002 VC_Liftgate_Trunk 888;
BA_ "FlexKomSigStartPos" SG_ 1002 VC_Liftgate_Trunk 7;
BA_ "FlexKomSigLaenge" SG_ 1002 VC_Liftgate_Trunk 64;
BA_ "FlexKomSigName" SG_ 1002 VC_Liftgate_Trunk "VehCfg3_Pkt";
BA_ "FlexKomComment" SG_ 1002 VC_Liftgate_Trunk "Vehicle Configuration 3 Packet";
BA_ "FlexKomIsMotorola" SG_ 1002 VC_Liftgate_Trunk 1;
BA_ "GenSigSNA" SG_ 1002 VC_Liftgate_Trunk "3h";
BA_ "GenSigSendType" SG_ 1002 VC_CMS 5;
BA_ "GenSigCycleTime" SG_ 1002 VC_CMS 2000;
BA_ "FlexKomSigStartValue" SG_ 1002 VC_CMS "0370FF037FFF0000h";
BA_ "FlexKomSID" SG_ 1002 VC_CMS 888;
BA_ "FlexKomSigStartPos" SG_ 1002 VC_CMS 7;
BA_ "FlexKomSigLaenge" SG_ 1002 VC_CMS 64;
BA_ "FlexKomSigName" SG_ 1002 VC_CMS "VehCfg3_Pkt";
BA_ "FlexKomComment" SG_ 1002 VC_CMS "Vehicle Configuration 3 Packet";
BA_ "FlexKomIsMotorola" SG_ 1002 VC_CMS 1;
BA_ "GenSigSNA" SG_ 1002 VC_CMS "0h";
BA_ "GenSigSendType" SG_ 1002 VC_FCW 5;
BA_ "GenSigCycleTime" SG_ 1002 VC_FCW 2000;
BA_ "FlexKomSigStartValue" SG_ 1002 VC_FCW "0370FF037FFF0000h";
BA_ "FlexKomSID" SG_ 1002 VC_FCW 888;
BA_ "FlexKomSigStartPos" SG_ 1002 VC_FCW 7;
BA_ "FlexKomSigLaenge" SG_ 1002 VC_FCW 64;
BA_ "FlexKomSigName" SG_ 1002 VC_FCW "VehCfg3_Pkt";
BA_ "FlexKomComment" SG_ 1002 VC_FCW "Vehicle Configuration 3 Packet";
BA_ "FlexKomIsMotorola" SG_ 1002 VC_FCW 1;
BA_ "GenSigSNA" SG_ 1002 VC_FCW "0h";
BA_ "GenSigSendType" SG_ 1002 VC_Base_TPM 5;
BA_ "GenSigCycleTime" SG_ 1002 VC_Base_TPM 2000;
BA_ "FlexKomSigStartValue" SG_ 1002 VC_Base_TPM "0370FF037FFF0000h";
BA_ "GenSigTimeout_IC" SG_ 1002 VC_Base_TPM 21000;
BA_ "GenSigTimeout_TPM" SG_ 1002 VC_Base_TPM 21000;
BA_ "FlexKomSID" SG_ 1002 VC_Base_TPM 888;
BA_ "FlexKomSigStartPos" SG_ 1002 VC_Base_TPM 7;
BA_ "FlexKomSigLaenge" SG_ 1002 VC_Base_TPM 64;
BA_ "FlexKomSigName" SG_ 1002 VC_Base_TPM "VehCfg3_Pkt";
BA_ "FlexKomComment" SG_ 1002 VC_Base_TPM "Vehicle Configuration 3 Packet";
BA_ "FlexKomIsMotorola" SG_ 1002 VC_Base_TPM 1;
BA_ "GenSigSNA" SG_ 1002 VC_Base_TPM "0h";
BA_ "GenSigSendType" SG_ 1002 VC_Prem_TPM 5;
BA_ "GenSigCycleTime" SG_ 1002 VC_Prem_TPM 2000;
BA_ "FlexKomSigStartValue" SG_ 1002 VC_Prem_TPM "0370FF037FFF0000h";
BA_ "GenSigTimeout_IC" SG_ 1002 VC_Prem_TPM 21000;
BA_ "GenSigTimeout_TPM" SG_ 1002 VC_Prem_TPM 21000;
BA_ "FlexKomSID" SG_ 1002 VC_Prem_TPM 888;
BA_ "FlexKomSigStartPos" SG_ 1002 VC_Prem_TPM 7;
BA_ "FlexKomSigLaenge" SG_ 1002 VC_Prem_TPM 64;
BA_ "FlexKomSigName" SG_ 1002 VC_Prem_TPM "VehCfg3_Pkt";
BA_ "FlexKomComment" SG_ 1002 VC_Prem_TPM "Vehicle Configuration 3 Packet";
BA_ "FlexKomIsMotorola" SG_ 1002 VC_Prem_TPM 1;
BA_ "GenSigSNA" SG_ 1002 VC_Prem_TPM "0h";
BA_ "GenSigSendType" SG_ 1002 VC_PDDL_PRSNT 5;
BA_ "GenSigCycleTime" SG_ 1002 VC_PDDL_PRSNT 2000;
BA_ "FlexKomSigStartValue" SG_ 1002 VC_PDDL_PRSNT "0370FF037FFF0000h";
BA_ "GenSigTimeout_IC" SG_ 1002 VC_PDDL_PRSNT 21000;
BA_ "FlexKomSID" SG_ 1002 VC_PDDL_PRSNT 888;
BA_ "FlexKomSigStartPos" SG_ 1002 VC_PDDL_PRSNT 7;
BA_ "FlexKomSigLaenge" SG_ 1002 VC_PDDL_PRSNT 64;
BA_ "FlexKomSigName" SG_ 1002 VC_PDDL_PRSNT "VehCfg3_Pkt";
BA_ "FlexKomComment" SG_ 1002 VC_PDDL_PRSNT "Vehicle Configuration 3 Packet";
BA_ "FlexKomIsMotorola" SG_ 1002 VC_PDDL_PRSNT 1;
BA_ "GenSigSNA" SG_ 1002 VC_PDDL_PRSNT "0h";
BA_ "GenSigSendType" SG_ 1002 VC_SPORT_PRSNT 5;
BA_ "GenSigCycleTime" SG_ 1002 VC_SPORT_PRSNT 2000;
BA_ "FlexKomSigStartValue" SG_ 1002 VC_SPORT_PRSNT "0370FF037FFF0000h";
BA_ "GenSigTimeout_IC" SG_ 1002 VC_SPORT_PRSNT 21000;
BA_ "FlexKomSID" SG_ 1002 VC_SPORT_PRSNT 888;
BA_ "FlexKomSigStartPos" SG_ 1002 VC_SPORT_PRSNT 7;
BA_ "FlexKomSigLaenge" SG_ 1002 VC_SPORT_PRSNT 64;
BA_ "FlexKomSigName" SG_ 1002 VC_SPORT_PRSNT "VehCfg3_Pkt";
BA_ "FlexKomComment" SG_ 1002 VC_SPORT_PRSNT "Vehicle Configuration 3 Packet";
BA_ "FlexKomIsMotorola" SG_ 1002 VC_SPORT_PRSNT 1;
BA_ "GenSigSNA" SG_ 1002 VC_SPORT_PRSNT "0h";
BA_ "GenSigSendType" SG_ 1002 VC_AutoParkPrsnt 5;
BA_ "GenSigCycleTime" SG_ 1002 VC_AutoParkPrsnt 2000;
BA_ "FlexKomSigStartValue" SG_ 1002 VC_AutoParkPrsnt "0370FF037FFF0000h";
BA_ "GenSigTimeout_IC" SG_ 1002 VC_AutoParkPrsnt 21000;
BA_ "FlexKomSID" SG_ 1002 VC_AutoParkPrsnt 888;
BA_ "FlexKomSigStartPos" SG_ 1002 VC_AutoParkPrsnt 7;
BA_ "FlexKomSigLaenge" SG_ 1002 VC_AutoParkPrsnt 64;
BA_ "FlexKomSigName" SG_ 1002 VC_AutoParkPrsnt "VehCfg3_Pkt";
BA_ "FlexKomComment" SG_ 1002 VC_AutoParkPrsnt "Vehicle Configuration 3 Packet";
BA_ "FlexKomIsMotorola" SG_ 1002 VC_AutoParkPrsnt 1;
BA_ "GenSigSNA" SG_ 1002 VC_AutoParkPrsnt "0h";
BA_ "GenSigSendType" SG_ 1002 VC_PE_Prsnt 5;
BA_ "GenSigCycleTime" SG_ 1002 VC_PE_Prsnt 2000;
BA_ "FlexKomSigStartValue" SG_ 1002 VC_PE_Prsnt "0370FF037FFF0000h";
BA_ "GenSigTimeout_IC" SG_ 1002 VC_PE_Prsnt 21000;
BA_ "FlexKomSID" SG_ 1002 VC_PE_Prsnt 888;
BA_ "FlexKomSigStartPos" SG_ 1002 VC_PE_Prsnt 7;
BA_ "FlexKomSigLaenge" SG_ 1002 VC_PE_Prsnt 64;
BA_ "FlexKomSigName" SG_ 1002 VC_PE_Prsnt "VehCfg3_Pkt";
BA_ "FlexKomComment" SG_ 1002 VC_PE_Prsnt "Vehicle Configuration 3 Packet";
BA_ "FlexKomIsMotorola" SG_ 1002 VC_PE_Prsnt 1;
BA_ "GenSigSNA" SG_ 1002 VC_PE_Prsnt "0h";
BA_ "GenSigSendType" SG_ 1002 VC_KG_Prsnt 5;
BA_ "GenSigCycleTime" SG_ 1002 VC_KG_Prsnt 2000;
BA_ "FlexKomSigStartValue" SG_ 1002 VC_KG_Prsnt "0370FF037FFF0000h";
BA_ "GenSigTimeout_IC" SG_ 1002 VC_KG_Prsnt 21000;
BA_ "FlexKomSID" SG_ 1002 VC_KG_Prsnt 888;
BA_ "FlexKomSigStartPos" SG_ 1002 VC_KG_Prsnt 7;
BA_ "FlexKomSigLaenge" SG_ 1002 VC_KG_Prsnt 64;
BA_ "FlexKomSigName" SG_ 1002 VC_KG_Prsnt "VehCfg3_Pkt";
BA_ "FlexKomComment" SG_ 1002 VC_KG_Prsnt "Vehicle Configuration 3 Packet";
BA_ "FlexKomIsMotorola" SG_ 1002 VC_KG_Prsnt 1;
BA_ "GenSigSNA" SG_ 1002 VC_KG_Prsnt "0h";
BA_ "GenSigSendType" SG_ 1003 VC_TCASE_HI_RATIO 5;
BA_ "GenSigCycleTime" SG_ 1003 VC_TCASE_HI_RATIO 1000;
BA_ "FlexKomSigStartValue" SG_ 1003 VC_TCASE_HI_RATIO "FFFFFFFFFFFFFFFFh";
BA_ "GenSigStartValue" SG_ 1003 VC_TCASE_HI_RATIO 16383;
BA_ "FlexKomSID" SG_ 1003 VC_TCASE_HI_RATIO 1035;
BA_ "FlexKomSigStartPos" SG_ 1003 VC_TCASE_HI_RATIO 7;
BA_ "FlexKomSigLaenge" SG_ 1003 VC_TCASE_HI_RATIO 64;
BA_ "FlexKomSigName" SG_ 1003 VC_TCASE_HI_RATIO "VehCfg4_Pkt";
BA_ "FlexKomComment" SG_ 1003 VC_TCASE_HI_RATIO "Vehicle Configuration 4 Packet";
BA_ "FlexKomIsMotorola" SG_ 1003 VC_TCASE_HI_RATIO 1;
BA_ "GenSigSNA" SG_ 1003 VC_TCASE_HI_RATIO "3FFFh";
BA_ "GenSigSendType" SG_ 1003 VC_VehCfg4_Stat 5;
BA_ "GenSigCycleTime" SG_ 1003 VC_VehCfg4_Stat 1000;
BA_ "FlexKomSigStartValue" SG_ 1003 VC_VehCfg4_Stat "FFFFFFFFFFFFFFFFh";
BA_ "GenSigStartValue" SG_ 1003 VC_VehCfg4_Stat 3;
BA_ "GenSigTimeout_RF_HUB" SG_ 1003 VC_VehCfg4_Stat 10500;
BA_ "GenSigTimeout_ORC" SG_ 1003 VC_VehCfg4_Stat 3500;
BA_ "FlexKomSID" SG_ 1003 VC_VehCfg4_Stat 1035;
BA_ "FlexKomSigStartPos" SG_ 1003 VC_VehCfg4_Stat 7;
BA_ "FlexKomSigLaenge" SG_ 1003 VC_VehCfg4_Stat 64;
BA_ "FlexKomSigName" SG_ 1003 VC_VehCfg4_Stat "VehCfg4_Pkt";
BA_ "FlexKomComment" SG_ 1003 VC_VehCfg4_Stat "Vehicle Configuration 4 Packet";
BA_ "FlexKomIsMotorola" SG_ 1003 VC_VehCfg4_Stat 1;
BA_ "GenSigSNA" SG_ 1003 VC_VehCfg4_Stat "3h";
BA_ "GenSigSendType" SG_ 1003 VC_AXLE_RATIO 5;
BA_ "GenSigCycleTime" SG_ 1003 VC_AXLE_RATIO 1000;
BA_ "FlexKomSigStartValue" SG_ 1003 VC_AXLE_RATIO "FFFFFFFFFFFFFFFFh";
BA_ "GenSigStartValue" SG_ 1003 VC_AXLE_RATIO 65535;
BA_ "FlexKomSID" SG_ 1003 VC_AXLE_RATIO 1035;
BA_ "FlexKomSigStartPos" SG_ 1003 VC_AXLE_RATIO 7;
BA_ "FlexKomSigLaenge" SG_ 1003 VC_AXLE_RATIO 64;
BA_ "FlexKomSigName" SG_ 1003 VC_AXLE_RATIO "VehCfg4_Pkt";
BA_ "FlexKomComment" SG_ 1003 VC_AXLE_RATIO "Vehicle Configuration 4 Packet";
BA_ "FlexKomIsMotorola" SG_ 1003 VC_AXLE_RATIO 1;
BA_ "GenSigSNA" SG_ 1003 VC_AXLE_RATIO "FFFFh";
BA_ "GenSigSendType" SG_ 1003 VC_TCASE_LO_RATIO 5;
BA_ "GenSigCycleTime" SG_ 1003 VC_TCASE_LO_RATIO 1000;
BA_ "FlexKomSigStartValue" SG_ 1003 VC_TCASE_LO_RATIO "FFFFFFFFFFFFFFFFh";
BA_ "GenSigStartValue" SG_ 1003 VC_TCASE_LO_RATIO 65535;
BA_ "FlexKomSID" SG_ 1003 VC_TCASE_LO_RATIO 1035;
BA_ "FlexKomSigStartPos" SG_ 1003 VC_TCASE_LO_RATIO 7;
BA_ "FlexKomSigLaenge" SG_ 1003 VC_TCASE_LO_RATIO 64;
BA_ "FlexKomSigName" SG_ 1003 VC_TCASE_LO_RATIO "VehCfg4_Pkt";
BA_ "FlexKomComment" SG_ 1003 VC_TCASE_LO_RATIO "Vehicle Configuration 4 Packet";
BA_ "FlexKomIsMotorola" SG_ 1003 VC_TCASE_LO_RATIO 1;
BA_ "GenSigSNA" SG_ 1003 VC_TCASE_LO_RATIO "FFFFh";
BA_ "GenSigSendType" SG_ 1003 VC_TIRE_CIRCUMF 5;
BA_ "GenSigCycleTime" SG_ 1003 VC_TIRE_CIRCUMF 1000;
BA_ "FlexKomSigStartValue" SG_ 1003 VC_TIRE_CIRCUMF "FFFFFFFFFFFFFFFFh";
BA_ "GenSigStartValue" SG_ 1003 VC_TIRE_CIRCUMF 65535;
BA_ "GenSigTimeout_ORC" SG_ 1003 VC_TIRE_CIRCUMF 3500;
BA_ "FlexKomSID" SG_ 1003 VC_TIRE_CIRCUMF 1035;
BA_ "FlexKomSigStartPos" SG_ 1003 VC_TIRE_CIRCUMF 7;
BA_ "FlexKomSigLaenge" SG_ 1003 VC_TIRE_CIRCUMF 64;
BA_ "FlexKomSigName" SG_ 1003 VC_TIRE_CIRCUMF "VehCfg4_Pkt";
BA_ "FlexKomComment" SG_ 1003 VC_TIRE_CIRCUMF "Vehicle Configuration 4 Packet";
BA_ "FlexKomIsMotorola" SG_ 1003 VC_TIRE_CIRCUMF 1;
BA_ "GenSigSNA" SG_ 1003 VC_TIRE_CIRCUMF "FFFFh";
BA_ "GenSigSendType" SG_ 1004 VC_BU_VehCfg1_Stat 1;
BA_ "FlexKomSigStartValue" SG_ 1004 VC_BU_VehCfg1_Stat "FFFF7FF0FF0FFF00h";
BA_ "GenSigStartValue" SG_ 1004 VC_BU_VehCfg1_Stat 3;
BA_ "FlexKomSID" SG_ 1004 VC_BU_VehCfg1_Stat 919;
BA_ "FlexKomSigStartPos" SG_ 1004 VC_BU_VehCfg1_Stat 7;
BA_ "FlexKomSigLaenge" SG_ 1004 VC_BU_VehCfg1_Stat 64;
BA_ "FlexKomSigName" SG_ 1004 VC_BU_VehCfg1_Stat "VehCfgBU1_Pkt";
BA_ "FlexKomComment" SG_ 1004 VC_BU_VehCfg1_Stat "Backup for Vehicle Configuration 1 Packet";
BA_ "FlexKomIsMotorola" SG_ 1004 VC_BU_VehCfg1_Stat 1;
BA_ "GenSigSNA" SG_ 1004 VC_BU_VehCfg1_Stat "3h";
BA_ "GenSigSendType" SG_ 1004 VC_BU_MODEL_YEAR 1;
BA_ "FlexKomSigStartValue" SG_ 1004 VC_BU_MODEL_YEAR "FFFF7FF0FF0FFF00h";
BA_ "GenSigStartValue" SG_ 1004 VC_BU_MODEL_YEAR 63;
BA_ "FlexKomSID" SG_ 1004 VC_BU_MODEL_YEAR 919;
BA_ "FlexKomSigStartPos" SG_ 1004 VC_BU_MODEL_YEAR 7;
BA_ "FlexKomSigLaenge" SG_ 1004 VC_BU_MODEL_YEAR 64;
BA_ "FlexKomSigName" SG_ 1004 VC_BU_MODEL_YEAR "VehCfgBU1_Pkt";
BA_ "FlexKomComment" SG_ 1004 VC_BU_MODEL_YEAR "Backup for Vehicle Configuration 1 Packet";
BA_ "FlexKomIsMotorola" SG_ 1004 VC_BU_MODEL_YEAR 1;
BA_ "GenSigSNA" SG_ 1004 VC_BU_MODEL_YEAR "3Fh";
BA_ "GenSigSendType" SG_ 1004 VC_BU_VEH_LINE 1;
BA_ "FlexKomSigStartValue" SG_ 1004 VC_BU_VEH_LINE "FFFF7FF0FF0FFF00h";
BA_ "GenSigStartValue" SG_ 1004 VC_BU_VEH_LINE 255;
BA_ "FlexKomSID" SG_ 1004 VC_BU_VEH_LINE 919;
BA_ "FlexKomSigStartPos" SG_ 1004 VC_BU_VEH_LINE 7;
BA_ "FlexKomSigLaenge" SG_ 1004 VC_BU_VEH_LINE 64;
BA_ "FlexKomSigName" SG_ 1004 VC_BU_VEH_LINE "VehCfgBU1_Pkt";
BA_ "FlexKomComment" SG_ 1004 VC_BU_VEH_LINE "Backup for Vehicle Configuration 1 Packet";
BA_ "FlexKomIsMotorola" SG_ 1004 VC_BU_VEH_LINE 1;
BA_ "GenSigSNA" SG_ 1004 VC_BU_VEH_LINE "FFh";
BA_ "GenSigSendType" SG_ 1004 VC_BU_COUNTRY 1;
BA_ "FlexKomSigStartValue" SG_ 1004 VC_BU_COUNTRY "FFFF7FF0FF0FFF00h";
BA_ "GenSigStartValue" SG_ 1004 VC_BU_COUNTRY 31;
BA_ "FlexKomSID" SG_ 1004 VC_BU_COUNTRY 919;
BA_ "FlexKomSigStartPos" SG_ 1004 VC_BU_COUNTRY 7;
BA_ "FlexKomSigLaenge" SG_ 1004 VC_BU_COUNTRY 64;
BA_ "FlexKomSigName" SG_ 1004 VC_BU_COUNTRY "VehCfgBU1_Pkt";
BA_ "FlexKomComment" SG_ 1004 VC_BU_COUNTRY "Backup for Vehicle Configuration 1 Packet";
BA_ "FlexKomIsMotorola" SG_ 1004 VC_BU_COUNTRY 1;
BA_ "GenSigSNA" SG_ 1004 VC_BU_COUNTRY "1Fh";
BA_ "GenSigSendType" SG_ 1004 VC_BU_LHD_RHD 1;
BA_ "FlexKomSigStartValue" SG_ 1004 VC_BU_LHD_RHD "FFFF7FF0FF0FFF00h";
BA_ "GenSigStartValue" SG_ 1004 VC_BU_LHD_RHD 3;
BA_ "FlexKomSID" SG_ 1004 VC_BU_LHD_RHD 919;
BA_ "FlexKomSigStartPos" SG_ 1004 VC_BU_LHD_RHD 7;
BA_ "FlexKomSigLaenge" SG_ 1004 VC_BU_LHD_RHD 64;
BA_ "FlexKomSigName" SG_ 1004 VC_BU_LHD_RHD "VehCfgBU1_Pkt";
BA_ "FlexKomComment" SG_ 1004 VC_BU_LHD_RHD "Backup for Vehicle Configuration 1 Packet";
BA_ "FlexKomIsMotorola" SG_ 1004 VC_BU_LHD_RHD 1;
BA_ "GenSigSNA" SG_ 1004 VC_BU_LHD_RHD "3h";
BA_ "GenSigSendType" SG_ 1004 VC_BU_RemStPrsnt 1;
BA_ "FlexKomSigStartValue" SG_ 1004 VC_BU_RemStPrsnt "FFFF7FF0FF0FFF00h";
BA_ "FlexKomSID" SG_ 1004 VC_BU_RemStPrsnt 919;
BA_ "FlexKomSigStartPos" SG_ 1004 VC_BU_RemStPrsnt 7;
BA_ "FlexKomSigLaenge" SG_ 1004 VC_BU_RemStPrsnt 64;
BA_ "FlexKomSigName" SG_ 1004 VC_BU_RemStPrsnt "VehCfgBU1_Pkt";
BA_ "FlexKomComment" SG_ 1004 VC_BU_RemStPrsnt "Backup for Vehicle Configuration 1 Packet";
BA_ "FlexKomIsMotorola" SG_ 1004 VC_BU_RemStPrsnt 1;
BA_ "GenSigSNA" SG_ 1004 VC_BU_RemStPrsnt "0h";
BA_ "GenSigSendType" SG_ 1004 VC_BU_XWD 1;
BA_ "FlexKomSigStartValue" SG_ 1004 VC_BU_XWD "FFFF7FF0FF0FFF00h";
BA_ "FlexKomSID" SG_ 1004 VC_BU_XWD 919;
BA_ "FlexKomSigStartPos" SG_ 1004 VC_BU_XWD 7;
BA_ "FlexKomSigLaenge" SG_ 1004 VC_BU_XWD 64;
BA_ "FlexKomSigName" SG_ 1004 VC_BU_XWD "VehCfgBU1_Pkt";
BA_ "FlexKomComment" SG_ 1004 VC_BU_XWD "Backup for Vehicle Configuration 1 Packet";
BA_ "FlexKomIsMotorola" SG_ 1004 VC_BU_XWD 1;
BA_ "GenSigSNA" SG_ 1004 VC_BU_XWD "0h";
BA_ "GenSigSendType" SG_ 1004 VC_BU_EmodePrsnt 1;
BA_ "FlexKomSigStartValue" SG_ 1004 VC_BU_EmodePrsnt "FFFF7FF0FF0FFF00h";
BA_ "FlexKomSID" SG_ 1004 VC_BU_EmodePrsnt 919;
BA_ "FlexKomSigStartPos" SG_ 1004 VC_BU_EmodePrsnt 7;
BA_ "FlexKomSigLaenge" SG_ 1004 VC_BU_EmodePrsnt 64;
BA_ "FlexKomSigName" SG_ 1004 VC_BU_EmodePrsnt "VehCfgBU1_Pkt";
BA_ "FlexKomComment" SG_ 1004 VC_BU_EmodePrsnt "Backup for Vehicle Configuration 1 Packet";
BA_ "FlexKomIsMotorola" SG_ 1004 VC_BU_EmodePrsnt 1;
BA_ "GenSigSNA" SG_ 1004 VC_BU_EmodePrsnt "0h";
BA_ "GenSigSendType" SG_ 1004 VC_BU_AUTO_HB 1;
BA_ "FlexKomSigStartValue" SG_ 1004 VC_BU_AUTO_HB "FFFF7FF0FF0FFF00h";
BA_ "FlexKomSID" SG_ 1004 VC_BU_AUTO_HB 919;
BA_ "FlexKomSigStartPos" SG_ 1004 VC_BU_AUTO_HB 7;
BA_ "FlexKomSigLaenge" SG_ 1004 VC_BU_AUTO_HB 64;
BA_ "FlexKomSigName" SG_ 1004 VC_BU_AUTO_HB "VehCfgBU1_Pkt";
BA_ "FlexKomComment" SG_ 1004 VC_BU_AUTO_HB "Backup for Vehicle Configuration 1 Packet";
BA_ "FlexKomIsMotorola" SG_ 1004 VC_BU_AUTO_HB 1;
BA_ "GenSigSNA" SG_ 1004 VC_BU_AUTO_HB "0h";
BA_ "GenSigSendType" SG_ 1004 VC_BU_BODY_STYLE 1;
BA_ "FlexKomSigStartValue" SG_ 1004 VC_BU_BODY_STYLE "FFFF7FF0FF0FFF00h";
BA_ "GenSigStartValue" SG_ 1004 VC_BU_BODY_STYLE 15;
BA_ "FlexKomSID" SG_ 1004 VC_BU_BODY_STYLE 919;
BA_ "FlexKomSigStartPos" SG_ 1004 VC_BU_BODY_STYLE 7;
BA_ "FlexKomSigLaenge" SG_ 1004 VC_BU_BODY_STYLE 64;
BA_ "FlexKomSigName" SG_ 1004 VC_BU_BODY_STYLE "VehCfgBU1_Pkt";
BA_ "FlexKomComment" SG_ 1004 VC_BU_BODY_STYLE "Backup for Vehicle Configuration 1 Packet";
BA_ "FlexKomIsMotorola" SG_ 1004 VC_BU_BODY_STYLE 1;
BA_ "GenSigSNA" SG_ 1004 VC_BU_BODY_STYLE "Fh";
BA_ "GenSigSendType" SG_ 1004 VC_BU_MAX_VEH_SPD 1;
BA_ "FlexKomSigStartValue" SG_ 1004 VC_BU_MAX_VEH_SPD "FFFF7FF0FF0FFF00h";
BA_ "GenSigStartValue" SG_ 1004 VC_BU_MAX_VEH_SPD 255;
BA_ "FlexKomSID" SG_ 1004 VC_BU_MAX_VEH_SPD 919;
BA_ "FlexKomSigStartPos" SG_ 1004 VC_BU_MAX_VEH_SPD 7;
BA_ "FlexKomSigLaenge" SG_ 1004 VC_BU_MAX_VEH_SPD 64;
BA_ "FlexKomSigName" SG_ 1004 VC_BU_MAX_VEH_SPD "VehCfgBU1_Pkt";
BA_ "FlexKomComment" SG_ 1004 VC_BU_MAX_VEH_SPD "Backup for Vehicle Configuration 1 Packet";
BA_ "FlexKomIsMotorola" SG_ 1004 VC_BU_MAX_VEH_SPD 1;
BA_ "GenSigSNA" SG_ 1004 VC_BU_MAX_VEH_SPD "FFh";
BA_ "GenSigSendType" SG_ 1004 VC_BU_ShftrTyp 1;
BA_ "FlexKomSigStartValue" SG_ 1004 VC_BU_ShftrTyp "FFFF7FF0FF0FFF00h";
BA_ "GenSigStartValue" SG_ 1004 VC_BU_ShftrTyp 15;
BA_ "FlexKomSID" SG_ 1004 VC_BU_ShftrTyp 919;
BA_ "FlexKomSigStartPos" SG_ 1004 VC_BU_ShftrTyp 7;
BA_ "FlexKomSigLaenge" SG_ 1004 VC_BU_ShftrTyp 64;
BA_ "FlexKomSigName" SG_ 1004 VC_BU_ShftrTyp "VehCfgBU1_Pkt";
BA_ "FlexKomComment" SG_ 1004 VC_BU_ShftrTyp "Backup for Vehicle Configuration 1 Packet";
BA_ "FlexKomIsMotorola" SG_ 1004 VC_BU_ShftrTyp 1;
BA_ "GenSigSNA" SG_ 1004 VC_BU_ShftrTyp "Fh";
BA_ "GenSigSendType" SG_ 1004 VC_BU_PTS_DispTyp 1;
BA_ "FlexKomSigStartValue" SG_ 1004 VC_BU_PTS_DispTyp "FFFF7FF0FF0FFF00h";
BA_ "FlexKomSID" SG_ 1004 VC_BU_PTS_DispTyp 919;
BA_ "FlexKomSigStartPos" SG_ 1004 VC_BU_PTS_DispTyp 7;
BA_ "FlexKomSigLaenge" SG_ 1004 VC_BU_PTS_DispTyp 64;
BA_ "FlexKomSigName" SG_ 1004 VC_BU_PTS_DispTyp "VehCfgBU1_Pkt";
BA_ "FlexKomComment" SG_ 1004 VC_BU_PTS_DispTyp "Backup for Vehicle Configuration 1 Packet";
BA_ "FlexKomIsMotorola" SG_ 1004 VC_BU_PTS_DispTyp 1;
BA_ "GenSigSNA" SG_ 1004 VC_BU_PTS_DispTyp "7h";
BA_ "GenSigSendType" SG_ 1004 VC_BU_PP_Prsnt 1;
BA_ "FlexKomSigStartValue" SG_ 1004 VC_BU_PP_Prsnt "FFFF7FF0FF0FFF00h";
BA_ "FlexKomSID" SG_ 1004 VC_BU_PP_Prsnt 919;
BA_ "FlexKomSigStartPos" SG_ 1004 VC_BU_PP_Prsnt 7;
BA_ "FlexKomSigLaenge" SG_ 1004 VC_BU_PP_Prsnt 64;
BA_ "FlexKomSigName" SG_ 1004 VC_BU_PP_Prsnt "VehCfgBU1_Pkt";
BA_ "FlexKomComment" SG_ 1004 VC_BU_PP_Prsnt "Backup for Vehicle Configuration 1 Packet";
BA_ "FlexKomIsMotorola" SG_ 1004 VC_BU_PP_Prsnt 1;
BA_ "GenSigSNA" SG_ 1004 VC_BU_PP_Prsnt "0h";
BA_ "GenSigSendType" SG_ 1004 VC_BU_SpecialPKG 1;
BA_ "FlexKomSigStartValue" SG_ 1004 VC_BU_SpecialPKG "FFFF7FF0FF0FFF00h";
BA_ "GenSigStartValue" SG_ 1004 VC_BU_SpecialPKG 255;
BA_ "FlexKomSID" SG_ 1004 VC_BU_SpecialPKG 919;
BA_ "FlexKomSigStartPos" SG_ 1004 VC_BU_SpecialPKG 7;
BA_ "FlexKomSigLaenge" SG_ 1004 VC_BU_SpecialPKG 64;
BA_ "FlexKomSigName" SG_ 1004 VC_BU_SpecialPKG "VehCfgBU1_Pkt";
BA_ "FlexKomComment" SG_ 1004 VC_BU_SpecialPKG "Backup for Vehicle Configuration 1 Packet";
BA_ "FlexKomIsMotorola" SG_ 1004 VC_BU_SpecialPKG 1;
BA_ "GenSigSNA" SG_ 1004 VC_BU_SpecialPKG "FFh";
BA_ "GenSigSendType" SG_ 1004 VC_BU_HdRstPrsnt 1;
BA_ "FlexKomSigStartValue" SG_ 1004 VC_BU_HdRstPrsnt "FFFF7FF0FF0FFF00h";
BA_ "FlexKomSID" SG_ 1004 VC_BU_HdRstPrsnt 919;
BA_ "FlexKomSigStartPos" SG_ 1004 VC_BU_HdRstPrsnt 7;
BA_ "FlexKomSigLaenge" SG_ 1004 VC_BU_HdRstPrsnt 64;
BA_ "FlexKomSigName" SG_ 1004 VC_BU_HdRstPrsnt "VehCfgBU1_Pkt";
BA_ "FlexKomComment" SG_ 1004 VC_BU_HdRstPrsnt "Backup for Vehicle Configuration 1 Packet";
BA_ "FlexKomIsMotorola" SG_ 1004 VC_BU_HdRstPrsnt 1;
BA_ "GenSigSNA" SG_ 1004 VC_BU_HdRstPrsnt "0h";
BA_ "GenSigSendType" SG_ 1004 VC_BU_SCR_Prsnt 1;
BA_ "FlexKomSigStartValue" SG_ 1004 VC_BU_SCR_Prsnt "FFFF7FF0FF0FFF00h";
BA_ "FlexKomSID" SG_ 1004 VC_BU_SCR_Prsnt 919;
BA_ "FlexKomSigStartPos" SG_ 1004 VC_BU_SCR_Prsnt 7;
BA_ "FlexKomSigLaenge" SG_ 1004 VC_BU_SCR_Prsnt 64;
BA_ "FlexKomSigName" SG_ 1004 VC_BU_SCR_Prsnt "VehCfgBU1_Pkt";
BA_ "FlexKomComment" SG_ 1004 VC_BU_SCR_Prsnt "Backup for Vehicle Configuration 1 Packet";
BA_ "FlexKomIsMotorola" SG_ 1004 VC_BU_SCR_Prsnt 1;
BA_ "GenSigSNA" SG_ 1004 VC_BU_SCR_Prsnt "0h";
BA_ "GenSigSendType" SG_ 1004 VC_BU_PTS_Config 1;
BA_ "FlexKomSigStartValue" SG_ 1004 VC_BU_PTS_Config "FFFF7FF0FF0FFF00h";
BA_ "FlexKomSID" SG_ 1004 VC_BU_PTS_Config 919;
BA_ "FlexKomSigStartPos" SG_ 1004 VC_BU_PTS_Config 7;
BA_ "FlexKomSigLaenge" SG_ 1004 VC_BU_PTS_Config 64;
BA_ "FlexKomSigName" SG_ 1004 VC_BU_PTS_Config "VehCfgBU1_Pkt";
BA_ "FlexKomComment" SG_ 1004 VC_BU_PTS_Config "Backup for Vehicle Configuration 1 Packet";
BA_ "FlexKomIsMotorola" SG_ 1004 VC_BU_PTS_Config 1;
BA_ "GenSigSNA" SG_ 1004 VC_BU_PTS_Config "0h";
BA_ "GenSigSendType" SG_ 1004 VC_BU_RVCM_Prsnt 1;
BA_ "FlexKomSigStartValue" SG_ 1004 VC_BU_RVCM_Prsnt "FFFF7FF0FF0FFF00h";
BA_ "FlexKomSID" SG_ 1004 VC_BU_RVCM_Prsnt 919;
BA_ "FlexKomSigStartPos" SG_ 1004 VC_BU_RVCM_Prsnt 7;
BA_ "FlexKomSigLaenge" SG_ 1004 VC_BU_RVCM_Prsnt 64;
BA_ "FlexKomSigName" SG_ 1004 VC_BU_RVCM_Prsnt "VehCfgBU1_Pkt";
BA_ "FlexKomComment" SG_ 1004 VC_BU_RVCM_Prsnt "Backup for Vehicle Configuration 1 Packet";
BA_ "FlexKomIsMotorola" SG_ 1004 VC_BU_RVCM_Prsnt 1;
BA_ "GenSigSNA" SG_ 1004 VC_BU_RVCM_Prsnt "0h";
BA_ "GenSigSendType" SG_ 1004 VC_BU_CHMCM_Prsnt 1;
BA_ "FlexKomSigStartValue" SG_ 1004 VC_BU_CHMCM_Prsnt "FFFF7FF0FF0FFF00h";
BA_ "FlexKomSID" SG_ 1004 VC_BU_CHMCM_Prsnt 919;
BA_ "FlexKomSigStartPos" SG_ 1004 VC_BU_CHMCM_Prsnt 7;
BA_ "FlexKomSigLaenge" SG_ 1004 VC_BU_CHMCM_Prsnt 64;
BA_ "FlexKomSigName" SG_ 1004 VC_BU_CHMCM_Prsnt "VehCfgBU1_Pkt";
BA_ "FlexKomComment" SG_ 1004 VC_BU_CHMCM_Prsnt "Backup for Vehicle Configuration 1 Packet";
BA_ "FlexKomIsMotorola" SG_ 1004 VC_BU_CHMCM_Prsnt 1;
BA_ "GenSigSNA" SG_ 1004 VC_BU_CHMCM_Prsnt "0h";
BA_ "GenSigSendType" SG_ 1004 VC_BU_HDC_Prsnt 1;
BA_ "FlexKomSigStartValue" SG_ 1004 VC_BU_HDC_Prsnt "FFFF7FF0FF0FFF00h";
BA_ "FlexKomSID" SG_ 1004 VC_BU_HDC_Prsnt 919;
BA_ "FlexKomSigStartPos" SG_ 1004 VC_BU_HDC_Prsnt 7;
BA_ "FlexKomSigLaenge" SG_ 1004 VC_BU_HDC_Prsnt 64;
BA_ "FlexKomSigName" SG_ 1004 VC_BU_HDC_Prsnt "VehCfgBU1_Pkt";
BA_ "FlexKomComment" SG_ 1004 VC_BU_HDC_Prsnt "Backup for Vehicle Configuration 1 Packet";
BA_ "FlexKomIsMotorola" SG_ 1004 VC_BU_HDC_Prsnt 1;
BA_ "GenSigSNA" SG_ 1004 VC_BU_HDC_Prsnt "0h";
BA_ "GenSigSendType" SG_ 1004 VC_BU_SSC_Prsnt 1;
BA_ "FlexKomSigStartValue" SG_ 1004 VC_BU_SSC_Prsnt "FFFF7FF0FF0FFF00h";
BA_ "FlexKomSID" SG_ 1004 VC_BU_SSC_Prsnt 919;
BA_ "FlexKomSigStartPos" SG_ 1004 VC_BU_SSC_Prsnt 7;
BA_ "FlexKomSigLaenge" SG_ 1004 VC_BU_SSC_Prsnt 64;
BA_ "FlexKomSigName" SG_ 1004 VC_BU_SSC_Prsnt "VehCfgBU1_Pkt";
BA_ "FlexKomComment" SG_ 1004 VC_BU_SSC_Prsnt "Backup for Vehicle Configuration 1 Packet";
BA_ "FlexKomIsMotorola" SG_ 1004 VC_BU_SSC_Prsnt 1;
BA_ "GenSigSNA" SG_ 1004 VC_BU_SSC_Prsnt "0h";
BA_ "GenSigSendType" SG_ 1005 VC_BU_VehCfg2_Stat 1;
BA_ "FlexKomSigStartValue" SG_ 1005 VC_BU_VehCfg2_Stat "0300FF00FFFFFFFFh";
BA_ "GenSigStartValue" SG_ 1005 VC_BU_VehCfg2_Stat 3;
BA_ "FlexKomSID" SG_ 1005 VC_BU_VehCfg2_Stat 920;
BA_ "FlexKomSigStartPos" SG_ 1005 VC_BU_VehCfg2_Stat 7;
BA_ "FlexKomSigLaenge" SG_ 1005 VC_BU_VehCfg2_Stat 64;
BA_ "FlexKomSigName" SG_ 1005 VC_BU_VehCfg2_Stat "VehCfgBu2_Pkt";
BA_ "FlexKomComment" SG_ 1005 VC_BU_VehCfg2_Stat "Vehicle Configuration Backup 2 Packet";
BA_ "FlexKomIsMotorola" SG_ 1005 VC_BU_VehCfg2_Stat 1;
BA_ "GenSigSNA" SG_ 1005 VC_BU_VehCfg2_Stat "3h";
BA_ "GenSigSendType" SG_ 1005 VC_BU_PwrIvtrTyp 1;
BA_ "FlexKomSigStartValue" SG_ 1005 VC_BU_PwrIvtrTyp "0300FF00FFFFFFFFh";
BA_ "FlexKomSID" SG_ 1005 VC_BU_PwrIvtrTyp 920;
BA_ "FlexKomSigStartPos" SG_ 1005 VC_BU_PwrIvtrTyp 7;
BA_ "FlexKomSigLaenge" SG_ 1005 VC_BU_PwrIvtrTyp 64;
BA_ "FlexKomSigName" SG_ 1005 VC_BU_PwrIvtrTyp "VehCfgBu2_Pkt";
BA_ "FlexKomComment" SG_ 1005 VC_BU_PwrIvtrTyp "Vehicle Configuration Backup 2 Packet";
BA_ "FlexKomIsMotorola" SG_ 1005 VC_BU_PwrIvtrTyp 1;
BA_ "GenSigSNA" SG_ 1005 VC_BU_PwrIvtrTyp "0h";
BA_ "GenSigSendType" SG_ 1005 VC_BU_ThatchamPrsnt 1;
BA_ "FlexKomSigStartValue" SG_ 1005 VC_BU_ThatchamPrsnt "0300FF00FFFFFFFFh";
BA_ "FlexKomSID" SG_ 1005 VC_BU_ThatchamPrsnt 920;
BA_ "FlexKomSigStartPos" SG_ 1005 VC_BU_ThatchamPrsnt 7;
BA_ "FlexKomSigLaenge" SG_ 1005 VC_BU_ThatchamPrsnt 64;
BA_ "FlexKomSigName" SG_ 1005 VC_BU_ThatchamPrsnt "VehCfgBu2_Pkt";
BA_ "FlexKomComment" SG_ 1005 VC_BU_ThatchamPrsnt "Vehicle Configuration Backup 2 Packet";
BA_ "FlexKomIsMotorola" SG_ 1005 VC_BU_ThatchamPrsnt 1;
BA_ "GenSigSNA" SG_ 1005 VC_BU_ThatchamPrsnt "0h";
BA_ "GenSigSendType" SG_ 1005 VC_BU_RunFlatTirePrsnt 1;
BA_ "FlexKomSigStartValue" SG_ 1005 VC_BU_RunFlatTirePrsnt "0300FF00FFFFFFFFh";
BA_ "FlexKomSID" SG_ 1005 VC_BU_RunFlatTirePrsnt 920;
BA_ "FlexKomSigStartPos" SG_ 1005 VC_BU_RunFlatTirePrsnt 7;
BA_ "FlexKomSigLaenge" SG_ 1005 VC_BU_RunFlatTirePrsnt 64;
BA_ "FlexKomSigName" SG_ 1005 VC_BU_RunFlatTirePrsnt "VehCfgBu2_Pkt";
BA_ "FlexKomComment" SG_ 1005 VC_BU_RunFlatTirePrsnt "Vehicle Configuration Backup 2 Packet";
BA_ "FlexKomIsMotorola" SG_ 1005 VC_BU_RunFlatTirePrsnt 1;
BA_ "GenSigSNA" SG_ 1005 VC_BU_RunFlatTirePrsnt "0h";
BA_ "GenSigSendType" SG_ 1005 VC_BU_MaseratiMd 1;
BA_ "FlexKomSigStartValue" SG_ 1005 VC_BU_MaseratiMd "0300FF00FFFFFFFFh";
BA_ "FlexKomSID" SG_ 1005 VC_BU_MaseratiMd 920;
BA_ "FlexKomSigStartPos" SG_ 1005 VC_BU_MaseratiMd 7;
BA_ "FlexKomSigLaenge" SG_ 1005 VC_BU_MaseratiMd 64;
BA_ "FlexKomSigName" SG_ 1005 VC_BU_MaseratiMd "VehCfgBu2_Pkt";
BA_ "FlexKomComment" SG_ 1005 VC_BU_MaseratiMd "Vehicle Configuration Backup 2 Packet";
BA_ "FlexKomIsMotorola" SG_ 1005 VC_BU_MaseratiMd 1;
BA_ "GenSigSNA" SG_ 1005 VC_BU_MaseratiMd "3h";
BA_ "GenSigSendType" SG_ 1005 VC_BU_PADS_Prsnt 1;
BA_ "FlexKomSigStartValue" SG_ 1005 VC_BU_PADS_Prsnt "0300FF00FFFFFFFFh";
BA_ "FlexKomSID" SG_ 1005 VC_BU_PADS_Prsnt 920;
BA_ "FlexKomSigStartPos" SG_ 1005 VC_BU_PADS_Prsnt 7;
BA_ "FlexKomSigLaenge" SG_ 1005 VC_BU_PADS_Prsnt 64;
BA_ "FlexKomSigName" SG_ 1005 VC_BU_PADS_Prsnt "VehCfgBu2_Pkt";
BA_ "FlexKomComment" SG_ 1005 VC_BU_PADS_Prsnt "Vehicle Configuration Backup 2 Packet";
BA_ "FlexKomIsMotorola" SG_ 1005 VC_BU_PADS_Prsnt 1;
BA_ "GenSigSNA" SG_ 1005 VC_BU_PADS_Prsnt "0h";
BA_ "GenSigSendType" SG_ 1005 VC_BU_RainSnsPrsnt 1;
BA_ "FlexKomSigStartValue" SG_ 1005 VC_BU_RainSnsPrsnt "0300FF00FFFFFFFFh";
BA_ "FlexKomSID" SG_ 1005 VC_BU_RainSnsPrsnt 920;
BA_ "FlexKomSigStartPos" SG_ 1005 VC_BU_RainSnsPrsnt 7;
BA_ "FlexKomSigLaenge" SG_ 1005 VC_BU_RainSnsPrsnt 64;
BA_ "FlexKomSigName" SG_ 1005 VC_BU_RainSnsPrsnt "VehCfgBu2_Pkt";
BA_ "FlexKomComment" SG_ 1005 VC_BU_RainSnsPrsnt "Vehicle Configuration Backup 2 Packet";
BA_ "FlexKomIsMotorola" SG_ 1005 VC_BU_RainSnsPrsnt 1;
BA_ "GenSigSNA" SG_ 1005 VC_BU_RainSnsPrsnt "0h";
BA_ "GenSigSendType" SG_ 1005 VC_BU_SKIM_PRSNT 1;
BA_ "FlexKomSigStartValue" SG_ 1005 VC_BU_SKIM_PRSNT "0300FF00FFFFFFFFh";
BA_ "FlexKomSID" SG_ 1005 VC_BU_SKIM_PRSNT 920;
BA_ "FlexKomSigStartPos" SG_ 1005 VC_BU_SKIM_PRSNT 7;
BA_ "FlexKomSigLaenge" SG_ 1005 VC_BU_SKIM_PRSNT 64;
BA_ "FlexKomSigName" SG_ 1005 VC_BU_SKIM_PRSNT "VehCfgBu2_Pkt";
BA_ "FlexKomComment" SG_ 1005 VC_BU_SKIM_PRSNT "Vehicle Configuration Backup 2 Packet";
BA_ "FlexKomIsMotorola" SG_ 1005 VC_BU_SKIM_PRSNT 1;
BA_ "GenSigSNA" SG_ 1005 VC_BU_SKIM_PRSNT "0h";
BA_ "GenSigSendType" SG_ 1005 VC_BU_AC_Prsnt 1;
BA_ "FlexKomSigStartValue" SG_ 1005 VC_BU_AC_Prsnt "0300FF00FFFFFFFFh";
BA_ "FlexKomSID" SG_ 1005 VC_BU_AC_Prsnt 920;
BA_ "FlexKomSigStartPos" SG_ 1005 VC_BU_AC_Prsnt 7;
BA_ "FlexKomSigLaenge" SG_ 1005 VC_BU_AC_Prsnt 64;
BA_ "FlexKomSigName" SG_ 1005 VC_BU_AC_Prsnt "VehCfgBu2_Pkt";
BA_ "FlexKomComment" SG_ 1005 VC_BU_AC_Prsnt "Vehicle Configuration Backup 2 Packet";
BA_ "FlexKomIsMotorola" SG_ 1005 VC_BU_AC_Prsnt 1;
BA_ "GenSigSNA" SG_ 1005 VC_BU_AC_Prsnt "0h";
BA_ "GenSigSendType" SG_ 1005 VC_BU_CRUISE_PRSNT 1;
BA_ "FlexKomSigStartValue" SG_ 1005 VC_BU_CRUISE_PRSNT "0300FF00FFFFFFFFh";
BA_ "FlexKomSID" SG_ 1005 VC_BU_CRUISE_PRSNT 920;
BA_ "FlexKomSigStartPos" SG_ 1005 VC_BU_CRUISE_PRSNT 7;
BA_ "FlexKomSigLaenge" SG_ 1005 VC_BU_CRUISE_PRSNT 64;
BA_ "FlexKomSigName" SG_ 1005 VC_BU_CRUISE_PRSNT "VehCfgBu2_Pkt";
BA_ "FlexKomComment" SG_ 1005 VC_BU_CRUISE_PRSNT "Vehicle Configuration Backup 2 Packet";
BA_ "FlexKomIsMotorola" SG_ 1005 VC_BU_CRUISE_PRSNT 1;
BA_ "GenSigSNA" SG_ 1005 VC_BU_CRUISE_PRSNT "0h";
BA_ "GenSigSendType" SG_ 1005 VC_BU_FG_PRSNT 1;
BA_ "FlexKomSigStartValue" SG_ 1005 VC_BU_FG_PRSNT "0300FF00FFFFFFFFh";
BA_ "FlexKomSID" SG_ 1005 VC_BU_FG_PRSNT 920;
BA_ "FlexKomSigStartPos" SG_ 1005 VC_BU_FG_PRSNT 7;
BA_ "FlexKomSigLaenge" SG_ 1005 VC_BU_FG_PRSNT 64;
BA_ "FlexKomSigName" SG_ 1005 VC_BU_FG_PRSNT "VehCfgBu2_Pkt";
BA_ "FlexKomComment" SG_ 1005 VC_BU_FG_PRSNT "Vehicle Configuration Backup 2 Packet";
BA_ "FlexKomIsMotorola" SG_ 1005 VC_BU_FG_PRSNT 1;
BA_ "GenSigSNA" SG_ 1005 VC_BU_FG_PRSNT "0h";
BA_ "GenSigSendType" SG_ 1005 VC_BU_FULL_SPARE 1;
BA_ "FlexKomSigStartValue" SG_ 1005 VC_BU_FULL_SPARE "0300FF00FFFFFFFFh";
BA_ "FlexKomSID" SG_ 1005 VC_BU_FULL_SPARE 920;
BA_ "FlexKomSigStartPos" SG_ 1005 VC_BU_FULL_SPARE 7;
BA_ "FlexKomSigLaenge" SG_ 1005 VC_BU_FULL_SPARE 64;
BA_ "FlexKomSigName" SG_ 1005 VC_BU_FULL_SPARE "VehCfgBu2_Pkt";
BA_ "FlexKomComment" SG_ 1005 VC_BU_FULL_SPARE "Vehicle Configuration Backup 2 Packet";
BA_ "FlexKomIsMotorola" SG_ 1005 VC_BU_FULL_SPARE 1;
BA_ "GenSigSNA" SG_ 1005 VC_BU_FULL_SPARE "0h";
BA_ "GenSigSendType" SG_ 1005 VC_BU_OffRoad 1;
BA_ "FlexKomSigStartValue" SG_ 1005 VC_BU_OffRoad "0300FF00FFFFFFFFh";
BA_ "FlexKomSID" SG_ 1005 VC_BU_OffRoad 920;
BA_ "FlexKomSigStartPos" SG_ 1005 VC_BU_OffRoad 7;
BA_ "FlexKomSigLaenge" SG_ 1005 VC_BU_OffRoad 64;
BA_ "FlexKomSigName" SG_ 1005 VC_BU_OffRoad "VehCfgBu2_Pkt";
BA_ "FlexKomComment" SG_ 1005 VC_BU_OffRoad "Vehicle Configuration Backup 2 Packet";
BA_ "FlexKomIsMotorola" SG_ 1005 VC_BU_OffRoad 1;
BA_ "GenSigSNA" SG_ 1005 VC_BU_OffRoad "0h";
BA_ "GenSigSendType" SG_ 1005 VC_BU_SpecialPKG_IC 1;
BA_ "FlexKomSigStartValue" SG_ 1005 VC_BU_SpecialPKG_IC "0300FF00FFFFFFFFh";
BA_ "GenSigStartValue" SG_ 1005 VC_BU_SpecialPKG_IC 255;
BA_ "FlexKomSID" SG_ 1005 VC_BU_SpecialPKG_IC 920;
BA_ "FlexKomSigStartPos" SG_ 1005 VC_BU_SpecialPKG_IC 7;
BA_ "FlexKomSigLaenge" SG_ 1005 VC_BU_SpecialPKG_IC 64;
BA_ "FlexKomSigName" SG_ 1005 VC_BU_SpecialPKG_IC "VehCfgBu2_Pkt";
BA_ "FlexKomComment" SG_ 1005 VC_BU_SpecialPKG_IC "Vehicle Configuration Backup 2 Packet";
BA_ "FlexKomIsMotorola" SG_ 1005 VC_BU_SpecialPKG_IC 1;
BA_ "GenSigSNA" SG_ 1005 VC_BU_SpecialPKG_IC "FFh";
BA_ "GenSigSendType" SG_ 1005 VC_BU_ECO_Indicator 1;
BA_ "FlexKomSigStartValue" SG_ 1005 VC_BU_ECO_Indicator "0300FF00FFFFFFFFh";
BA_ "FlexKomSID" SG_ 1005 VC_BU_ECO_Indicator 920;
BA_ "FlexKomSigStartPos" SG_ 1005 VC_BU_ECO_Indicator 7;
BA_ "FlexKomSigLaenge" SG_ 1005 VC_BU_ECO_Indicator 64;
BA_ "FlexKomSigName" SG_ 1005 VC_BU_ECO_Indicator "VehCfgBu2_Pkt";
BA_ "FlexKomComment" SG_ 1005 VC_BU_ECO_Indicator "Vehicle Configuration Backup 2 Packet";
BA_ "FlexKomIsMotorola" SG_ 1005 VC_BU_ECO_Indicator 1;
BA_ "GenSigSNA" SG_ 1005 VC_BU_ECO_Indicator "0h";
BA_ "GenSigSendType" SG_ 1005 VC_BU_DRVMD_Prsnt 1;
BA_ "FlexKomSigStartValue" SG_ 1005 VC_BU_DRVMD_Prsnt "0300FF00FFFFFFFFh";
BA_ "FlexKomSID" SG_ 1005 VC_BU_DRVMD_Prsnt 920;
BA_ "FlexKomSigStartPos" SG_ 1005 VC_BU_DRVMD_Prsnt 7;
BA_ "FlexKomSigLaenge" SG_ 1005 VC_BU_DRVMD_Prsnt 64;
BA_ "FlexKomSigName" SG_ 1005 VC_BU_DRVMD_Prsnt "VehCfgBu2_Pkt";
BA_ "FlexKomComment" SG_ 1005 VC_BU_DRVMD_Prsnt "Vehicle Configuration Backup 2 Packet";
BA_ "FlexKomIsMotorola" SG_ 1005 VC_BU_DRVMD_Prsnt 1;
BA_ "GenSigSNA" SG_ 1005 VC_BU_DRVMD_Prsnt "0h";
BA_ "GenSigSendType" SG_ 1005 VC_BU_MemoryDRVMD_Prsnt 1;
BA_ "FlexKomSigStartValue" SG_ 1005 VC_BU_MemoryDRVMD_Prsnt "0300FF00FFFFFFFFh";
BA_ "FlexKomSID" SG_ 1005 VC_BU_MemoryDRVMD_Prsnt 920;
BA_ "FlexKomSigStartPos" SG_ 1005 VC_BU_MemoryDRVMD_Prsnt 7;
BA_ "FlexKomSigLaenge" SG_ 1005 VC_BU_MemoryDRVMD_Prsnt 64;
BA_ "FlexKomSigName" SG_ 1005 VC_BU_MemoryDRVMD_Prsnt "VehCfgBu2_Pkt";
BA_ "FlexKomComment" SG_ 1005 VC_BU_MemoryDRVMD_Prsnt "Vehicle Configuration Backup 2 Packet";
BA_ "FlexKomIsMotorola" SG_ 1005 VC_BU_MemoryDRVMD_Prsnt 1;
BA_ "GenSigSNA" SG_ 1005 VC_BU_MemoryDRVMD_Prsnt "0h";
BA_ "GenSigSendType" SG_ 1005 VC_BU_ESCDrvMd_Prsnt 1;
BA_ "FlexKomSigStartValue" SG_ 1005 VC_BU_ESCDrvMd_Prsnt "0300FF00FFFFFFFFh";
BA_ "FlexKomSID" SG_ 1005 VC_BU_ESCDrvMd_Prsnt 920;
BA_ "FlexKomSigStartPos" SG_ 1005 VC_BU_ESCDrvMd_Prsnt 7;
BA_ "FlexKomSigLaenge" SG_ 1005 VC_BU_ESCDrvMd_Prsnt 64;
BA_ "FlexKomSigName" SG_ 1005 VC_BU_ESCDrvMd_Prsnt "VehCfgBu2_Pkt";
BA_ "FlexKomComment" SG_ 1005 VC_BU_ESCDrvMd_Prsnt "Vehicle Configuration Backup 2 Packet";
BA_ "FlexKomIsMotorola" SG_ 1005 VC_BU_ESCDrvMd_Prsnt 1;
BA_ "GenSigSNA" SG_ 1005 VC_BU_ESCDrvMd_Prsnt "0h";
BA_ "GenSigSendType" SG_ 1005 VC_BU_EngPowerDrvMd_Prsnt 1;
BA_ "FlexKomSigStartValue" SG_ 1005 VC_BU_EngPowerDrvMd_Prsnt "0300FF00FFFFFFFFh";
BA_ "FlexKomSID" SG_ 1005 VC_BU_EngPowerDrvMd_Prsnt 920;
BA_ "FlexKomSigStartPos" SG_ 1005 VC_BU_EngPowerDrvMd_Prsnt 7;
BA_ "FlexKomSigLaenge" SG_ 1005 VC_BU_EngPowerDrvMd_Prsnt 64;
BA_ "FlexKomSigName" SG_ 1005 VC_BU_EngPowerDrvMd_Prsnt "VehCfgBu2_Pkt";
BA_ "FlexKomComment" SG_ 1005 VC_BU_EngPowerDrvMd_Prsnt "Vehicle Configuration Backup 2 Packet";
BA_ "FlexKomIsMotorola" SG_ 1005 VC_BU_EngPowerDrvMd_Prsnt 1;
BA_ "GenSigSNA" SG_ 1005 VC_BU_EngPowerDrvMd_Prsnt "0h";
BA_ "GenSigSendType" SG_ 1005 VC_BU_SecPrkPrsnt 1;
BA_ "FlexKomSigStartValue" SG_ 1005 VC_BU_SecPrkPrsnt "0300FF00FFFFFFFFh";
BA_ "FlexKomSID" SG_ 1005 VC_BU_SecPrkPrsnt 920;
BA_ "FlexKomSigStartPos" SG_ 1005 VC_BU_SecPrkPrsnt 7;
BA_ "FlexKomSigLaenge" SG_ 1005 VC_BU_SecPrkPrsnt 64;
BA_ "FlexKomSigName" SG_ 1005 VC_BU_SecPrkPrsnt "VehCfgBu2_Pkt";
BA_ "FlexKomComment" SG_ 1005 VC_BU_SecPrkPrsnt "Vehicle Configuration Backup 2 Packet";
BA_ "FlexKomIsMotorola" SG_ 1005 VC_BU_SecPrkPrsnt 1;
BA_ "GenSigSNA" SG_ 1005 VC_BU_SecPrkPrsnt "0h";
BA_ "GenSigSendType" SG_ 1005 VC_BU_ShftInd_Prsnt 1;
BA_ "FlexKomSigStartValue" SG_ 1005 VC_BU_ShftInd_Prsnt "0300FF00FFFFFFFFh";
BA_ "FlexKomSID" SG_ 1005 VC_BU_ShftInd_Prsnt 920;
BA_ "FlexKomSigStartPos" SG_ 1005 VC_BU_ShftInd_Prsnt 7;
BA_ "FlexKomSigLaenge" SG_ 1005 VC_BU_ShftInd_Prsnt 64;
BA_ "FlexKomSigName" SG_ 1005 VC_BU_ShftInd_Prsnt "VehCfgBu2_Pkt";
BA_ "FlexKomComment" SG_ 1005 VC_BU_ShftInd_Prsnt "Vehicle Configuration Backup 2 Packet";
BA_ "FlexKomIsMotorola" SG_ 1005 VC_BU_ShftInd_Prsnt 1;
BA_ "GenSigSNA" SG_ 1005 VC_BU_ShftInd_Prsnt "0h";
BA_ "GenSigSendType" SG_ 1005 VC_BU_MaxLdPressRrTr 1;
BA_ "FlexKomSigStartValue" SG_ 1005 VC_BU_MaxLdPressRrTr "0300FF00FFFFFFFFh";
BA_ "GenSigStartValue" SG_ 1005 VC_BU_MaxLdPressRrTr 255;
BA_ "FlexKomSID" SG_ 1005 VC_BU_MaxLdPressRrTr 920;
BA_ "FlexKomSigStartPos" SG_ 1005 VC_BU_MaxLdPressRrTr 7;
BA_ "FlexKomSigLaenge" SG_ 1005 VC_BU_MaxLdPressRrTr 64;
BA_ "FlexKomSigName" SG_ 1005 VC_BU_MaxLdPressRrTr "VehCfgBu2_Pkt";
BA_ "FlexKomComment" SG_ 1005 VC_BU_MaxLdPressRrTr "Vehicle Configuration Backup 2 Packet";
BA_ "FlexKomIsMotorola" SG_ 1005 VC_BU_MaxLdPressRrTr 1;
BA_ "GenSigSNA" SG_ 1005 VC_BU_MaxLdPressRrTr "FFh";
BA_ "GenSigSendType" SG_ 1005 VC_BU_MaxLdPressFtTr 1;
BA_ "FlexKomSigStartValue" SG_ 1005 VC_BU_MaxLdPressFtTr "0300FF00FFFFFFFFh";
BA_ "GenSigStartValue" SG_ 1005 VC_BU_MaxLdPressFtTr 255;
BA_ "FlexKomSID" SG_ 1005 VC_BU_MaxLdPressFtTr 920;
BA_ "FlexKomSigStartPos" SG_ 1005 VC_BU_MaxLdPressFtTr 7;
BA_ "FlexKomSigLaenge" SG_ 1005 VC_BU_MaxLdPressFtTr 64;
BA_ "FlexKomSigName" SG_ 1005 VC_BU_MaxLdPressFtTr "VehCfgBu2_Pkt";
BA_ "FlexKomComment" SG_ 1005 VC_BU_MaxLdPressFtTr "Vehicle Configuration Backup 2 Packet";
BA_ "FlexKomIsMotorola" SG_ 1005 VC_BU_MaxLdPressFtTr 1;
BA_ "GenSigSNA" SG_ 1005 VC_BU_MaxLdPressFtTr "FFh";
BA_ "GenSigSendType" SG_ 1005 VC_BU_LgtLdPressRrTr 1;
BA_ "FlexKomSigStartValue" SG_ 1005 VC_BU_LgtLdPressRrTr "0300FF00FFFFFFFFh";
BA_ "GenSigStartValue" SG_ 1005 VC_BU_LgtLdPressRrTr 255;
BA_ "FlexKomSID" SG_ 1005 VC_BU_LgtLdPressRrTr 920;
BA_ "FlexKomSigStartPos" SG_ 1005 VC_BU_LgtLdPressRrTr 7;
BA_ "FlexKomSigLaenge" SG_ 1005 VC_BU_LgtLdPressRrTr 64;
BA_ "FlexKomSigName" SG_ 1005 VC_BU_LgtLdPressRrTr "VehCfgBu2_Pkt";
BA_ "FlexKomComment" SG_ 1005 VC_BU_LgtLdPressRrTr "Vehicle Configuration Backup 2 Packet";
BA_ "FlexKomIsMotorola" SG_ 1005 VC_BU_LgtLdPressRrTr 1;
BA_ "GenSigSNA" SG_ 1005 VC_BU_LgtLdPressRrTr "FFh";
BA_ "GenSigSendType" SG_ 1005 VC_BU_LgtLdPressFtTr 1;
BA_ "FlexKomSigStartValue" SG_ 1005 VC_BU_LgtLdPressFtTr "0300FF00FFFFFFFFh";
BA_ "GenSigStartValue" SG_ 1005 VC_BU_LgtLdPressFtTr 255;
BA_ "FlexKomSID" SG_ 1005 VC_BU_LgtLdPressFtTr 920;
BA_ "FlexKomSigStartPos" SG_ 1005 VC_BU_LgtLdPressFtTr 7;
BA_ "FlexKomSigLaenge" SG_ 1005 VC_BU_LgtLdPressFtTr 64;
BA_ "FlexKomSigName" SG_ 1005 VC_BU_LgtLdPressFtTr "VehCfgBu2_Pkt";
BA_ "FlexKomComment" SG_ 1005 VC_BU_LgtLdPressFtTr "Vehicle Configuration Backup 2 Packet";
BA_ "FlexKomIsMotorola" SG_ 1005 VC_BU_LgtLdPressFtTr 1;
BA_ "GenSigSNA" SG_ 1005 VC_BU_LgtLdPressFtTr "FFh";
BA_ "GenSigSendType" SG_ 1006 VC_BU_VehCfg3_Stat 1;
BA_ "FlexKomSigStartValue" SG_ 1006 VC_BU_VehCfg3_Stat "0370FF037FFF0000h";
BA_ "GenSigStartValue" SG_ 1006 VC_BU_VehCfg3_Stat 3;
BA_ "FlexKomSID" SG_ 1006 VC_BU_VehCfg3_Stat 921;
BA_ "FlexKomSigStartPos" SG_ 1006 VC_BU_VehCfg3_Stat 7;
BA_ "FlexKomSigLaenge" SG_ 1006 VC_BU_VehCfg3_Stat 64;
BA_ "FlexKomSigName" SG_ 1006 VC_BU_VehCfg3_Stat "VehCfgBu3_Pkt";
BA_ "FlexKomComment" SG_ 1006 VC_BU_VehCfg3_Stat "Vehicle Configuration Backup 3 Packet";
BA_ "FlexKomIsMotorola" SG_ 1006 VC_BU_VehCfg3_Stat 1;
BA_ "GenSigSNA" SG_ 1006 VC_BU_VehCfg3_Stat "3h";
BA_ "GenSigSendType" SG_ 1006 VC_BU_POLICE 1;
BA_ "FlexKomSigStartValue" SG_ 1006 VC_BU_POLICE "0370FF037FFF0000h";
BA_ "FlexKomSID" SG_ 1006 VC_BU_POLICE 921;
BA_ "FlexKomSigStartPos" SG_ 1006 VC_BU_POLICE 7;
BA_ "FlexKomSigLaenge" SG_ 1006 VC_BU_POLICE 64;
BA_ "FlexKomSigName" SG_ 1006 VC_BU_POLICE "VehCfgBu3_Pkt";
BA_ "FlexKomComment" SG_ 1006 VC_BU_POLICE "Vehicle Configuration Backup 3 Packet";
BA_ "FlexKomIsMotorola" SG_ 1006 VC_BU_POLICE 1;
BA_ "GenSigSNA" SG_ 1006 VC_BU_POLICE "0h";
BA_ "GenSigSendType" SG_ 1006 VC_BU_PWR_LFT_GT 1;
BA_ "FlexKomSigStartValue" SG_ 1006 VC_BU_PWR_LFT_GT "0370FF037FFF0000h";
BA_ "FlexKomSID" SG_ 1006 VC_BU_PWR_LFT_GT 921;
BA_ "FlexKomSigStartPos" SG_ 1006 VC_BU_PWR_LFT_GT 7;
BA_ "FlexKomSigLaenge" SG_ 1006 VC_BU_PWR_LFT_GT 64;
BA_ "FlexKomSigName" SG_ 1006 VC_BU_PWR_LFT_GT "VehCfgBu3_Pkt";
BA_ "FlexKomComment" SG_ 1006 VC_BU_PWR_LFT_GT "Vehicle Configuration Backup 3 Packet";
BA_ "FlexKomIsMotorola" SG_ 1006 VC_BU_PWR_LFT_GT 1;
BA_ "GenSigSNA" SG_ 1006 VC_BU_PWR_LFT_GT "0h";
BA_ "GenSigSendType" SG_ 1006 VC_BU_PWR_RT_SLDR 1;
BA_ "FlexKomSigStartValue" SG_ 1006 VC_BU_PWR_RT_SLDR "0370FF037FFF0000h";
BA_ "FlexKomSID" SG_ 1006 VC_BU_PWR_RT_SLDR 921;
BA_ "FlexKomSigStartPos" SG_ 1006 VC_BU_PWR_RT_SLDR 7;
BA_ "FlexKomSigLaenge" SG_ 1006 VC_BU_PWR_RT_SLDR 64;
BA_ "FlexKomSigName" SG_ 1006 VC_BU_PWR_RT_SLDR "VehCfgBu3_Pkt";
BA_ "FlexKomComment" SG_ 1006 VC_BU_PWR_RT_SLDR "Vehicle Configuration Backup 3 Packet";
BA_ "FlexKomIsMotorola" SG_ 1006 VC_BU_PWR_RT_SLDR 1;
BA_ "GenSigSNA" SG_ 1006 VC_BU_PWR_RT_SLDR "0h";
BA_ "GenSigSendType" SG_ 1006 VC_BU_PWR_LT_SLDR 1;
BA_ "FlexKomSigStartValue" SG_ 1006 VC_BU_PWR_LT_SLDR "0370FF037FFF0000h";
BA_ "FlexKomSID" SG_ 1006 VC_BU_PWR_LT_SLDR 921;
BA_ "FlexKomSigStartPos" SG_ 1006 VC_BU_PWR_LT_SLDR 7;
BA_ "FlexKomSigLaenge" SG_ 1006 VC_BU_PWR_LT_SLDR 64;
BA_ "FlexKomSigName" SG_ 1006 VC_BU_PWR_LT_SLDR "VehCfgBu3_Pkt";
BA_ "FlexKomComment" SG_ 1006 VC_BU_PWR_LT_SLDR "Vehicle Configuration Backup 3 Packet";
BA_ "FlexKomIsMotorola" SG_ 1006 VC_BU_PWR_LT_SLDR 1;
BA_ "GenSigSNA" SG_ 1006 VC_BU_PWR_LT_SLDR "0h";
BA_ "GenSigSendType" SG_ 1006 VC_BU_RKE_PRSNT 1;
BA_ "FlexKomSigStartValue" SG_ 1006 VC_BU_RKE_PRSNT "0370FF037FFF0000h";
BA_ "FlexKomSID" SG_ 1006 VC_BU_RKE_PRSNT 921;
BA_ "FlexKomSigStartPos" SG_ 1006 VC_BU_RKE_PRSNT 7;
BA_ "FlexKomSigLaenge" SG_ 1006 VC_BU_RKE_PRSNT 64;
BA_ "FlexKomSigName" SG_ 1006 VC_BU_RKE_PRSNT "VehCfgBu3_Pkt";
BA_ "FlexKomComment" SG_ 1006 VC_BU_RKE_PRSNT "Vehicle Configuration Backup 3 Packet";
BA_ "FlexKomIsMotorola" SG_ 1006 VC_BU_RKE_PRSNT 1;
BA_ "GenSigSNA" SG_ 1006 VC_BU_RKE_PRSNT "0h";
BA_ "GenSigSendType" SG_ 1006 VC_BU_SunShade_Present 1;
BA_ "FlexKomSigStartValue" SG_ 1006 VC_BU_SunShade_Present "0370FF037FFF0000h";
BA_ "FlexKomSID" SG_ 1006 VC_BU_SunShade_Present 921;
BA_ "FlexKomSigStartPos" SG_ 1006 VC_BU_SunShade_Present 7;
BA_ "FlexKomSigLaenge" SG_ 1006 VC_BU_SunShade_Present 64;
BA_ "FlexKomSigName" SG_ 1006 VC_BU_SunShade_Present "VehCfgBu3_Pkt";
BA_ "FlexKomComment" SG_ 1006 VC_BU_SunShade_Present "Vehicle Configuration Backup 3 Packet";
BA_ "FlexKomIsMotorola" SG_ 1006 VC_BU_SunShade_Present 1;
BA_ "GenSigSNA" SG_ 1006 VC_BU_SunShade_Present "0h";
BA_ "GenSigSendType" SG_ 1006 VC_BU_TcaseTyp 1;
BA_ "FlexKomSigStartValue" SG_ 1006 VC_BU_TcaseTyp "0370FF037FFF0000h";
BA_ "FlexKomSID" SG_ 1006 VC_BU_TcaseTyp 921;
BA_ "FlexKomSigStartPos" SG_ 1006 VC_BU_TcaseTyp 7;
BA_ "FlexKomSigLaenge" SG_ 1006 VC_BU_TcaseTyp 64;
BA_ "FlexKomSigName" SG_ 1006 VC_BU_TcaseTyp "VehCfgBu3_Pkt";
BA_ "FlexKomComment" SG_ 1006 VC_BU_TcaseTyp "Vehicle Configuration Backup 3 Packet";
BA_ "FlexKomIsMotorola" SG_ 1006 VC_BU_TcaseTyp 1;
BA_ "GenSigSNA" SG_ 1006 VC_BU_TcaseTyp "0h";
BA_ "GenSigSendType" SG_ 1006 VC_BU_WHL_BASE 1;
BA_ "FlexKomSigStartValue" SG_ 1006 VC_BU_WHL_BASE "0370FF037FFF0000h";
BA_ "GenSigStartValue" SG_ 1006 VC_BU_WHL_BASE 3;
BA_ "FlexKomSID" SG_ 1006 VC_BU_WHL_BASE 921;
BA_ "FlexKomSigStartPos" SG_ 1006 VC_BU_WHL_BASE 7;
BA_ "FlexKomSigLaenge" SG_ 1006 VC_BU_WHL_BASE 64;
BA_ "FlexKomSigName" SG_ 1006 VC_BU_WHL_BASE "VehCfgBu3_Pkt";
BA_ "FlexKomComment" SG_ 1006 VC_BU_WHL_BASE "Vehicle Configuration Backup 3 Packet";
BA_ "FlexKomIsMotorola" SG_ 1006 VC_BU_WHL_BASE 1;
BA_ "GenSigSNA" SG_ 1006 VC_BU_WHL_BASE "3h";
BA_ "GenSigSendType" SG_ 1006 VC_BU_FOBIKsafeENBL 1;
BA_ "FlexKomSigStartValue" SG_ 1006 VC_BU_FOBIKsafeENBL "0370FF037FFF0000h";
BA_ "GenSigStartValue" SG_ 1006 VC_BU_FOBIKsafeENBL 1;
BA_ "FlexKomSID" SG_ 1006 VC_BU_FOBIKsafeENBL 921;
BA_ "FlexKomSigStartPos" SG_ 1006 VC_BU_FOBIKsafeENBL 7;
BA_ "FlexKomSigLaenge" SG_ 1006 VC_BU_FOBIKsafeENBL 64;
BA_ "FlexKomSigName" SG_ 1006 VC_BU_FOBIKsafeENBL "VehCfgBu3_Pkt";
BA_ "FlexKomComment" SG_ 1006 VC_BU_FOBIKsafeENBL "Vehicle Configuration Backup 3 Packet";
BA_ "FlexKomIsMotorola" SG_ 1006 VC_BU_FOBIKsafeENBL 1;
BA_ "GenSigSNA" SG_ 1006 VC_BU_FOBIKsafeENBL "1h";
BA_ "GenSigSendType" SG_ 1006 VC_BU_ELV_PRSNT 1;
BA_ "FlexKomSigStartValue" SG_ 1006 VC_BU_ELV_PRSNT "0370FF037FFF0000h";
BA_ "FlexKomSID" SG_ 1006 VC_BU_ELV_PRSNT 921;
BA_ "FlexKomSigStartPos" SG_ 1006 VC_BU_ELV_PRSNT 7;
BA_ "FlexKomSigLaenge" SG_ 1006 VC_BU_ELV_PRSNT 64;
BA_ "FlexKomSigName" SG_ 1006 VC_BU_ELV_PRSNT "VehCfgBu3_Pkt";
BA_ "FlexKomComment" SG_ 1006 VC_BU_ELV_PRSNT "Vehicle Configuration Backup 3 Packet";
BA_ "FlexKomIsMotorola" SG_ 1006 VC_BU_ELV_PRSNT 1;
BA_ "GenSigSNA" SG_ 1006 VC_BU_ELV_PRSNT "0h";
BA_ "GenSigSendType" SG_ 1006 VC_BU_FUEL_CAP 1;
BA_ "FlexKomSigStartValue" SG_ 1006 VC_BU_FUEL_CAP "0370FF037FFF0000h";
BA_ "GenSigStartValue" SG_ 1006 VC_BU_FUEL_CAP 255;
BA_ "FlexKomSID" SG_ 1006 VC_BU_FUEL_CAP 921;
BA_ "FlexKomSigStartPos" SG_ 1006 VC_BU_FUEL_CAP 7;
BA_ "FlexKomSigLaenge" SG_ 1006 VC_BU_FUEL_CAP 64;
BA_ "FlexKomSigName" SG_ 1006 VC_BU_FUEL_CAP "VehCfgBu3_Pkt";
BA_ "FlexKomComment" SG_ 1006 VC_BU_FUEL_CAP "Vehicle Configuration Backup 3 Packet";
BA_ "FlexKomIsMotorola" SG_ 1006 VC_BU_FUEL_CAP 1;
BA_ "GenSigSNA" SG_ 1006 VC_BU_FUEL_CAP "FFh";
BA_ "GenSigSendType" SG_ 1006 VC_BU_WIN_EXPR_FEAT 1;
BA_ "FlexKomSigStartValue" SG_ 1006 VC_BU_WIN_EXPR_FEAT "0370FF037FFF0000h";
BA_ "GenSigStartValue" SG_ 1006 VC_BU_WIN_EXPR_FEAT 3;
BA_ "FlexKomSID" SG_ 1006 VC_BU_WIN_EXPR_FEAT 921;
BA_ "FlexKomSigStartPos" SG_ 1006 VC_BU_WIN_EXPR_FEAT 7;
BA_ "FlexKomSigLaenge" SG_ 1006 VC_BU_WIN_EXPR_FEAT 64;
BA_ "FlexKomSigName" SG_ 1006 VC_BU_WIN_EXPR_FEAT "VehCfgBu3_Pkt";
BA_ "FlexKomComment" SG_ 1006 VC_BU_WIN_EXPR_FEAT "Vehicle Configuration Backup 3 Packet";
BA_ "FlexKomIsMotorola" SG_ 1006 VC_BU_WIN_EXPR_FEAT 1;
BA_ "GenSigSNA" SG_ 1006 VC_BU_WIN_EXPR_FEAT "3h";
BA_ "GenSigSendType" SG_ 1006 VC_BU_ADJ_PDL_PRSNT 1;
BA_ "FlexKomSigStartValue" SG_ 1006 VC_BU_ADJ_PDL_PRSNT "0370FF037FFF0000h";
BA_ "FlexKomSID" SG_ 1006 VC_BU_ADJ_PDL_PRSNT 921;
BA_ "FlexKomSigStartPos" SG_ 1006 VC_BU_ADJ_PDL_PRSNT 7;
BA_ "FlexKomSigLaenge" SG_ 1006 VC_BU_ADJ_PDL_PRSNT 64;
BA_ "FlexKomSigName" SG_ 1006 VC_BU_ADJ_PDL_PRSNT "VehCfgBu3_Pkt";
BA_ "FlexKomComment" SG_ 1006 VC_BU_ADJ_PDL_PRSNT "Vehicle Configuration Backup 3 Packet";
BA_ "FlexKomIsMotorola" SG_ 1006 VC_BU_ADJ_PDL_PRSNT 1;
BA_ "GenSigSNA" SG_ 1006 VC_BU_ADJ_PDL_PRSNT "0h";
BA_ "GenSigSendType" SG_ 1006 VC_BU_AUTO_HL 1;
BA_ "FlexKomSigStartValue" SG_ 1006 VC_BU_AUTO_HL "0370FF037FFF0000h";
BA_ "FlexKomSID" SG_ 1006 VC_BU_AUTO_HL 921;
BA_ "FlexKomSigStartPos" SG_ 1006 VC_BU_AUTO_HL 7;
BA_ "FlexKomSigLaenge" SG_ 1006 VC_BU_AUTO_HL 64;
BA_ "FlexKomSigName" SG_ 1006 VC_BU_AUTO_HL "VehCfgBu3_Pkt";
BA_ "FlexKomComment" SG_ 1006 VC_BU_AUTO_HL "Vehicle Configuration Backup 3 Packet";
BA_ "FlexKomIsMotorola" SG_ 1006 VC_BU_AUTO_HL 1;
BA_ "GenSigSNA" SG_ 1006 VC_BU_AUTO_HL "0h";
BA_ "GenSigSendType" SG_ 1006 VC_BU_DrAlrPrsnt 1;
BA_ "FlexKomSigStartValue" SG_ 1006 VC_BU_DrAlrPrsnt "0370FF037FFF0000h";
BA_ "FlexKomSID" SG_ 1006 VC_BU_DrAlrPrsnt 921;
BA_ "FlexKomSigStartPos" SG_ 1006 VC_BU_DrAlrPrsnt 7;
BA_ "FlexKomSigLaenge" SG_ 1006 VC_BU_DrAlrPrsnt 64;
BA_ "FlexKomSigName" SG_ 1006 VC_BU_DrAlrPrsnt "VehCfgBu3_Pkt";
BA_ "FlexKomComment" SG_ 1006 VC_BU_DrAlrPrsnt "Vehicle Configuration Backup 3 Packet";
BA_ "FlexKomIsMotorola" SG_ 1006 VC_BU_DrAlrPrsnt 1;
BA_ "GenSigSNA" SG_ 1006 VC_BU_DrAlrPrsnt "0h";
BA_ "GenSigSendType" SG_ 1006 VC_BU_DualFuelSens 1;
BA_ "FlexKomSigStartValue" SG_ 1006 VC_BU_DualFuelSens "0370FF037FFF0000h";
BA_ "FlexKomSID" SG_ 1006 VC_BU_DualFuelSens 921;
BA_ "FlexKomSigStartPos" SG_ 1006 VC_BU_DualFuelSens 7;
BA_ "FlexKomSigLaenge" SG_ 1006 VC_BU_DualFuelSens 64;
BA_ "FlexKomSigName" SG_ 1006 VC_BU_DualFuelSens "VehCfgBu3_Pkt";
BA_ "FlexKomComment" SG_ 1006 VC_BU_DualFuelSens "Vehicle Configuration Backup 3 Packet";
BA_ "FlexKomIsMotorola" SG_ 1006 VC_BU_DualFuelSens 1;
BA_ "GenSigSNA" SG_ 1006 VC_BU_DualFuelSens "0h";
BA_ "GenSigSendType" SG_ 1006 VC_BU_SRT_PRSNT 1;
BA_ "FlexKomSigStartValue" SG_ 1006 VC_BU_SRT_PRSNT "0370FF037FFF0000h";
BA_ "FlexKomSID" SG_ 1006 VC_BU_SRT_PRSNT 921;
BA_ "FlexKomSigStartPos" SG_ 1006 VC_BU_SRT_PRSNT 7;
BA_ "FlexKomSigLaenge" SG_ 1006 VC_BU_SRT_PRSNT 64;
BA_ "FlexKomSigName" SG_ 1006 VC_BU_SRT_PRSNT "VehCfgBu3_Pkt";
BA_ "FlexKomComment" SG_ 1006 VC_BU_SRT_PRSNT "Vehicle Configuration Backup 3 Packet";
BA_ "FlexKomIsMotorola" SG_ 1006 VC_BU_SRT_PRSNT 1;
BA_ "GenSigSNA" SG_ 1006 VC_BU_SRT_PRSNT "0h";
BA_ "GenSigSendType" SG_ 1006 VC_BU_DSBL_CLK_DISP 1;
BA_ "FlexKomSigStartValue" SG_ 1006 VC_BU_DSBL_CLK_DISP "0370FF037FFF0000h";
BA_ "FlexKomSID" SG_ 1006 VC_BU_DSBL_CLK_DISP 921;
BA_ "FlexKomSigStartPos" SG_ 1006 VC_BU_DSBL_CLK_DISP 7;
BA_ "FlexKomSigLaenge" SG_ 1006 VC_BU_DSBL_CLK_DISP 64;
BA_ "FlexKomSigName" SG_ 1006 VC_BU_DSBL_CLK_DISP "VehCfgBu3_Pkt";
BA_ "FlexKomComment" SG_ 1006 VC_BU_DSBL_CLK_DISP "Vehicle Configuration Backup 3 Packet";
BA_ "FlexKomIsMotorola" SG_ 1006 VC_BU_DSBL_CLK_DISP 1;
BA_ "GenSigSNA" SG_ 1006 VC_BU_DSBL_CLK_DISP "0h";
BA_ "GenSigSendType" SG_ 1006 VC_BU_ChassisType 1;
BA_ "FlexKomSigStartValue" SG_ 1006 VC_BU_ChassisType "0370FF037FFF0000h";
BA_ "GenSigStartValue" SG_ 1006 VC_BU_ChassisType 127;
BA_ "FlexKomSID" SG_ 1006 VC_BU_ChassisType 921;
BA_ "FlexKomSigStartPos" SG_ 1006 VC_BU_ChassisType 7;
BA_ "FlexKomSigLaenge" SG_ 1006 VC_BU_ChassisType 64;
BA_ "FlexKomSigName" SG_ 1006 VC_BU_ChassisType "VehCfgBu3_Pkt";
BA_ "FlexKomComment" SG_ 1006 VC_BU_ChassisType "Vehicle Configuration Backup 3 Packet";
BA_ "FlexKomIsMotorola" SG_ 1006 VC_BU_ChassisType 1;
BA_ "GenSigSNA" SG_ 1006 VC_BU_ChassisType "7Fh";
BA_ "GenSigSendType" SG_ 1006 VC_BU_TEMP_DISP 1;
BA_ "FlexKomSigStartValue" SG_ 1006 VC_BU_TEMP_DISP "0370FF037FFF0000h";
BA_ "FlexKomSID" SG_ 1006 VC_BU_TEMP_DISP 921;
BA_ "FlexKomSigStartPos" SG_ 1006 VC_BU_TEMP_DISP 7;
BA_ "FlexKomSigLaenge" SG_ 1006 VC_BU_TEMP_DISP 64;
BA_ "FlexKomSigName" SG_ 1006 VC_BU_TEMP_DISP "VehCfgBu3_Pkt";
BA_ "FlexKomComment" SG_ 1006 VC_BU_TEMP_DISP "Vehicle Configuration Backup 3 Packet";
BA_ "FlexKomIsMotorola" SG_ 1006 VC_BU_TEMP_DISP 1;
BA_ "GenSigSNA" SG_ 1006 VC_BU_TEMP_DISP "0h";
BA_ "GenSigSendType" SG_ 1006 VC_BU_HVAC_Config 1;
BA_ "FlexKomSigStartValue" SG_ 1006 VC_BU_HVAC_Config "0370FF037FFF0000h";
BA_ "GenSigStartValue" SG_ 1006 VC_BU_HVAC_Config 15;
BA_ "FlexKomSID" SG_ 1006 VC_BU_HVAC_Config 921;
BA_ "FlexKomSigStartPos" SG_ 1006 VC_BU_HVAC_Config 7;
BA_ "FlexKomSigLaenge" SG_ 1006 VC_BU_HVAC_Config 64;
BA_ "FlexKomSigName" SG_ 1006 VC_BU_HVAC_Config "VehCfgBu3_Pkt";
BA_ "FlexKomComment" SG_ 1006 VC_BU_HVAC_Config "Vehicle Configuration Backup 3 Packet";
BA_ "FlexKomIsMotorola" SG_ 1006 VC_BU_HVAC_Config 1;
BA_ "GenSigSNA" SG_ 1006 VC_BU_HVAC_Config "Fh";
BA_ "GenSigSendType" SG_ 1006 VC_BU_VEH_BRAND 1;
BA_ "FlexKomSigStartValue" SG_ 1006 VC_BU_VEH_BRAND "0370FF037FFF0000h";
BA_ "GenSigStartValue" SG_ 1006 VC_BU_VEH_BRAND 15;
BA_ "FlexKomSID" SG_ 1006 VC_BU_VEH_BRAND 921;
BA_ "FlexKomSigStartPos" SG_ 1006 VC_BU_VEH_BRAND 7;
BA_ "FlexKomSigLaenge" SG_ 1006 VC_BU_VEH_BRAND 64;
BA_ "FlexKomSigName" SG_ 1006 VC_BU_VEH_BRAND "VehCfgBu3_Pkt";
BA_ "FlexKomComment" SG_ 1006 VC_BU_VEH_BRAND "Vehicle Configuration Backup 3 Packet";
BA_ "FlexKomIsMotorola" SG_ 1006 VC_BU_VEH_BRAND 1;
BA_ "GenSigSNA" SG_ 1006 VC_BU_VEH_BRAND "Fh";
BA_ "GenSigSendType" SG_ 1006 VC_BU_CMP_DISP 1;
BA_ "FlexKomSigStartValue" SG_ 1006 VC_BU_CMP_DISP "0370FF037FFF0000h";
BA_ "FlexKomSID" SG_ 1006 VC_BU_CMP_DISP 921;
BA_ "FlexKomSigStartPos" SG_ 1006 VC_BU_CMP_DISP 7;
BA_ "FlexKomSigLaenge" SG_ 1006 VC_BU_CMP_DISP 64;
BA_ "FlexKomSigName" SG_ 1006 VC_BU_CMP_DISP "VehCfgBu3_Pkt";
BA_ "FlexKomComment" SG_ 1006 VC_BU_CMP_DISP "Vehicle Configuration Backup 3 Packet";
BA_ "FlexKomIsMotorola" SG_ 1006 VC_BU_CMP_DISP 1;
BA_ "GenSigSNA" SG_ 1006 VC_BU_CMP_DISP "0h";
BA_ "GenSigSendType" SG_ 1006 VC_BU_IntEC_MIRR 1;
BA_ "FlexKomSigStartValue" SG_ 1006 VC_BU_IntEC_MIRR "0370FF037FFF0000h";
BA_ "FlexKomSID" SG_ 1006 VC_BU_IntEC_MIRR 921;
BA_ "FlexKomSigStartPos" SG_ 1006 VC_BU_IntEC_MIRR 7;
BA_ "FlexKomSigLaenge" SG_ 1006 VC_BU_IntEC_MIRR 64;
BA_ "FlexKomSigName" SG_ 1006 VC_BU_IntEC_MIRR "VehCfgBu3_Pkt";
BA_ "FlexKomComment" SG_ 1006 VC_BU_IntEC_MIRR "Vehicle Configuration Backup 3 Packet";
BA_ "FlexKomIsMotorola" SG_ 1006 VC_BU_IntEC_MIRR 1;
BA_ "GenSigSNA" SG_ 1006 VC_BU_IntEC_MIRR "0h";
BA_ "GenSigSendType" SG_ 1006 VC_BU_ESCL_Prsnt 1;
BA_ "FlexKomSigStartValue" SG_ 1006 VC_BU_ESCL_Prsnt "0370FF037FFF0000h";
BA_ "FlexKomSID" SG_ 1006 VC_BU_ESCL_Prsnt 921;
BA_ "FlexKomSigStartPos" SG_ 1006 VC_BU_ESCL_Prsnt 7;
BA_ "FlexKomSigLaenge" SG_ 1006 VC_BU_ESCL_Prsnt 64;
BA_ "FlexKomSigName" SG_ 1006 VC_BU_ESCL_Prsnt "VehCfgBu3_Pkt";
BA_ "FlexKomComment" SG_ 1006 VC_BU_ESCL_Prsnt "Vehicle Configuration Backup 3 Packet";
BA_ "FlexKomIsMotorola" SG_ 1006 VC_BU_ESCL_Prsnt 1;
BA_ "GenSigSNA" SG_ 1006 VC_BU_ESCL_Prsnt "0h";
BA_ "GenSigSendType" SG_ 1006 VC_BU_HID_HL 1;
BA_ "FlexKomSigStartValue" SG_ 1006 VC_BU_HID_HL "0370FF037FFF0000h";
BA_ "FlexKomSID" SG_ 1006 VC_BU_HID_HL 921;
BA_ "FlexKomSigStartPos" SG_ 1006 VC_BU_HID_HL 7;
BA_ "FlexKomSigLaenge" SG_ 1006 VC_BU_HID_HL 64;
BA_ "FlexKomSigName" SG_ 1006 VC_BU_HID_HL "VehCfgBu3_Pkt";
BA_ "FlexKomComment" SG_ 1006 VC_BU_HID_HL "Vehicle Configuration Backup 3 Packet";
BA_ "FlexKomIsMotorola" SG_ 1006 VC_BU_HID_HL 1;
BA_ "GenSigSNA" SG_ 1006 VC_BU_HID_HL "0h";
BA_ "GenSigSendType" SG_ 1006 VC_BU_SecLkPrsnt 1;
BA_ "FlexKomSigStartValue" SG_ 1006 VC_BU_SecLkPrsnt "0370FF037FFF0000h";
BA_ "FlexKomSID" SG_ 1006 VC_BU_SecLkPrsnt 921;
BA_ "FlexKomSigStartPos" SG_ 1006 VC_BU_SecLkPrsnt 7;
BA_ "FlexKomSigLaenge" SG_ 1006 VC_BU_SecLkPrsnt 64;
BA_ "FlexKomSigName" SG_ 1006 VC_BU_SecLkPrsnt "VehCfgBu3_Pkt";
BA_ "FlexKomComment" SG_ 1006 VC_BU_SecLkPrsnt "Vehicle Configuration Backup 3 Packet";
BA_ "FlexKomIsMotorola" SG_ 1006 VC_BU_SecLkPrsnt 1;
BA_ "GenSigSNA" SG_ 1006 VC_BU_SecLkPrsnt "0h";
BA_ "GenSigSendType" SG_ 1006 VC_BU_Liftgate_Trunk 1;
BA_ "FlexKomSigStartValue" SG_ 1006 VC_BU_Liftgate_Trunk "0370FF037FFF0000h";
BA_ "FlexKomSID" SG_ 1006 VC_BU_Liftgate_Trunk 921;
BA_ "FlexKomSigStartPos" SG_ 1006 VC_BU_Liftgate_Trunk 7;
BA_ "FlexKomSigLaenge" SG_ 1006 VC_BU_Liftgate_Trunk 64;
BA_ "FlexKomSigName" SG_ 1006 VC_BU_Liftgate_Trunk "VehCfgBu3_Pkt";
BA_ "FlexKomComment" SG_ 1006 VC_BU_Liftgate_Trunk "Vehicle Configuration Backup 3 Packet";
BA_ "FlexKomIsMotorola" SG_ 1006 VC_BU_Liftgate_Trunk 1;
BA_ "GenSigSNA" SG_ 1006 VC_BU_Liftgate_Trunk "3h";
BA_ "GenSigSendType" SG_ 1006 VC_BU_CMS 1;
BA_ "FlexKomSigStartValue" SG_ 1006 VC_BU_CMS "0370FF037FFF0000h";
BA_ "FlexKomSID" SG_ 1006 VC_BU_CMS 921;
BA_ "FlexKomSigStartPos" SG_ 1006 VC_BU_CMS 7;
BA_ "FlexKomSigLaenge" SG_ 1006 VC_BU_CMS 64;
BA_ "FlexKomSigName" SG_ 1006 VC_BU_CMS "VehCfgBu3_Pkt";
BA_ "FlexKomComment" SG_ 1006 VC_BU_CMS "Vehicle Configuration Backup 3 Packet";
BA_ "FlexKomIsMotorola" SG_ 1006 VC_BU_CMS 1;
BA_ "GenSigSNA" SG_ 1006 VC_BU_CMS "0h";
BA_ "GenSigSendType" SG_ 1006 VC_BU_FCW 1;
BA_ "FlexKomSigStartValue" SG_ 1006 VC_BU_FCW "0370FF037FFF0000h";
BA_ "FlexKomSID" SG_ 1006 VC_BU_FCW 921;
BA_ "FlexKomSigStartPos" SG_ 1006 VC_BU_FCW 7;
BA_ "FlexKomSigLaenge" SG_ 1006 VC_BU_FCW 64;
BA_ "FlexKomSigName" SG_ 1006 VC_BU_FCW "VehCfgBu3_Pkt";
BA_ "FlexKomComment" SG_ 1006 VC_BU_FCW "Vehicle Configuration Backup 3 Packet";
BA_ "FlexKomIsMotorola" SG_ 1006 VC_BU_FCW 1;
BA_ "GenSigSNA" SG_ 1006 VC_BU_FCW "0h";
BA_ "GenSigSendType" SG_ 1006 VC_BU_Base_TPM 1;
BA_ "FlexKomSigStartValue" SG_ 1006 VC_BU_Base_TPM "0370FF037FFF0000h";
BA_ "FlexKomSID" SG_ 1006 VC_BU_Base_TPM 921;
BA_ "FlexKomSigStartPos" SG_ 1006 VC_BU_Base_TPM 7;
BA_ "FlexKomSigLaenge" SG_ 1006 VC_BU_Base_TPM 64;
BA_ "FlexKomSigName" SG_ 1006 VC_BU_Base_TPM "VehCfgBu3_Pkt";
BA_ "FlexKomComment" SG_ 1006 VC_BU_Base_TPM "Vehicle Configuration Backup 3 Packet";
BA_ "FlexKomIsMotorola" SG_ 1006 VC_BU_Base_TPM 1;
BA_ "GenSigSNA" SG_ 1006 VC_BU_Base_TPM "0h";
BA_ "GenSigSendType" SG_ 1006 VC_BU_Prem_TPM 1;
BA_ "FlexKomSigStartValue" SG_ 1006 VC_BU_Prem_TPM "0370FF037FFF0000h";
BA_ "FlexKomSID" SG_ 1006 VC_BU_Prem_TPM 921;
BA_ "FlexKomSigStartPos" SG_ 1006 VC_BU_Prem_TPM 7;
BA_ "FlexKomSigLaenge" SG_ 1006 VC_BU_Prem_TPM 64;
BA_ "FlexKomSigName" SG_ 1006 VC_BU_Prem_TPM "VehCfgBu3_Pkt";
BA_ "FlexKomComment" SG_ 1006 VC_BU_Prem_TPM "Vehicle Configuration Backup 3 Packet";
BA_ "FlexKomIsMotorola" SG_ 1006 VC_BU_Prem_TPM 1;
BA_ "GenSigSNA" SG_ 1006 VC_BU_Prem_TPM "0h";
BA_ "GenSigSendType" SG_ 1006 VC_BU_PDDL_PRSNT 1;
BA_ "FlexKomSigStartValue" SG_ 1006 VC_BU_PDDL_PRSNT "0370FF037FFF0000h";
BA_ "FlexKomSID" SG_ 1006 VC_BU_PDDL_PRSNT 921;
BA_ "FlexKomSigStartPos" SG_ 1006 VC_BU_PDDL_PRSNT 7;
BA_ "FlexKomSigLaenge" SG_ 1006 VC_BU_PDDL_PRSNT 64;
BA_ "FlexKomSigName" SG_ 1006 VC_BU_PDDL_PRSNT "VehCfgBu3_Pkt";
BA_ "FlexKomComment" SG_ 1006 VC_BU_PDDL_PRSNT "Vehicle Configuration Backup 3 Packet";
BA_ "FlexKomIsMotorola" SG_ 1006 VC_BU_PDDL_PRSNT 1;
BA_ "GenSigSNA" SG_ 1006 VC_BU_PDDL_PRSNT "0h";
BA_ "GenSigSendType" SG_ 1006 VC_BU_SPORT_PRSNT 1;
BA_ "FlexKomSigStartValue" SG_ 1006 VC_BU_SPORT_PRSNT "0370FF037FFF0000h";
BA_ "FlexKomSID" SG_ 1006 VC_BU_SPORT_PRSNT 921;
BA_ "FlexKomSigStartPos" SG_ 1006 VC_BU_SPORT_PRSNT 7;
BA_ "FlexKomSigLaenge" SG_ 1006 VC_BU_SPORT_PRSNT 64;
BA_ "FlexKomSigName" SG_ 1006 VC_BU_SPORT_PRSNT "VehCfgBu3_Pkt";
BA_ "FlexKomComment" SG_ 1006 VC_BU_SPORT_PRSNT "Vehicle Configuration Backup 3 Packet";
BA_ "FlexKomIsMotorola" SG_ 1006 VC_BU_SPORT_PRSNT 1;
BA_ "GenSigSNA" SG_ 1006 VC_BU_SPORT_PRSNT "0h";
BA_ "GenSigSendType" SG_ 1006 VC_BU_AutoParkPrsnt 1;
BA_ "FlexKomSigStartValue" SG_ 1006 VC_BU_AutoParkPrsnt "0370FF037FFF0000h";
BA_ "FlexKomSID" SG_ 1006 VC_BU_AutoParkPrsnt 921;
BA_ "FlexKomSigStartPos" SG_ 1006 VC_BU_AutoParkPrsnt 7;
BA_ "FlexKomSigLaenge" SG_ 1006 VC_BU_AutoParkPrsnt 64;
BA_ "FlexKomSigName" SG_ 1006 VC_BU_AutoParkPrsnt "VehCfgBu3_Pkt";
BA_ "FlexKomComment" SG_ 1006 VC_BU_AutoParkPrsnt "Vehicle Configuration Backup 3 Packet";
BA_ "FlexKomIsMotorola" SG_ 1006 VC_BU_AutoParkPrsnt 1;
BA_ "GenSigSNA" SG_ 1006 VC_BU_AutoParkPrsnt "0h";
BA_ "GenSigSendType" SG_ 1006 VC_BU_PE_Prsnt 1;
BA_ "FlexKomSigStartValue" SG_ 1006 VC_BU_PE_Prsnt "0370FF037FFF0000h";
BA_ "FlexKomSID" SG_ 1006 VC_BU_PE_Prsnt 921;
BA_ "FlexKomSigStartPos" SG_ 1006 VC_BU_PE_Prsnt 7;
BA_ "FlexKomSigLaenge" SG_ 1006 VC_BU_PE_Prsnt 64;
BA_ "FlexKomSigName" SG_ 1006 VC_BU_PE_Prsnt "VehCfgBu3_Pkt";
BA_ "FlexKomComment" SG_ 1006 VC_BU_PE_Prsnt "Vehicle Configuration Backup 3 Packet";
BA_ "FlexKomIsMotorola" SG_ 1006 VC_BU_PE_Prsnt 1;
BA_ "GenSigSNA" SG_ 1006 VC_BU_PE_Prsnt "0h";
BA_ "GenSigSendType" SG_ 1006 VC_BU_KG_Prsnt 1;
BA_ "FlexKomSigStartValue" SG_ 1006 VC_BU_KG_Prsnt "0370FF037FFF0000h";
BA_ "FlexKomSID" SG_ 1006 VC_BU_KG_Prsnt 921;
BA_ "FlexKomSigStartPos" SG_ 1006 VC_BU_KG_Prsnt 7;
BA_ "FlexKomSigLaenge" SG_ 1006 VC_BU_KG_Prsnt 64;
BA_ "FlexKomSigName" SG_ 1006 VC_BU_KG_Prsnt "VehCfgBu3_Pkt";
BA_ "FlexKomComment" SG_ 1006 VC_BU_KG_Prsnt "Vehicle Configuration Backup 3 Packet";
BA_ "FlexKomIsMotorola" SG_ 1006 VC_BU_KG_Prsnt 1;
BA_ "GenSigSNA" SG_ 1006 VC_BU_KG_Prsnt "0h";
BA_ "GenSigSendType" SG_ 1007 VC_BU_TCASE_HI_RATIO 1;
BA_ "FlexKomSigStartValue" SG_ 1007 VC_BU_TCASE_HI_RATIO "FFFFFFFFFFFFFFFFh";
BA_ "GenSigStartValue" SG_ 1007 VC_BU_TCASE_HI_RATIO 16383;
BA_ "FlexKomSID" SG_ 1007 VC_BU_TCASE_HI_RATIO 1036;
BA_ "FlexKomSigStartPos" SG_ 1007 VC_BU_TCASE_HI_RATIO 7;
BA_ "FlexKomSigLaenge" SG_ 1007 VC_BU_TCASE_HI_RATIO 64;
BA_ "FlexKomSigName" SG_ 1007 VC_BU_TCASE_HI_RATIO "VehCfgBu4_Pkt";
BA_ "FlexKomComment" SG_ 1007 VC_BU_TCASE_HI_RATIO "Vehicle Configuration Backup 4 Packet";
BA_ "FlexKomIsMotorola" SG_ 1007 VC_BU_TCASE_HI_RATIO 1;
BA_ "GenSigSNA" SG_ 1007 VC_BU_TCASE_HI_RATIO "3FFFh";
BA_ "GenSigSendType" SG_ 1007 VC_BU_VehCfg4_Stat 1;
BA_ "FlexKomSigStartValue" SG_ 1007 VC_BU_VehCfg4_Stat "FFFFFFFFFFFFFFFFh";
BA_ "GenSigStartValue" SG_ 1007 VC_BU_VehCfg4_Stat 3;
BA_ "FlexKomSID" SG_ 1007 VC_BU_VehCfg4_Stat 1036;
BA_ "FlexKomSigStartPos" SG_ 1007 VC_BU_VehCfg4_Stat 7;
BA_ "FlexKomSigLaenge" SG_ 1007 VC_BU_VehCfg4_Stat 64;
BA_ "FlexKomSigName" SG_ 1007 VC_BU_VehCfg4_Stat "VehCfgBu4_Pkt";
BA_ "FlexKomComment" SG_ 1007 VC_BU_VehCfg4_Stat "Vehicle Configuration Backup 4 Packet";
BA_ "FlexKomIsMotorola" SG_ 1007 VC_BU_VehCfg4_Stat 1;
BA_ "GenSigSNA" SG_ 1007 VC_BU_VehCfg4_Stat "3h";
BA_ "GenSigSendType" SG_ 1007 VC_BU_AXLE_RATIO 1;
BA_ "FlexKomSigStartValue" SG_ 1007 VC_BU_AXLE_RATIO "FFFFFFFFFFFFFFFFh";
BA_ "GenSigStartValue" SG_ 1007 VC_BU_AXLE_RATIO 65535;
BA_ "FlexKomSID" SG_ 1007 VC_BU_AXLE_RATIO 1036;
BA_ "FlexKomSigStartPos" SG_ 1007 VC_BU_AXLE_RATIO 7;
BA_ "FlexKomSigLaenge" SG_ 1007 VC_BU_AXLE_RATIO 64;
BA_ "FlexKomSigName" SG_ 1007 VC_BU_AXLE_RATIO "VehCfgBu4_Pkt";
BA_ "FlexKomComment" SG_ 1007 VC_BU_AXLE_RATIO "Vehicle Configuration Backup 4 Packet";
BA_ "FlexKomIsMotorola" SG_ 1007 VC_BU_AXLE_RATIO 1;
BA_ "GenSigSNA" SG_ 1007 VC_BU_AXLE_RATIO "FFFFh";
BA_ "GenSigSendType" SG_ 1007 VC_BU_TCASE_LO_RATIO 1;
BA_ "FlexKomSigStartValue" SG_ 1007 VC_BU_TCASE_LO_RATIO "FFFFFFFFFFFFFFFFh";
BA_ "GenSigStartValue" SG_ 1007 VC_BU_TCASE_LO_RATIO 65535;
BA_ "FlexKomSID" SG_ 1007 VC_BU_TCASE_LO_RATIO 1036;
BA_ "FlexKomSigStartPos" SG_ 1007 VC_BU_TCASE_LO_RATIO 7;
BA_ "FlexKomSigLaenge" SG_ 1007 VC_BU_TCASE_LO_RATIO 64;
BA_ "FlexKomSigName" SG_ 1007 VC_BU_TCASE_LO_RATIO "VehCfgBu4_Pkt";
BA_ "FlexKomComment" SG_ 1007 VC_BU_TCASE_LO_RATIO "Vehicle Configuration Backup 4 Packet";
BA_ "FlexKomIsMotorola" SG_ 1007 VC_BU_TCASE_LO_RATIO 1;
BA_ "GenSigSNA" SG_ 1007 VC_BU_TCASE_LO_RATIO "FFFFh";
BA_ "GenSigSendType" SG_ 1007 VC_BU_TIRE_CIRCUMF 1;
BA_ "FlexKomSigStartValue" SG_ 1007 VC_BU_TIRE_CIRCUMF "FFFFFFFFFFFFFFFFh";
BA_ "GenSigStartValue" SG_ 1007 VC_BU_TIRE_CIRCUMF 65535;
BA_ "FlexKomSID" SG_ 1007 VC_BU_TIRE_CIRCUMF 1036;
BA_ "FlexKomSigStartPos" SG_ 1007 VC_BU_TIRE_CIRCUMF 7;
BA_ "FlexKomSigLaenge" SG_ 1007 VC_BU_TIRE_CIRCUMF 64;
BA_ "FlexKomSigName" SG_ 1007 VC_BU_TIRE_CIRCUMF "VehCfgBu4_Pkt";
BA_ "FlexKomComment" SG_ 1007 VC_BU_TIRE_CIRCUMF "Vehicle Configuration Backup 4 Packet";
BA_ "FlexKomIsMotorola" SG_ 1007 VC_BU_TIRE_CIRCUMF 1;
BA_ "GenSigSNA" SG_ 1007 VC_BU_TIRE_CIRCUMF "FFFFh";
BA_ "GenSigCycleTime" SG_ 1008 EC_ECUCfg1_Stat 2000;
BA_ "FlexKomSigStartValue" SG_ 1008 EC_ECUCfg1_Stat "03h";
BA_ "GenSigStartValue" SG_ 1008 EC_ECUCfg1_Stat 3;
BA_ "FlexKomSID" SG_ 1008 EC_ECUCfg1_Stat 1058;
BA_ "FlexKomSigStartPos" SG_ 1008 EC_ECUCfg1_Stat 1;
BA_ "FlexKomSigLaenge" SG_ 1008 EC_ECUCfg1_Stat 2;
BA_ "FlexKomSigName" SG_ 1008 EC_ECUCfg1_Stat "EC_ECUCfg1_Stat";
BA_ "FlexKomComment" SG_ 1008 EC_ECUCfg1_Stat "ECU Configuration messages status 1";
BA_ "FlexKomIsMotorola" SG_ 1008 EC_ECUCfg1_Stat 1;
BA_ "GenSigSNA" SG_ 1008 EC_ECUCfg1_Stat "3h";
BA_ "GenSigCycleTime" SG_ 1008 EC_CBC1A 2000;
BA_ "FlexKomSigStartValue" SG_ 1008 EC_CBC1A "00000000h";
BA_ "FlexKomSID" SG_ 1008 EC_CBC1A 899;
BA_ "FlexKomSigStartPos" SG_ 1008 EC_CBC1A 7;
BA_ "FlexKomSigLaenge" SG_ 1008 EC_CBC1A 32;
BA_ "FlexKomSigName" SG_ 1008 EC_CBC1A "EC_CBC1";
BA_ "FlexKomComment" SG_ 1008 EC_CBC1A "CBC ecu configuration 1";
BA_ "FlexKomIsMotorola" SG_ 1008 EC_CBC1A 1;
BA_ "GenSigSNA" SG_ 1008 EC_CBC1A "0h";
BA_ "GenSigCycleTime" SG_ 1008 EC_CBC1B 2000;
BA_ "FlexKomSigStartValue" SG_ 1008 EC_CBC1B "00000000h";
BA_ "FlexKomSID" SG_ 1008 EC_CBC1B 899;
BA_ "FlexKomSigStartPos" SG_ 1008 EC_CBC1B 7;
BA_ "FlexKomSigLaenge" SG_ 1008 EC_CBC1B 32;
BA_ "FlexKomSigName" SG_ 1008 EC_CBC1B "EC_CBC1";
BA_ "FlexKomComment" SG_ 1008 EC_CBC1B "CBC ecu configuration 1";
BA_ "FlexKomIsMotorola" SG_ 1008 EC_CBC1B 1;
BA_ "GenSigSNA" SG_ 1008 EC_CBC1B "0h";
BA_ "GenSigCycleTime" SG_ 1008 EC_CBC2 2000;
BA_ "FlexKomSigStartValue" SG_ 1008 EC_CBC2 "00000000h";
BA_ "FlexKomSID" SG_ 1008 EC_CBC2 900;
BA_ "FlexKomSigStartPos" SG_ 1008 EC_CBC2 39;
BA_ "FlexKomSigLaenge" SG_ 1008 EC_CBC2 32;
BA_ "FlexKomSigName" SG_ 1008 EC_CBC2 "EC_CBC2";
BA_ "FlexKomComment" SG_ 1008 EC_CBC2 "CBC ecu configuration 2";
BA_ "FlexKomIsMotorola" SG_ 1008 EC_CBC2 1;
BA_ "GenSigSNA" SG_ 1008 EC_CBC2 "0h";
BA_ "GenSigCycleTime" SG_ 1009 EC_ECUCfg2_Stat 2000;
BA_ "FlexKomSigStartValue" SG_ 1009 EC_ECUCfg2_Stat "03h";
BA_ "GenSigStartValue" SG_ 1009 EC_ECUCfg2_Stat 3;
BA_ "FlexKomSID" SG_ 1009 EC_ECUCfg2_Stat 1059;
BA_ "FlexKomSigStartPos" SG_ 1009 EC_ECUCfg2_Stat 1;
BA_ "FlexKomSigLaenge" SG_ 1009 EC_ECUCfg2_Stat 2;
BA_ "FlexKomSigName" SG_ 1009 EC_ECUCfg2_Stat "EC_ECUCfg2_Stat";
BA_ "FlexKomComment" SG_ 1009 EC_ECUCfg2_Stat "ECU Configuration messages status 2";
BA_ "FlexKomIsMotorola" SG_ 1009 EC_ECUCfg2_Stat 1;
BA_ "GenSigSNA" SG_ 1009 EC_ECUCfg2_Stat "3h";
BA_ "GenSigCycleTime" SG_ 1009 EC_CBC3A 2000;
BA_ "FlexKomSigStartValue" SG_ 1009 EC_CBC3A "00000000h";
BA_ "FlexKomSID" SG_ 1009 EC_CBC3A 901;
BA_ "FlexKomSigStartPos" SG_ 1009 EC_CBC3A 7;
BA_ "FlexKomSigLaenge" SG_ 1009 EC_CBC3A 32;
BA_ "FlexKomSigName" SG_ 1009 EC_CBC3A "EC_CBC3";
BA_ "FlexKomComment" SG_ 1009 EC_CBC3A "CBC ecu configuration 3";
BA_ "FlexKomIsMotorola" SG_ 1009 EC_CBC3A 1;
BA_ "GenSigSNA" SG_ 1009 EC_CBC3A "0h";
BA_ "GenSigCycleTime" SG_ 1009 EC_CBC3B 2000;
BA_ "FlexKomSigStartValue" SG_ 1009 EC_CBC3B "00000000h";
BA_ "FlexKomSID" SG_ 1009 EC_CBC3B 901;
BA_ "FlexKomSigStartPos" SG_ 1009 EC_CBC3B 7;
BA_ "FlexKomSigLaenge" SG_ 1009 EC_CBC3B 32;
BA_ "FlexKomSigName" SG_ 1009 EC_CBC3B "EC_CBC3";
BA_ "FlexKomComment" SG_ 1009 EC_CBC3B "CBC ecu configuration 3";
BA_ "FlexKomIsMotorola" SG_ 1009 EC_CBC3B 1;
BA_ "GenSigSNA" SG_ 1009 EC_CBC3B "0h";
BA_ "GenSigCycleTime" SG_ 1009 EC_CBC4 2000;
BA_ "FlexKomSigStartValue" SG_ 1009 EC_CBC4 "00000000h";
BA_ "FlexKomSID" SG_ 1009 EC_CBC4 902;
BA_ "FlexKomSigStartPos" SG_ 1009 EC_CBC4 39;
BA_ "FlexKomSigLaenge" SG_ 1009 EC_CBC4 32;
BA_ "FlexKomSigName" SG_ 1009 EC_CBC4 "EC_CBC4";
BA_ "FlexKomComment" SG_ 1009 EC_CBC4 "CBC ecu configuration 4";
BA_ "FlexKomIsMotorola" SG_ 1009 EC_CBC4 1;
BA_ "GenSigSNA" SG_ 1009 EC_CBC4 "0h";
BA_ "GenSigSendType" SG_ 1010 EC_ECUCfg3_Stat 5;
BA_ "GenSigCycleTime" SG_ 1010 EC_ECUCfg3_Stat 2000;
BA_ "FlexKomSigStartValue" SG_ 1010 EC_ECUCfg3_Stat "03h";
BA_ "GenSigStartValue" SG_ 1010 EC_ECUCfg3_Stat 3;
BA_ "FlexKomSID" SG_ 1010 EC_ECUCfg3_Stat 1060;
BA_ "FlexKomSigStartPos" SG_ 1010 EC_ECUCfg3_Stat 1;
BA_ "FlexKomSigLaenge" SG_ 1010 EC_ECUCfg3_Stat 2;
BA_ "FlexKomSigName" SG_ 1010 EC_ECUCfg3_Stat "EC_ECUCfg3_Stat";
BA_ "FlexKomComment" SG_ 1010 EC_ECUCfg3_Stat "ECU Configuration messages status 3";
BA_ "FlexKomIsMotorola" SG_ 1010 EC_ECUCfg3_Stat 1;
BA_ "GenSigSNA" SG_ 1010 EC_ECUCfg3_Stat "3h";
BA_ "GenSigSendType" SG_ 1010 EC_AudTel1A 5;
BA_ "GenSigCycleTime" SG_ 1010 EC_AudTel1A 2000;
BA_ "FlexKomSigStartValue" SG_ 1010 EC_AudTel1A "00000000h";
BA_ "FlexKomSID" SG_ 1010 EC_AudTel1A 897;
BA_ "FlexKomSigStartPos" SG_ 1010 EC_AudTel1A 7;
BA_ "FlexKomSigLaenge" SG_ 1010 EC_AudTel1A 32;
BA_ "FlexKomSigName" SG_ 1010 EC_AudTel1A "EC_AudTel1";
BA_ "FlexKomComment" SG_ 1010 EC_AudTel1A "Audio and telematics ecu configuration 1";
BA_ "FlexKomIsMotorola" SG_ 1010 EC_AudTel1A 1;
BA_ "GenSigSNA" SG_ 1010 EC_AudTel1A "0h";
BA_ "GenSigSendType" SG_ 1010 EC_AudTel1B 5;
BA_ "GenSigCycleTime" SG_ 1010 EC_AudTel1B 2000;
BA_ "FlexKomSigStartValue" SG_ 1010 EC_AudTel1B "00000000h";
BA_ "FlexKomSID" SG_ 1010 EC_AudTel1B 897;
BA_ "FlexKomSigStartPos" SG_ 1010 EC_AudTel1B 7;
BA_ "FlexKomSigLaenge" SG_ 1010 EC_AudTel1B 32;
BA_ "FlexKomSigName" SG_ 1010 EC_AudTel1B "EC_AudTel1";
BA_ "FlexKomComment" SG_ 1010 EC_AudTel1B "Audio and telematics ecu configuration 1";
BA_ "FlexKomIsMotorola" SG_ 1010 EC_AudTel1B 1;
BA_ "GenSigSNA" SG_ 1010 EC_AudTel1B "0h";
BA_ "GenSigSendType" SG_ 1010 EC_AudTel2 5;
BA_ "GenSigCycleTime" SG_ 1010 EC_AudTel2 2000;
BA_ "FlexKomSigStartValue" SG_ 1010 EC_AudTel2 "00000000h";
BA_ "FlexKomSID" SG_ 1010 EC_AudTel2 898;
BA_ "FlexKomSigStartPos" SG_ 1010 EC_AudTel2 39;
BA_ "FlexKomSigLaenge" SG_ 1010 EC_AudTel2 32;
BA_ "FlexKomSigName" SG_ 1010 EC_AudTel2 "EC_AudTel2";
BA_ "FlexKomComment" SG_ 1010 EC_AudTel2 "Audio and telematics ecu configuration 2";
BA_ "FlexKomIsMotorola" SG_ 1010 EC_AudTel2 1;
BA_ "GenSigSNA" SG_ 1010 EC_AudTel2 "0h";
BA_ "GenSigSendType" SG_ 1011 EC_ECUCfg4_Stat 5;
BA_ "GenSigCycleTime" SG_ 1011 EC_ECUCfg4_Stat 2000;
BA_ "FlexKomSigStartValue" SG_ 1011 EC_ECUCfg4_Stat "03h";
BA_ "GenSigStartValue" SG_ 1011 EC_ECUCfg4_Stat 3;
BA_ "GenSigTimeout_IC" SG_ 1011 EC_ECUCfg4_Stat 21000;
BA_ "FlexKomSID" SG_ 1011 EC_ECUCfg4_Stat 1061;
BA_ "FlexKomSigStartPos" SG_ 1011 EC_ECUCfg4_Stat 1;
BA_ "FlexKomSigLaenge" SG_ 1011 EC_ECUCfg4_Stat 2;
BA_ "FlexKomSigName" SG_ 1011 EC_ECUCfg4_Stat "EC_ECUCfg4_Stat";
BA_ "FlexKomComment" SG_ 1011 EC_ECUCfg4_Stat "ECU Configuration messages status 4";
BA_ "FlexKomIsMotorola" SG_ 1011 EC_ECUCfg4_Stat 1;
BA_ "GenSigSNA" SG_ 1011 EC_ECUCfg4_Stat "3h";
BA_ "GenSigSendType" SG_ 1011 EC_Cluster1A 5;
BA_ "GenSigCycleTime" SG_ 1011 EC_Cluster1A 2000;
BA_ "FlexKomSigStartValue" SG_ 1011 EC_Cluster1A "00000000h";
BA_ "GenSigTimeout_IC" SG_ 1011 EC_Cluster1A 21000;
BA_ "FlexKomSID" SG_ 1011 EC_Cluster1A 896;
BA_ "FlexKomSigStartPos" SG_ 1011 EC_Cluster1A 7;
BA_ "FlexKomSigLaenge" SG_ 1011 EC_Cluster1A 32;
BA_ "FlexKomSigName" SG_ 1011 EC_Cluster1A "EC_Cluster1";
BA_ "FlexKomComment" SG_ 1011 EC_Cluster1A "Instrument cluster ecu configuration 1";
BA_ "FlexKomIsMotorola" SG_ 1011 EC_Cluster1A 1;
BA_ "GenSigSNA" SG_ 1011 EC_Cluster1A "0h";
BA_ "GenSigSendType" SG_ 1011 EC_Cluster1B 5;
BA_ "GenSigCycleTime" SG_ 1011 EC_Cluster1B 2000;
BA_ "FlexKomSigStartValue" SG_ 1011 EC_Cluster1B "00000000h";
BA_ "GenSigTimeout_IC" SG_ 1011 EC_Cluster1B 21000;
BA_ "FlexKomSID" SG_ 1011 EC_Cluster1B 896;
BA_ "FlexKomSigStartPos" SG_ 1011 EC_Cluster1B 7;
BA_ "FlexKomSigLaenge" SG_ 1011 EC_Cluster1B 32;
BA_ "FlexKomSigName" SG_ 1011 EC_Cluster1B "EC_Cluster1";
BA_ "FlexKomComment" SG_ 1011 EC_Cluster1B "Instrument cluster ecu configuration 1";
BA_ "FlexKomIsMotorola" SG_ 1011 EC_Cluster1B 1;
BA_ "GenSigSNA" SG_ 1011 EC_Cluster1B "0h";
BA_ "GenSigSendType" SG_ 1011 EC_Cluster2 5;
BA_ "GenSigCycleTime" SG_ 1011 EC_Cluster2 2000;
BA_ "FlexKomSigStartValue" SG_ 1011 EC_Cluster2 "00000000h";
BA_ "GenSigTimeout_IC" SG_ 1011 EC_Cluster2 21000;
BA_ "FlexKomSID" SG_ 1011 EC_Cluster2 903;
BA_ "FlexKomSigStartPos" SG_ 1011 EC_Cluster2 39;
BA_ "FlexKomSigLaenge" SG_ 1011 EC_Cluster2 32;
BA_ "FlexKomSigName" SG_ 1011 EC_Cluster2 "EC_Cluster2";
BA_ "FlexKomComment" SG_ 1011 EC_Cluster2 "Instrument cluster ecu configuration 2";
BA_ "FlexKomIsMotorola" SG_ 1011 EC_Cluster2 1;
BA_ "GenSigSNA" SG_ 1011 EC_Cluster2 "0h";
BA_ "GenSigSendType" SG_ 1012 EC_ECUCfg5_Stat 5;
BA_ "GenSigCycleTime" SG_ 1012 EC_ECUCfg5_Stat 2000;
BA_ "FlexKomSigStartValue" SG_ 1012 EC_ECUCfg5_Stat "03h";
BA_ "GenSigStartValue" SG_ 1012 EC_ECUCfg5_Stat 3;
BA_ "FlexKomSID" SG_ 1012 EC_ECUCfg5_Stat 1062;
BA_ "FlexKomSigStartPos" SG_ 1012 EC_ECUCfg5_Stat 1;
BA_ "FlexKomSigLaenge" SG_ 1012 EC_ECUCfg5_Stat 2;
BA_ "FlexKomSigName" SG_ 1012 EC_ECUCfg5_Stat "EC_ECUCfg5_Stat";
BA_ "FlexKomComment" SG_ 1012 EC_ECUCfg5_Stat "ECU Configuration messages status 5";
BA_ "FlexKomIsMotorola" SG_ 1012 EC_ECUCfg5_Stat 1;
BA_ "GenSigSNA" SG_ 1012 EC_ECUCfg5_Stat "3h";
BA_ "GenSigSendType" SG_ 1012 EC_WirelessA 5;
BA_ "GenSigCycleTime" SG_ 1012 EC_WirelessA 2000;
BA_ "FlexKomSigStartValue" SG_ 1012 EC_WirelessA "000000h";
BA_ "FlexKomSID" SG_ 1012 EC_WirelessA 895;
BA_ "FlexKomSigStartPos" SG_ 1012 EC_WirelessA 7;
BA_ "FlexKomSigLaenge" SG_ 1012 EC_WirelessA 24;
BA_ "FlexKomSigName" SG_ 1012 EC_WirelessA "EC_Wireless";
BA_ "FlexKomComment" SG_ 1012 EC_WirelessA "Wireless ecu configuration";
BA_ "FlexKomIsMotorola" SG_ 1012 EC_WirelessA 1;
BA_ "GenSigSNA" SG_ 1012 EC_WirelessA "0h";
BA_ "GenSigSendType" SG_ 1012 EC_WirelessB 5;
BA_ "GenSigCycleTime" SG_ 1012 EC_WirelessB 2000;
BA_ "FlexKomSigStartValue" SG_ 1012 EC_WirelessB "000000h";
BA_ "FlexKomSID" SG_ 1012 EC_WirelessB 895;
BA_ "FlexKomSigStartPos" SG_ 1012 EC_WirelessB 7;
BA_ "FlexKomSigLaenge" SG_ 1012 EC_WirelessB 24;
BA_ "FlexKomSigName" SG_ 1012 EC_WirelessB "EC_Wireless";
BA_ "FlexKomComment" SG_ 1012 EC_WirelessB "Wireless ecu configuration";
BA_ "FlexKomIsMotorola" SG_ 1012 EC_WirelessB 1;
BA_ "GenSigSNA" SG_ 1012 EC_WirelessB "0h";
BA_ "GenSigSendType" SG_ 1012 EC_Doors 5;
BA_ "GenSigCycleTime" SG_ 1012 EC_Doors 2000;
BA_ "FlexKomSigStartValue" SG_ 1012 EC_Doors "000000h";
BA_ "FlexKomSID" SG_ 1012 EC_Doors 893;
BA_ "FlexKomSigStartPos" SG_ 1012 EC_Doors 31;
BA_ "FlexKomSigLaenge" SG_ 1012 EC_Doors 24;
BA_ "FlexKomSigName" SG_ 1012 EC_Doors "EC_Doors";
BA_ "FlexKomComment" SG_ 1012 EC_Doors "Doors ecu configuration";
BA_ "FlexKomIsMotorola" SG_ 1012 EC_Doors 1;
BA_ "GenSigSNA" SG_ 1012 EC_Doors "0h";
BA_ "GenSigSendType" SG_ 1012 EC_Memory 5;
BA_ "GenSigCycleTime" SG_ 1012 EC_Memory 2000;
BA_ "FlexKomSigStartValue" SG_ 1012 EC_Memory "0000h";
BA_ "FlexKomSID" SG_ 1012 EC_Memory 894;
BA_ "FlexKomSigStartPos" SG_ 1012 EC_Memory 55;
BA_ "FlexKomSigLaenge" SG_ 1012 EC_Memory 16;
BA_ "FlexKomSigName" SG_ 1012 EC_Memory "EC_Memory";
BA_ "FlexKomComment" SG_ 1012 EC_Memory "Memory ecu configuration";
BA_ "FlexKomIsMotorola" SG_ 1012 EC_Memory 1;
BA_ "GenSigSNA" SG_ 1012 EC_Memory "0h";
VAL_ 999 BU_NET_CFG_STAT_PT 3 "SNA" 2 "NA1" 1 "PROGAMMED" 0 "NA" ;
VAL_ 1000 VC_VehCfg1_Stat 3 "SNA" 2 "REQUEST_DATA" 1 "PROGAMMED" 0 "NA" ;
VAL_ 1000 VC_MODEL_YEAR 63 "SNA" ;
VAL_ 1000 VC_VEH_LINE 255 "SNA" 83 "VEH_UT" 82 "VEH_UF" 81 "VEH_KL" 80 "VEH_PF" 50 "VEH_M157" 47 "VEH_WS" 46 "VEH_WM" 45 "VEH_RU" 44 "VEH_LA" 43 "VEH_ZD" 42 "VEH_M156" 41 "VEH_LD" 39 "VEH_DX" 35 "VEH_WD" 34 "VEH_DJ" 33 "VEH_DP" 32 "VEH_DD" 31 "VEH_D2" 29 "VEH_DS" 22 "VEH_JC" 2 "VEH_LX" 1 "VEH_WK" 0 "VEH_NONE" ;
VAL_ 1000 VC_COUNTRY 31 "COUNTRY_SNA" 21 "ECE" 20 "S_KOR" 17 "EGYPT" 16 "CHINA" 15 "BRZ" 14 "MEX" 13 "VEN" 12 "GULF" 11 "IND" 10 "AUS" 9 "MLY" 8 "SWISS" 7 "GER" 6 "JPN" 5 "GB" 4 "CND" 3 "EU" 2 "USA" 0 "ROW" ;
VAL_ 1000 VC_LHD_RHD 3 "SNA" 2 "RHD" 1 "LHD" 0 "NA" ;
VAL_ 1000 VC_XWD 3 "4WD" 2 "ALLWD" 1 "2RR" 0 "2FT" ;
VAL_ 1000 VC_BODY_STYLE 15 "BODY_SNA" 8 "BODY_4DMP" 7 "BODY_4DP" 6 "BODY_2DP" 5 "BODY_4DH" 4 "BODY_WAGON" 3 "BODY_CONV" 2 "BODY_2DS" 1 "BODY_4DS" 0 "BODY_NONE" ;
VAL_ 1000 VC_MAX_VEH_SPD 255 "SNA" ;
VAL_ 1000 VC_ShftrTyp 15 "SNA" 14 "TYPE_PS5" 13 "TYPE_MS7" 12 "TYPE_MS7S" 11 "TYPE_RS4" 10 "TYPE_MS7M156" 9 "TYPE_MS7D" 8 "TYPE_ERS4ESW" 7 "TYPE_RS5L" 6 "TYPE_RS5S" 5 "TYPE_RS5M" 4 "TYPE_AS5" 3 "TYPE_ERS5" 2 "TYPE_AS4" 1 "TYPE_ERS4" 0 "TYPE_NA" ;
VAL_ 1000 VC_PTS_DispTyp 7 "SNA" 2 "AUDIO_DISP" 1 "CCN_DISP" 0 "HEAD_DISP" ;
VAL_ 1000 VC_SpecialPKG 255 "SNA" 0 "NONE" ;
VAL_ 1000 VC_PTS_Config 3 "SEMI" 1 "FRT_REAR" 0 "REAR" ;
VAL_ 1001 VC_VehCfg2_Stat 3 "SNA" 2 "REQUEST_DATA" 1 "PROGAMMED" 0 "NA" ;
VAL_ 1001 VC_PwrIvtrTyp 2 "LchSw" 1 "MtrySw" 0 "NoPwrIvtr" ;
VAL_ 1001 VC_MaseratiMd 3 "SNA" 2 "RACE" 1 "GTS" 0 "NORMAL" ;
VAL_ 1001 VC_SpecialPKG_IC 255 "SNA" 247 "VARVATOS" 246 "DODGE_100" 6 "Hellcat" 5 "MOPAR" 4 "PKG_SUPERBEE" 3 "PKG_BEATS" 2 "PKG_300S" 1 "PKG_70JP" 0 "NONE" ;
VAL_ 1001 VC_ShftInd_Prsnt 3 "PGSI" 2 "PSI" 1 "GSI" 0 "NONE" ;
VAL_ 1001 VC_MaxLdPressRrTr 255 "SNA" ;
VAL_ 1001 VC_MaxLdPressFtTr 255 "SNA" ;
VAL_ 1001 VC_LgtLdPressRrTr 255 "SNA" ;
VAL_ 1001 VC_LgtLdPressFtTr 255 "SNA" ;
VAL_ 1002 VC_VehCfg3_Stat 3 "SNA" 2 "REQUEST_DATA" 1 "PROGAMMED" 0 "NA" ;
VAL_ 1002 VC_TcaseTyp 15 "Tcase_256_3022" 14 "Tcase_156" 13 "Tcase_BW4440" 12 "Tcase_271_5" 11 "Tcase_273" 10 "BW4447_49_WS" 9 "Tcase_243" 8 "BW4447_WOS" 7 "Tcase_241" 6 "Tcase_246" 5 "Tcase_BW4446" 4 "Tcase_BW4444" 3 "Tcase_253_1522" 2 "BW4445_46_48_WS" 1 "TCASE_143_144" 0 "NOT_PRSNT" ;
VAL_ 1002 VC_WHL_BASE 3 "SNA" 2 "XLONG" 1 "LONG" 0 "SHORT" ;
VAL_ 1002 VC_WIN_EXPR_FEAT 3 "WIN_EXPR_NN" 2 "WIN_EXPR_ALL" 1 "WIN_EXPR_FT" 0 "WIN_EXPR_DRV" ;
VAL_ 1002 VC_ChassisType 127 "SNA" ;
VAL_ 1002 VC_HVAC_Config 15 "SNA" 6 "2_ZN_MTC_p_RR" 5 "2_ZN_ATC_p_RR" 4 "2_ZN_ATC" 3 "2_ZN_MTC" 2 "1_ZN_ATC" 1 "1_ZN_MTC_p_RR" 0 "1_ZN_MTC" ;
VAL_ 1002 VC_VEH_BRAND 15 "SNA" 12 "RAM" 11 "MASERATI" 10 "LANCIA" 9 "FIAT" 8 "ALPHA" 7 "FREIGHTLINER" 6 "VOLKSWAGEN" 5 "MITSUBISHI" 4 "MERCEDES_BENZ" 3 "JEEP" 2 "DODGE" 1 "CHRYSLER" ;
VAL_ 1002 VC_Liftgate_Trunk 3 "SNA" 2 "MANUAL_LG" 1 "PLG" 0 "TRUNK" ;
VAL_ 1003 VC_TCASE_HI_RATIO 16383 "SNA" ;
VAL_ 1003 VC_VehCfg4_Stat 3 "SNA" 2 "REQUEST_DATA" 1 "PROGAMMED" 0 "NA" ;
VAL_ 1003 VC_AXLE_RATIO 65535 "SNA" ;
VAL_ 1003 VC_TCASE_LO_RATIO 65535 "SNA" ;
VAL_ 1003 VC_TIRE_CIRCUMF 65535 "SNA" ;
VAL_ 1004 VC_BU_VehCfg1_Stat 3 "SNA" 2 "NA1" 1 "PROGAMMED" 0 "NA" ;
VAL_ 1004 VC_BU_MODEL_YEAR 63 "SNA" ;
VAL_ 1004 VC_BU_VEH_LINE 255 "SNA" 83 "VEH_UT" 82 "VEH_UF" 81 "VEH_KL" 80 "VEH_PF" 50 "VEH_M157" 47 "VEH_WS" 46 "VEH_WM" 45 "VEH_RU" 44 "VEH_LA" 43 "VEH_ZD" 42 "VEH_M156" 41 "VEH_LD" 39 "VEH_DX" 35 "VEH_WD" 34 "VEH_DJ" 33 "VEH_DP" 32 "VEH_DD" 31 "VEH_D2" 29 "VEH_DS" 22 "VEH_JC" 2 "VEH_LX" 1 "VEH_WK" 0 "VEH_NONE" ;
VAL_ 1004 VC_BU_COUNTRY 31 "COUNTRY_SNA" 21 "ECE" 20 "S_KOR" 17 "EGYPT" 16 "CHINA" 15 "BRZ" 14 "MEX" 13 "VEN" 12 "GULF" 11 "IND" 10 "AUS" 9 "MLY" 8 "SWISS" 7 "GER" 6 "JPN" 5 "GB" 4 "CND" 3 "EU" 2 "USA" 0 "ROW" ;
VAL_ 1004 VC_BU_LHD_RHD 3 "SNA" 2 "RHD" 1 "LHD" 0 "NA" ;
VAL_ 1004 VC_BU_RemStPrsnt 0 "SNA" ;
VAL_ 1004 VC_BU_XWD 3 "4WD" 2 "ALLWD" 1 "2RR" 0 "2FT" ;
VAL_ 1004 VC_BU_BODY_STYLE 15 "BODY_SNA" 8 "BODY_4DMP" 7 "BODY_4DP" 6 "BODY_2DP" 5 "BODY_4DH" 4 "BODY_WAGON" 3 "BODY_CONV" 2 "BODY_2DS" 1 "BODY_4DS" 0 "BODY_NONE" ;
VAL_ 1004 VC_BU_MAX_VEH_SPD 255 "SNA" ;
VAL_ 1004 VC_BU_ShftrTyp 15 "SNA" 14 "TYPE_PS5" 13 "TYPE_MS7" 12 "TYPE_MS7S" 11 "TYPE_RS4" 10 "TYPE_MS7M156" 9 "TYPE_MS7D" 8 "TYPE_ERS4ESW" 7 "TYPE_RS5L" 6 "TYPE_RS5S" 5 "TYPE_RS5M" 4 "TYPE_AS5" 3 "TYPE_ERS5" 2 "TYPE_AS4" 1 "TYPE_ERS4" 0 "TYPE_NA" ;
VAL_ 1004 VC_BU_PTS_DispTyp 7 "SNA" 2 "AUDIO_DISP" 1 "CCN_DISP" 0 "HEAD_DISP" ;
VAL_ 1004 VC_BU_SpecialPKG 255 "SNA" 0 "NONE" ;
VAL_ 1004 VC_BU_PTS_Config 3 "SEMI" 1 "FRT_REAR" 0 "REAR" ;
VAL_ 1005 VC_BU_VehCfg2_Stat 3 "SNA" 2 "NA1" 1 "PROGAMMED" 0 "NA" ;
VAL_ 1005 VC_BU_PwrIvtrTyp 2 "LchSw" 1 "MtrySw" 0 "NoPwrIvtr" ;
VAL_ 1005 VC_BU_MaseratiMd 3 "SNA" 2 "RACE" 1 "GTS" 0 "NORMAL" ;
VAL_ 1005 VC_BU_SpecialPKG_IC 255 "SNA" 247 "VARVATOS" 246 "DODGE_100" 6 "Hellcat" 5 "MOPAR" 4 "PKG_SUPERBEE" 3 "PKG_BEATS" 2 "PKG_300S" 1 "PKG_70JP" 0 "NONE" ;
VAL_ 1005 VC_BU_ShftInd_Prsnt 3 "PGSI" 2 "PSI" 1 "GSI" 0 "NONE" ;
VAL_ 1005 VC_BU_MaxLdPressRrTr 255 "SNA" ;
VAL_ 1005 VC_BU_MaxLdPressFtTr 255 "SNA" ;
VAL_ 1005 VC_BU_LgtLdPressRrTr 255 "SNA" ;
VAL_ 1005 VC_BU_LgtLdPressFtTr 255 "SNA" ;
VAL_ 1006 VC_BU_VehCfg3_Stat 3 "SNA" 2 "NA1" 1 "PROGAMMED" 0 "NA" ;
VAL_ 1006 VC_BU_TcaseTyp 15 "Tcase_256_3022" 14 "Tcase_156" 13 "Tcase_BW4440" 12 "Tcase_271_5" 11 "Tcase_273" 10 "BW4447_49_WS" 9 "Tcase_243" 8 "BW4447_WOS" 7 "Tcase_241" 6 "Tcase_246" 5 "Tcase_BW4446" 4 "Tcase_BW4444" 3 "Tcase_253_1522" 2 "BW4445_46_48_WS" 1 "TCASE_143_144" 0 "NOT_PRSNT" ;
VAL_ 1006 VC_BU_WHL_BASE 3 "SNA" 2 "XLONG" 1 "LONG" 0 "SHORT" ;
VAL_ 1006 VC_BU_ELV_PRSNT 0 "SNA" ;
VAL_ 1006 VC_BU_WIN_EXPR_FEAT 3 "WIN_EXPR_NN" 2 "WIN_EXPR_ALL" 1 "WIN_EXPR_FT" 0 "WIN_EXPR_DRV" ;
VAL_ 1006 VC_BU_ChassisType 127 "SNA" ;
VAL_ 1006 VC_BU_HVAC_Config 15 "SNA" 6 "2_ZN_MTC_p_RR" 5 "2_ZN_ATC_p_RR" 4 "2_ZN_ATC" 3 "2_ZN_MTC" 2 "1_ZN_ATC" 1 "1_ZN_MTC_p_RR" 0 "1_ZN_MTC" ;
VAL_ 1006 VC_BU_VEH_BRAND 15 "SNA" 12 "RAM" 11 "MASERATI" 10 "LANCIA" 9 "FIAT" 8 "ALPHA" 7 "FREIGHTLINER" 6 "VOLKSWAGEN" 5 "MITSUBISHI" 4 "MERCEDES_BENZ" 3 "JEEP" 2 "DODGE" 1 "CHRYSLER" ;
VAL_ 1006 VC_BU_Liftgate_Trunk 3 "SNA" 2 "MANUAL_LG" 1 "PLG" 0 "TRUNK" ;
VAL_ 1007 VC_BU_TCASE_HI_RATIO 16383 "SNA" ;
VAL_ 1007 VC_BU_VehCfg4_Stat 3 "SNA" 2 "NA1" 1 "PROGAMMED" 0 "NA" ;
VAL_ 1007 VC_BU_AXLE_RATIO 65535 "SNA" ;
VAL_ 1007 VC_BU_TCASE_LO_RATIO 65535 "SNA" ;
VAL_ 1007 VC_BU_TIRE_CIRCUMF 65535 "SNA" ;
VAL_ 1008 EC_ECUCfg1_Stat 3 "SNA" 2 "REQUEST_DATA" 1 "PROGAMMED" 0 "NA" ;
VAL_ 1009 EC_ECUCfg2_Stat 3 "SNA" 2 "REQUEST_DATA" 1 "PROGAMMED" 0 "NA" ;
VAL_ 1010 EC_ECUCfg3_Stat 3 "SNA" 2 "REQUEST_DATA" 1 "PROGAMMED" 0 "NA" ;
VAL_ 1011 EC_ECUCfg4_Stat 3 "SNA" 2 "REQUEST_DATA" 1 "PROGAMMED" 0 "NA" ;
VAL_ 1012 EC_ECUCfg5_Stat 3 "SNA" 2 "REQUEST_DATA" 1 "PROGAMMED" 0 "NA" ;
